VERSION "HNNBNNNYNNNNNNNNNNNNNNNNNNNNNNNNNNNNNNNNNN/4/%%%/4/'%**4NNN///"

NS_ :

BS_:

BU_: Airbag_MQB BAP_Tester_MQB BMS_MQB Datenlogger_MQB Gateway_MQB Getriebe_DQ_Hybrid_MQB Getriebe_DQ_MQB LEH_MQB Motor_Diesel_MQB Motor_Hybrid_MQB Motor_Otto_MQB SAK_MQB Waehlhebel_MQB

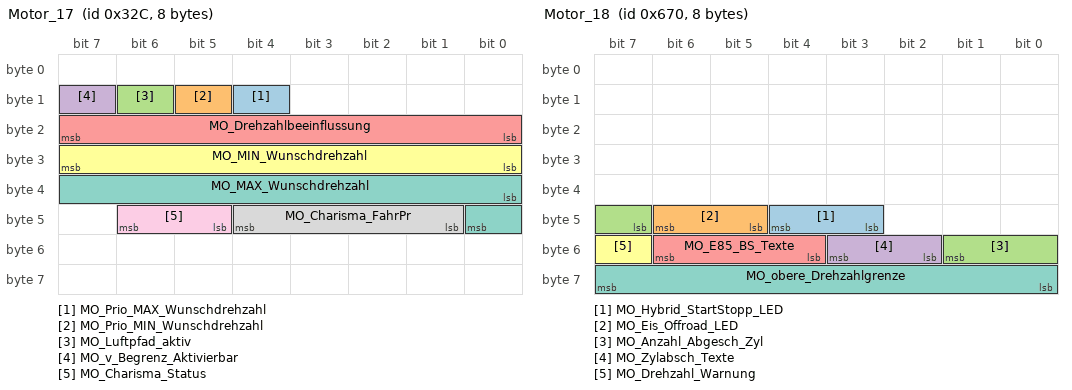
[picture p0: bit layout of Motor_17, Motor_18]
BO_ 812 Motor_17: 8 Motor_Diesel_MQB
 SG_ MO_Prio_MAX_Wunschdrehzahl : 12|1@1+ (1,0) [0|1] ""  Getriebe_DQ_Hybrid_MQB,Getriebe_DQ_MQB
 SG_ MO_Prio_MIN_Wunschdrehzahl : 13|1@1+ (1,0) [0|1] ""  Getriebe_DQ_Hybrid_MQB,Getriebe_DQ_MQB
 SG_ MO_Luftpfad_aktiv : 14|1@1+ (1,0) [0|1] "" Vector__XXX
 SG_ MO_v_Begrenz_Aktivierbar : 15|1@1+ (1,0) [0|1] "" Vector__XXX
 SG_ MO_Drehzahlbeeinflussung : 16|8@1+ (0.39,0) [0|99.45] "Unit_PerCent"  Getriebe_DQ_Hybrid_MQB,Getriebe_DQ_MQB
 SG_ MO_MIN_Wunschdrehzahl : 24|8@1+ (25,0) [0|6350] "Unit_MinutInver"  Getriebe_DQ_Hybrid_MQB,Getriebe_DQ_MQB
 SG_ MO_MAX_Wunschdrehzahl : 32|9@1+ (25,0) [0|12750] "Unit_MinutInver"  Getriebe_DQ_Hybrid_MQB,Getriebe_DQ_MQB
 SG_ MO_Charisma_FahrPr : 41|4@1+ (1,0) [0|15] ""  Gateway_MQB
 SG_ MO_Charisma_Status : 45|2@1+ (1,0) [0|3] ""  Gateway_MQB

BO_ 1648 Motor_18: 8 Motor_Diesel_MQB
 SG_ MO_Hybrid_StartStopp_LED : 43|2@1+ (1,0) [0|3] ""  Gateway_MQB
 SG_ MO_Eis_Offroad_LED : 45|2@1+ (1,0) [0|3] ""  Gateway_MQB
 SG_ MO_Anzahl_Abgesch_Zyl : 47|3@1+ (1,0) [0|7] ""  Gateway_MQB
 SG_ MO_Zylabsch_Texte : 50|2@1+ (1,0) [0|3] ""  Gateway_MQB
 SG_ MO_E85_BS_Texte : 52|3@1+ (1,0) [0|7] ""  Gateway_MQB
 SG_ MO_Drehzahl_Warnung : 55|1@1+ (1,0) [0|1] ""  Gateway_MQB
 SG_ MO_obere_Drehzahlgrenze : 56|8@1+ (50,0) [50|12750] "Unit_MinutInver"  Gateway_MQB,Getriebe_DQ_Hybrid_MQB,Getriebe_DQ_MQB

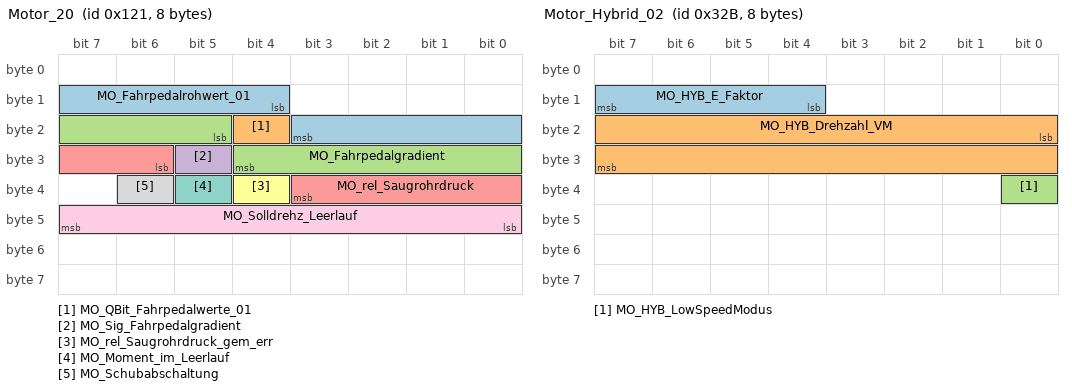
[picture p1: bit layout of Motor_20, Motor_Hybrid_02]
BO_ 289 Motor_20: 8 Motor_Diesel_MQB
 SG_ MO_Fahrpedalrohwert_01 : 12|8@1+ (0.4,0) [0|101.6] "Unit_PerCent"  Airbag_MQB,Gateway_MQB,Getriebe_DQ_Hybrid_MQB,Getriebe_DQ_MQB
 SG_ MO_QBit_Fahrpedalwerte_01 : 20|1@1+ (1,0) [0|1] ""  Airbag_MQB,Gateway_MQB,Getriebe_DQ_Hybrid_MQB,Getriebe_DQ_MQB
 SG_ MO_Fahrpedalgradient : 21|8@1+ (25,0) [0|6350] "Unit_PerCentPerSecon"  Airbag_MQB,Gateway_MQB,Getriebe_DQ_Hybrid_MQB,Getriebe_DQ_MQB
 SG_ MO_Sig_Fahrpedalgradient : 29|1@1+ (1,0) [0|1] ""  Airbag_MQB,Gateway_MQB,Getriebe_DQ_Hybrid_MQB,Getriebe_DQ_MQB
 SG_ MO_rel_Saugrohrdruck : 30|6@1+ (18,0) [0|1116] "Unit_MilliBar"  Gateway_MQB
 SG_ MO_rel_Saugrohrdruck_gem_err : 36|1@1+ (1,0) [0|1] ""  Gateway_MQB
 SG_ MO_Moment_im_Leerlauf : 37|1@1+ (1,0) [0|1] ""  Gateway_MQB,Getriebe_DQ_Hybrid_MQB,Getriebe_DQ_MQB
 SG_ MO_Schubabschaltung : 38|1@1+ (1,0) [0|1] ""  Gateway_MQB
 SG_ MO_Solldrehz_Leerlauf : 40|8@1+ (10,0) [0|2540] "Unit_MinutInver"  Gateway_MQB,Getriebe_DQ_Hybrid_MQB,Getriebe_DQ_MQB

BO_ 967 Motor_26: 8 Motor_Diesel_MQB
 SG_ MO_Kuehlerluefter_MUX M : 0|1@1+ (1,0) [0|1] ""  Gateway_MQB,Getriebe_DQ_Hybrid_MQB,Getriebe_DQ_MQB
 SG_ MO_Kuehlerluefter_1 m0 : 1|7@1+ (1,0) [0|100] "Unit_PerCent"  Gateway_MQB,Getriebe_DQ_Hybrid_MQB,Getriebe_DQ_MQB
 SG_ MO_Kuehlerluefter_2 m1 : 1|7@1+ (1,0) [0|100] "Unit_PerCent"  Gateway_MQB,Getriebe_DQ_Hybrid_MQB,Getriebe_DQ_MQB
 SG_ MO_HYB_Status_HV_Ladung : 8|3@1+ (1,0) [0|7] ""  Gateway_MQB
 SG_ WIV_Anzeige_aktiv : 12|1@1+ (1,0) [0|1] ""  Gateway_MQB
 SG_ WIV_Oelmin_Warn : 13|1@1+ (1,0) [0|1] ""  Gateway_MQB
 SG_ WIV_Sensorfehler : 14|1@1+ (1,0) [0|1] ""  Gateway_MQB
 SG_ WIV_Schieflage : 15|1@1+ (1,0) [0|1] ""  Gateway_MQB
 SG_ WIV_Oelstand : 16|4@1+ (12.5,0) [0|100] "Unit_PerCent"  Gateway_MQB
 SG_ MO_Zustand_HWP : 20|2@1+ (1,0) [0|3] ""  Gateway_MQB
 SG_ WIV_Oelsystem_aktiv : 24|1@1+ (1,0) [0|1] ""  Gateway_MQB
 SG_ WIV_nicht_betriebswarm : 25|1@1+ (1,0) [0|1] ""  Gateway_MQB
 SG_ WIV_Ueberfuell_Warn : 26|1@1+ (1,0) [0|1] ""  Gateway_MQB
 SG_ WIV_laufender_Motor : 27|1@1+ (1,0) [0|1] ""  Gateway_MQB
 SG_ MO_HYB_Text_1 : 28|1@1+ (1,0) [0|1] ""  Gateway_MQB
 SG_ MO_HYB_Text_2 : 29|1@1+ (1,0) [0|1] ""  Gateway_MQB
 SG_ MO_HYB_Text_3 : 30|1@1+ (1,0) [0|1] ""  Gateway_MQB
 SG_ MO_HYB_Text_4 : 31|1@1+ (1,0) [0|1] ""  Gateway_MQB
 SG_ MO_Text_Motorstart : 32|4@1+ (1,0) [0|15] ""  Gateway_MQB
 SG_ MO_HYB_Text_5 : 36|1@1+ (1,0) [0|1] ""  Gateway_MQB
 SG_ MO_HYB_Text_6 : 37|1@1+ (1,0) [0|1] ""  Gateway_MQB
 SG_ MO_HYB_Text_7 : 38|1@1+ (1,0) [0|1] ""  Gateway_MQB
 SG_ MO_Text_Partikelfil_Reg : 41|1@1+ (1,0) [0|1] ""  Gateway_MQB
 SG_ WIV_Oelmenge : 43|5@1+ (125,0) [0|3875] "Unit_MilliLiter"  Gateway_MQB
 SG_ MO_Systemlampe : 48|1@1+ (1,0) [0|1] ""  Gateway_MQB
 SG_ MO_OBD2_Lampe : 49|1@1+ (1,0) [0|1] ""  Gateway_MQB
 SG_ MO_Heissleuchte : 50|1@1+ (1,0) [0|1] ""  Gateway_MQB
 SG_ MO_Partikel_Lampe : 51|1@1+ (1,0) [0|1] ""  Gateway_MQB
 SG_ MO_Winterfahrprog : 52|1@1+ (1,0) [0|1] ""  Gateway_MQB,Getriebe_DQ_Hybrid_MQB,Getriebe_DQ_MQB
 SG_ WIV_Oelstand_nicht_vorhanden : 53|1@1+ (1,0) [0|1] ""  Gateway_MQB
 SG_ WIV_nachfuellanzeige_ein : 54|1@1+ (1,0) [0|1] ""  Gateway_MQB
 SG_ WIV_Ueberfuell_deaktiv : 55|1@1+ (1,0) [0|1] ""  Gateway_MQB
 SG_ WIV_Unterfuell_Warn : 56|1@1+ (1,0) [0|1] ""  Gateway_MQB
 SG_ MO_Tankdeckel_Lampe : 57|1@1+ (1,0) [0|1] ""  Gateway_MQB
 SG_ MO_Text_Tankdeckelwarn : 58|1@1+ (1,0) [0|1] ""  Gateway_MQB
 SG_ WIV_Oeldr_Warn_Motor : 60|1@1+ (1,0) [0|1] ""  Gateway_MQB

BO_ 1601 Motor_Code_01: 8 Motor_Diesel_MQB
 SG_ Motor_Code_01_CRC : 0|8@1+ (1,0) [0|255] ""  Gateway_MQB
 SG_ Motor_Code_01_BZ : 8|4@1+ (1,0) [0|15] ""  Gateway_MQB
 SG_ MO_Faktor_Momente_02 : 12|2@1+ (1,0) [0|3] ""  Gateway_MQB,Getriebe_DQ_Hybrid_MQB,Getriebe_DQ_MQB
 SG_ MO_Hybridfahrzeug : 14|2@1+ (1,0) [0|3] ""  Gateway_MQB
 SG_ MO_Code : 16|8@1+ (1,0) [0|255] ""  Gateway_MQB,SAK_MQB
 SG_ MO_Getriebe_Code : 24|6@1+ (1,0) [0|63] ""  Gateway_MQB
 SG_ MO_StartStopp_Codiert : 30|1@1+ (1,0) [0|1] ""  Gateway_MQB
 SG_ MO_Anzahl_Zyl : 32|4@1+ (1,0) [0|15] ""  Gateway_MQB
 SG_ MO_Kraftstoffart : 36|4@1+ (1,0) [0|15] ""  Gateway_MQB,Getriebe_DQ_Hybrid_MQB,Getriebe_DQ_MQB
 SG_ MO_Hubraum : 40|7@1+ (0.1,0) [0|12.7] "Unit_Liter"  Gateway_MQB
 SG_ MO_Ansaugsystem : 47|1@1+ (1,0) [0|1] ""  Gateway_MQB
 SG_ MO_Leistung : 48|9@1+ (1,0) [0|511] "Unit_KiloWatt"  Gateway_MQB
 SG_ MO_Abgastyp_EOBD : 57|1@1+ (1,0) [0|1] ""  BMS_MQB,Gateway_MQB,LEH_MQB
 SG_ MO_Abgastyp_OBD : 58|1@1+ (1,0) [0|1] ""  BMS_MQB,Gateway_MQB,LEH_MQB
 SG_ MO_DPF_verbaut : 59|1@1+ (1,0) [0|1] ""  Gateway_MQB
 SG_ TSK_Codierung : 60|3@1+ (1,0) [0|7] ""  Gateway_MQB,Getriebe_DQ_Hybrid_MQB,Getriebe_DQ_MQB
 SG_ MO_Einspritzart : 63|1@1+ (1,0) [0|1] ""  Gateway_MQB

BO_ 157 Motor_Hybrid_01: 8 Motor_Hybrid_MQB
 SG_ Motor_Hybrid_01_CRC : 0|8@1+ (1,0) [0|255] ""  Getriebe_DQ_Hybrid_MQB
 SG_ Motor_Hybrid_01_BZ : 8|4@1+ (1,0) [0|15] ""  BMS_MQB,Getriebe_DQ_Hybrid_MQB
 SG_ MO_HYB_IstStatusK0 : 12|2@1+ (1,0) [0|3] ""  Getriebe_DQ_Hybrid_MQB
 SG_ MO_HYB_max_ind_VM_Mom : 16|10@1+ (1,0) [0|1021] "Unit_NewtoMeter"  Getriebe_DQ_Hybrid_MQB
 SG_ MO_HYB_Zielzustand : 26|3@1+ (1,0) [0|7] ""  BMS_MQB,Getriebe_DQ_Hybrid_MQB
 SG_ MO_HYB_Startmodus : 29|3@1+ (1,0) [0|7] "" Vector__XXX
 SG_ MO_HYB_Startmodus_PQ3x : 32|1@1+ (1,0) [0|1] ""  Getriebe_DQ_Hybrid_MQB
 SG_ MO_HYB_Stoppmodus : 33|1@1+ (1,0) [0|1] ""  Getriebe_DQ_Hybrid_MQB
 SG_ MO_HYB_VM_Mom_oE : 40|10@1+ (1,-100) [-100|922] "Unit_NewtoMeter"  Getriebe_DQ_Hybrid_MQB
 SG_ MO_HYB_VM_aktiv : 50|1@1+ (1,0) [0|1] ""  Getriebe_DQ_Hybrid_MQB
 SG_ MO_HYB_Schaltverhinderung : 51|1@1+ (1,0) [0|1] ""  Getriebe_DQ_Hybrid_MQB
 SG_ MO_HYB_Selektor_Momverlauf_EM M : 53|3@1+ (1,0) [0|7] ""  Getriebe_DQ_Hybrid_MQB
 SG_ MO_HYB_Momverlauf_Rek m1 : 56|8@1+ (2,0) [0|510] "Unit_NewtoMeter"  Getriebe_DQ_Hybrid_MQB
 SG_ MO_HYB_KnickDZ_Rek m2 : 56|8@1+ (12.5,0) [0|3150] "Unit_MinutInver"  Getriebe_DQ_Hybrid_MQB
 SG_ MO_HYB_Momverlauf_EM m3 : 56|8@1+ (2,0) [0|510] "Unit_NewtoMeter"  Getriebe_DQ_Hybrid_MQB
 SG_ MO_HYB_KnickDZ_EM m4 : 56|8@1+ (12.5,0) [0|3150] "Unit_MinutInver"  Getriebe_DQ_Hybrid_MQB

BO_ 811 Motor_Hybrid_02: 8 Motor_Hybrid_MQB
 SG_ MO_HYB_E_Faktor : 12|4@1+ (1,0) [0|15] ""  Getriebe_DQ_Hybrid_MQB
 SG_ MO_HYB_Drehzahl_VM : 16|16@1+ (0.25,0) [0|16256] "Unit_MinutInver"  Getriebe_DQ_Hybrid_MQB
 SG_ MO_HYB_LowSpeedModus : 32|1@1+ (1,0) [0|1] ""  Getriebe_DQ_Hybrid_MQB

BO_ 16 MSG1_WFS_Anfrage: 8 Motor_Diesel_MQB
 SG_ WFS_MSG1_RND : 0|32@1+ (1,0) [0|4294967295] ""  Gateway_MQB
 SG_ WFS_MSG1_CRC : 32|32@1+ (1,0) [0|4294967295] ""  Gateway_MQB

BO_ 20 MSG2_WFS_Anfrage: 8 Vector__XXX
 SG_ WFS_MSG2_RND : 0|32@1+ (1,0) [0|4294967295] ""  Gateway_MQB
 SG_ WFS_MSG2_CRC : 32|32@1+ (1,0) [0|4294967295] ""  Gateway_MQB

BO_ 22 MSG3_WFS_Anfrage: 8 Vector__XXX
 SG_ WFS_MSG3_RND : 0|32@1+ (1,0) [0|4294967295] ""  Gateway_MQB
 SG_ WFS_MSG3_CRC : 32|32@1+ (1,0) [0|4294967295] ""  Gateway_MQB

BO_ 24 MSG4_WFS_Anfrage: 8 LEH_MQB
 SG_ WFS_MSG4_RND : 0|32@1+ (1,0) [0|4294967295] ""  Gateway_MQB
 SG_ WFS_MSG4_CRC : 32|32@1+ (1,0) [0|4294967295] ""  Gateway_MQB

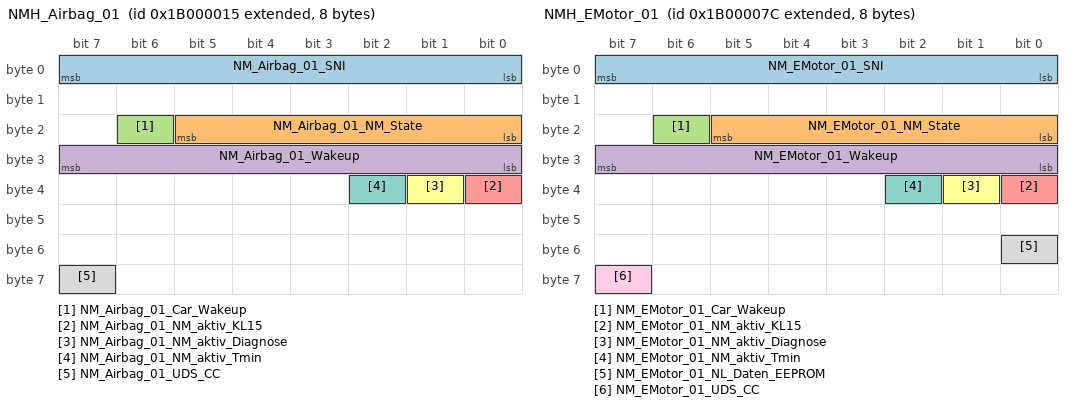
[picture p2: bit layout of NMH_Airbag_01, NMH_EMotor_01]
BO_ 2600468501 NMH_Airbag_01: 8 Airbag_MQB
 SG_ NM_Airbag_01_SNI : 0|8@1+ (1,0) [0|255] "" Vector__XXX
 SG_ NM_Airbag_01_NM_State : 16|6@1+ (1,0) [0|63] ""  BMS_MQB,Getriebe_DQ_Hybrid_MQB,Getriebe_DQ_MQB,LEH_MQB,Motor_Diesel_MQB,Motor_Hybrid_MQB,Motor_Otto_MQB
 SG_ NM_Airbag_01_Car_Wakeup : 22|1@1+ (1,0) [0|1] ""  Gateway_MQB
 SG_ NM_Airbag_01_Wakeup : 24|8@1+ (1,0) [0|255] "" Vector__XXX
 SG_ NM_Airbag_01_NM_aktiv_KL15 : 32|1@1+ (1,0) [0|1] "" Vector__XXX
 SG_ NM_Airbag_01_NM_aktiv_Diagnose : 33|1@1+ (1,0) [0|1] "" Vector__XXX
 SG_ NM_Airbag_01_NM_aktiv_Tmin : 34|1@1+ (1,0) [0|1] "" Vector__XXX
 SG_ NM_Airbag_01_UDS_CC : 63|1@1+ (1,0) [0|1] "" Vector__XXX

BO_ 2600468604 NMH_EMotor_01: 8 LEH_MQB
 SG_ NM_EMotor_01_SNI : 0|8@1+ (1,0) [0|255] "" Vector__XXX
 SG_ NM_EMotor_01_NM_State : 16|6@1+ (1,0) [0|63] ""  BMS_MQB,Getriebe_DQ_Hybrid_MQB,Getriebe_DQ_MQB,LEH_MQB,Motor_Diesel_MQB,Motor_Hybrid_MQB,Motor_Otto_MQB
 SG_ NM_EMotor_01_Car_Wakeup : 22|1@1+ (1,0) [0|1] ""  Gateway_MQB
 SG_ NM_EMotor_01_Wakeup : 24|8@1+ (1,0) [0|255] "" Vector__XXX
 SG_ NM_EMotor_01_NM_aktiv_KL15 : 32|1@1+ (1,0) [0|1] "" Vector__XXX
 SG_ NM_EMotor_01_NM_aktiv_Diagnose : 33|1@1+ (1,0) [0|1] "" Vector__XXX
 SG_ NM_EMotor_01_NM_aktiv_Tmin : 34|1@1+ (1,0) [0|1] "" Vector__XXX
 SG_ NM_EMotor_01_NL_Daten_EEPROM : 48|1@1+ (1,0) [0|1] "" Vector__XXX
 SG_ NM_EMotor_01_UDS_CC : 63|1@1+ (1,0) [0|1] "" Vector__XXX

BO_ 2600468496 NMH_Gateway: 8 Gateway_MQB
 SG_ NM_Gateway_SNI : 0|8@1+ (1,0) [0|255] "" Vector__XXX
 SG_ NM_Gateway_NM_State : 16|6@1+ (1,0) [0|63] ""  BMS_MQB,Getriebe_DQ_Hybrid_MQB,Getriebe_DQ_MQB,LEH_MQB,Motor_Diesel_MQB,Motor_Hybrid_MQB,Motor_Otto_MQB
 SG_ NM_Gateway_Car_Wakeup : 22|1@1+ (1,0) [0|1] "" Vector__XXX
 SG_ NM_Gateway_Wakeup : 24|8@1+ (1,0) [0|255] "" Vector__XXX
 SG_ NM_Gateway_NM_aktiv_KL15 : 32|1@1+ (1,0) [0|1] "" Vector__XXX
 SG_ NM_Gateway_NM_aktiv_Diagnose : 33|1@1+ (1,0) [0|1] "" Vector__XXX
 SG_ NM_Gateway_NM_aktiv_Tmin : 34|1@1+ (1,0) [0|1] "" Vector__XXX
 SG_ NM_Gateway_ACAN_Aktivitaet : 35|1@1+ (1,0) [0|1] "" Vector__XXX
 SG_ NM_Gateway_FCAN_Aktivitaet : 36|1@1+ (1,0) [0|1] "" Vector__XXX
 SG_ NM_Gateway_KCAN_Aktivitaet : 37|1@1+ (1,0) [0|1] "" Vector__XXX
 SG_ NM_Gateway_ICAN_Aktivitaet : 38|1@1+ (1,0) [0|1] "" Vector__XXX
 SG_ NM_Gateway_DiagCAN_Aktivitaet : 39|1@1+ (1,0) [0|1] "" Vector__XXX
 SG_ NM_Gateway_ECAN_Aktivitaet : 40|1@1+ (1,0) [0|1] "" Vector__XXX
 SG_ NM_Gateway_Energie_LIN_Aktivi000 : 41|1@1+ (1,0) [0|1] "" Vector__XXX
 SG_ NM_Gateway_Bedien_LIN_Aktivitaet : 42|1@1+ (1,0) [0|1] "" Vector__XXX
 SG_ NM_Gateway_EM_Aktivitaet : 43|1@1+ (1,0) [0|1] "" Vector__XXX
 SG_ NM_Gateway_NL_EM : 48|1@1+ (1,0) [0|1] "" Vector__XXX
 SG_ NM_Gateway_NL_Shutdown : 49|1@1+ (1,0) [0|1] "" Vector__XXX
 SG_ NM_Gateway_NL_Spg_Messung : 50|1@1+ (1,0) [0|1] "" Vector__XXX
 SG_ NM_Gateway_NL_Wakeup_Monitor : 51|1@1+ (1,0) [0|1] "" Vector__XXX
 SG_ NM_Gateway_UDS_CC : 63|1@1+ (1,0) [0|1] "" Vector__XXX

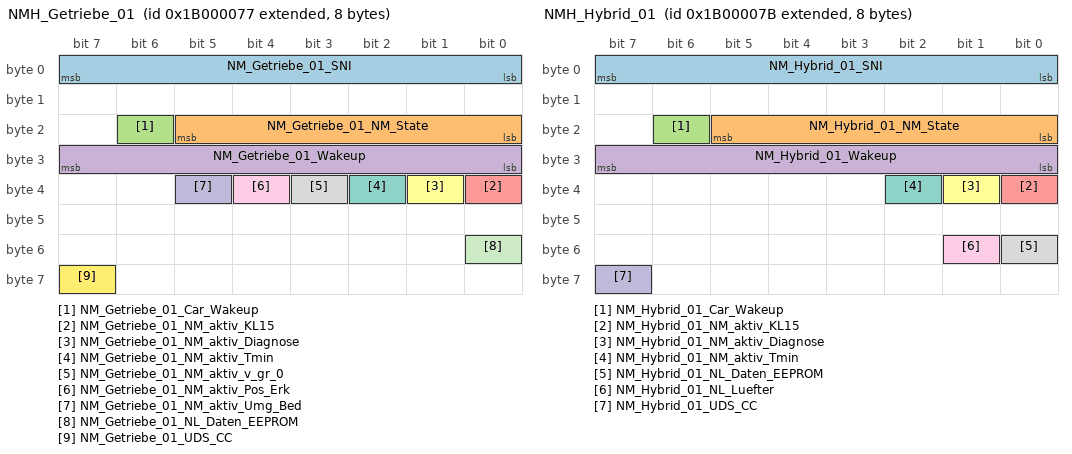
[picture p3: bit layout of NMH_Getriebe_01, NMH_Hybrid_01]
BO_ 2600468599 NMH_Getriebe_01: 8 Getriebe_DQ_Hybrid_MQB
 SG_ NM_Getriebe_01_SNI : 0|8@1+ (1,0) [0|255] "" Vector__XXX
 SG_ NM_Getriebe_01_NM_State : 16|6@1+ (1,0) [0|63] ""  BMS_MQB,Getriebe_DQ_Hybrid_MQB,Getriebe_DQ_MQB,LEH_MQB,Motor_Diesel_MQB,Motor_Hybrid_MQB,Motor_Otto_MQB
 SG_ NM_Getriebe_01_Car_Wakeup : 22|1@1+ (1,0) [0|1] ""  Gateway_MQB
 SG_ NM_Getriebe_01_Wakeup : 24|8@1+ (1,0) [0|255] "" Vector__XXX
 SG_ NM_Getriebe_01_NM_aktiv_KL15 : 32|1@1+ (1,0) [0|1] "" Vector__XXX
 SG_ NM_Getriebe_01_NM_aktiv_Diagnose : 33|1@1+ (1,0) [0|1] "" Vector__XXX
 SG_ NM_Getriebe_01_NM_aktiv_Tmin : 34|1@1+ (1,0) [0|1] "" Vector__XXX
 SG_ NM_Getriebe_01_NM_aktiv_v_gr_0 : 35|1@1+ (1,0) [0|1] "" Vector__XXX
 SG_ NM_Getriebe_01_NM_aktiv_Pos_Erk : 36|1@1+ (1,0) [0|1] "" Vector__XXX
 SG_ NM_Getriebe_01_NM_aktiv_Umg_Bed : 37|1@1+ (1,0) [0|1] "" Vector__XXX
 SG_ NM_Getriebe_01_NL_Daten_EEPROM : 48|1@1+ (1,0) [0|1] "" Vector__XXX
 SG_ NM_Getriebe_01_UDS_CC : 63|1@1+ (1,0) [0|1] "" Vector__XXX

BO_ 2600468603 NMH_Hybrid_01: 8 BMS_MQB
 SG_ NM_Hybrid_01_SNI : 0|8@1+ (1,0) [0|255] "" Vector__XXX
 SG_ NM_Hybrid_01_NM_State : 16|6@1+ (1,0) [0|63] ""  BMS_MQB,Getriebe_DQ_Hybrid_MQB,Getriebe_DQ_MQB,LEH_MQB,Motor_Diesel_MQB,Motor_Hybrid_MQB,Motor_Otto_MQB
 SG_ NM_Hybrid_01_Car_Wakeup : 22|1@1+ (1,0) [0|1] ""  Gateway_MQB
 SG_ NM_Hybrid_01_Wakeup : 24|8@1+ (1,0) [0|255] "" Vector__XXX
 SG_ NM_Hybrid_01_NM_aktiv_KL15 : 32|1@1+ (1,0) [0|1] "" Vector__XXX
 SG_ NM_Hybrid_01_NM_aktiv_Diagnose : 33|1@1+ (1,0) [0|1] "" Vector__XXX
 SG_ NM_Hybrid_01_NM_aktiv_Tmin : 34|1@1+ (1,0) [0|1] "" Vector__XXX
 SG_ NM_Hybrid_01_NL_Daten_EEPROM : 48|1@1+ (1,0) [0|1] "" Vector__XXX
 SG_ NM_Hybrid_01_NL_Luefter : 49|1@1+ (1,0) [0|1] "" Vector__XXX
 SG_ NM_Hybrid_01_UDS_CC : 63|1@1+ (1,0) [0|1] "" Vector__XXX

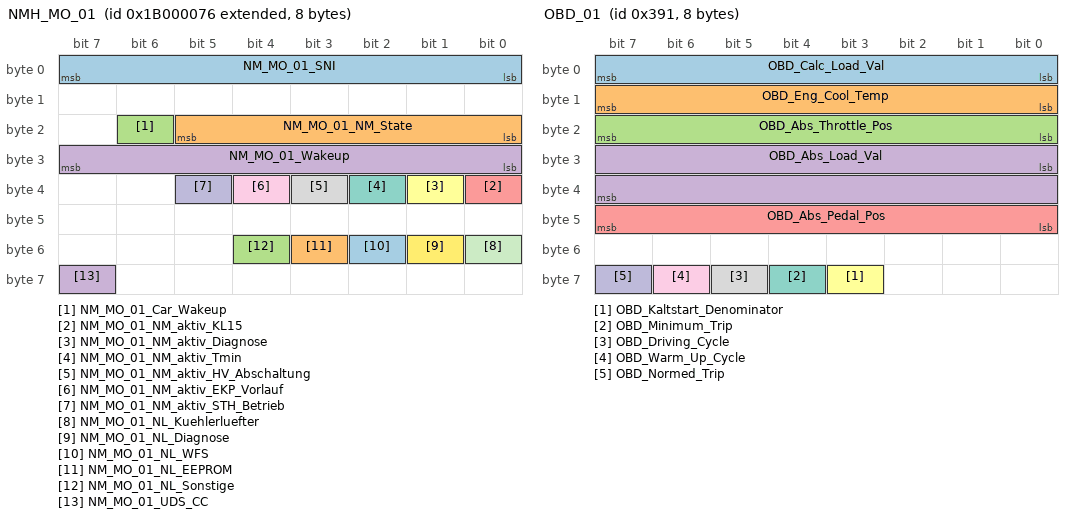
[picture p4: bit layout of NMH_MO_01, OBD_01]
BO_ 2600468598 NMH_MO_01: 8 Motor_Diesel_MQB
 SG_ NM_MO_01_SNI : 0|8@1+ (1,0) [0|255] "" Vector__XXX
 SG_ NM_MO_01_NM_State : 16|6@1+ (1,0) [0|63] ""  BMS_MQB,Getriebe_DQ_Hybrid_MQB,Getriebe_DQ_MQB,LEH_MQB,Motor_Diesel_MQB,Motor_Hybrid_MQB,Motor_Otto_MQB
 SG_ NM_MO_01_Car_Wakeup : 22|1@1+ (1,0) [0|1] ""  Gateway_MQB
 SG_ NM_MO_01_Wakeup : 24|8@1+ (1,0) [0|255] "" Vector__XXX
 SG_ NM_MO_01_NM_aktiv_KL15 : 32|1@1+ (1,0) [0|1] "" Vector__XXX
 SG_ NM_MO_01_NM_aktiv_Diagnose : 33|1@1+ (1,0) [0|1] "" Vector__XXX
 SG_ NM_MO_01_NM_aktiv_Tmin : 34|1@1+ (1,0) [0|1] "" Vector__XXX
 SG_ NM_MO_01_NM_aktiv_HV_Abschaltung : 35|1@1+ (1,0) [0|1] "" Vector__XXX
 SG_ NM_MO_01_NM_aktiv_EKP_Vorlauf : 36|1@1+ (1,0) [0|1] "" Vector__XXX
 SG_ NM_MO_01_NM_aktiv_STH_Betrieb : 37|1@1+ (1,0) [0|1] "" Vector__XXX
 SG_ NM_MO_01_NL_Kuehlerluefter : 48|1@1+ (1,0) [0|1] "" Vector__XXX
 SG_ NM_MO_01_NL_Diagnose : 49|1@1+ (1,0) [0|1] "" Vector__XXX
 SG_ NM_MO_01_NL_WFS : 50|1@1+ (1,0) [0|1] "" Vector__XXX
 SG_ NM_MO_01_NL_EEPROM : 51|1@1+ (1,0) [0|1] "" Vector__XXX
 SG_ NM_MO_01_NL_Sonstige : 52|1@1+ (1,0) [0|1] "" Vector__XXX
 SG_ NM_MO_01_UDS_CC : 63|1@1+ (1,0) [0|1] "" Vector__XXX

BO_ 913 OBD_01: 8 Motor_Diesel_MQB
 SG_ OBD_Calc_Load_Val : 0|8@1+ (0.39215686275,0) [0|100] "Unit_PerCent"  BMS_MQB,Getriebe_DQ_Hybrid_MQB,Getriebe_DQ_MQB,LEH_MQB
 SG_ OBD_Eng_Cool_Temp : 8|8@1+ (1,-40) [-40|215] "Unit_DegreCelsi"  BMS_MQB,Getriebe_DQ_Hybrid_MQB,Getriebe_DQ_MQB,LEH_MQB
 SG_ OBD_Abs_Throttle_Pos : 16|8@1+ (0.39215686275,0) [0|100] "Unit_PerCent"  BMS_MQB,Getriebe_DQ_Hybrid_MQB,Getriebe_DQ_MQB,LEH_MQB
 SG_ OBD_Abs_Load_Val : 24|16@1+ (0.39215686275,0) [0|25700] "Unit_PerCent"  BMS_MQB,Getriebe_DQ_Hybrid_MQB,Getriebe_DQ_MQB,LEH_MQB
 SG_ OBD_Abs_Pedal_Pos : 40|8@1+ (0.39215686275,0) [0|100] "Unit_PerCent"  BMS_MQB,Getriebe_DQ_Hybrid_MQB,Getriebe_DQ_MQB,LEH_MQB
 SG_ OBD_Kaltstart_Denominator : 59|1@1+ (1,0) [0|1] ""  BMS_MQB,LEH_MQB
 SG_ OBD_Minimum_Trip : 60|1@1+ (1,0) [0|1] ""  BMS_MQB,Getriebe_DQ_Hybrid_MQB,Getriebe_DQ_MQB,LEH_MQB
 SG_ OBD_Driving_Cycle : 61|1@1+ (1,0) [0|1] ""  BMS_MQB,Getriebe_DQ_Hybrid_MQB,Getriebe_DQ_MQB,LEH_MQB
 SG_ OBD_Warm_Up_Cycle : 62|1@1+ (1,0) [0|1] ""  BMS_MQB,Gateway_MQB,Getriebe_DQ_Hybrid_MQB,Getriebe_DQ_MQB,LEH_MQB
 SG_ OBD_Normed_Trip : 63|1@1+ (1,0) [0|1] ""  BMS_MQB,Getriebe_DQ_Hybrid_MQB,Getriebe_DQ_MQB,LEH_MQB

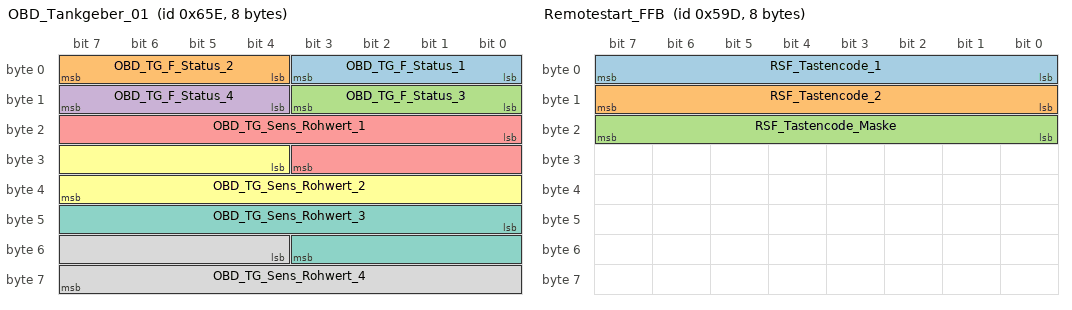
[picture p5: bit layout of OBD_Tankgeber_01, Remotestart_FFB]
BO_ 1630 OBD_Tankgeber_01: 8 Gateway_MQB
 SG_ OBD_TG_F_Status_1 : 0|4@1+ (1,0) [0|15] ""  Motor_Hybrid_MQB,Motor_Otto_MQB
 SG_ OBD_TG_F_Status_2 : 4|4@1+ (1,0) [0|15] ""  Motor_Hybrid_MQB,Motor_Otto_MQB
 SG_ OBD_TG_F_Status_3 : 8|4@1+ (1,0) [0|15] ""  Motor_Hybrid_MQB,Motor_Otto_MQB
 SG_ OBD_TG_F_Status_4 : 12|4@1+ (1,0) [0|15] ""  Motor_Hybrid_MQB,Motor_Otto_MQB
 SG_ OBD_TG_Sens_Rohwert_1 : 16|12@1+ (0.5,0) [0|2047.5] "Unit_Ohm"  Motor_Hybrid_MQB,Motor_Otto_MQB
 SG_ OBD_TG_Sens_Rohwert_2 : 28|12@1+ (0.5,0) [0|2047.5] "Unit_Ohm"  Motor_Hybrid_MQB,Motor_Otto_MQB
 SG_ OBD_TG_Sens_Rohwert_3 : 40|12@1+ (0.5,0) [0|2047.5] "Unit_Ohm"  Motor_Hybrid_MQB,Motor_Otto_MQB
 SG_ OBD_TG_Sens_Rohwert_4 : 52|12@1+ (0.5,0) [0|2047.5] "Unit_Ohm"  Motor_Hybrid_MQB,Motor_Otto_MQB

BO_ 1437 Remotestart_FFB: 8 Gateway_MQB
 SG_ RSF_Tastencode_1 : 0|8@1+ (1,0) [0|255] ""  Motor_Diesel_MQB,Motor_Otto_MQB
 SG_ RSF_Tastencode_2 : 8|8@1+ (1,0) [0|255] ""  Motor_Diesel_MQB,Motor_Otto_MQB
 SG_ RSF_Tastencode_Maske : 16|8@1+ (1,0) [0|255] ""  Motor_Diesel_MQB,Motor_Otto_MQB

BO_ 2033 Request_Airbag_Deployment: 8 Gateway_MQB
 SG_ Request_Airbag_Deployment : 0|64@1+ (1,0) [0|4294967295] ""  Airbag_MQB

BO_ 2041 Response_Airbag_Deployment: 8 Airbag_MQB
 SG_ Response_Airbag_Deployment : 0|64@1+ (1,0) [0|4294967295] ""  Gateway_MQB

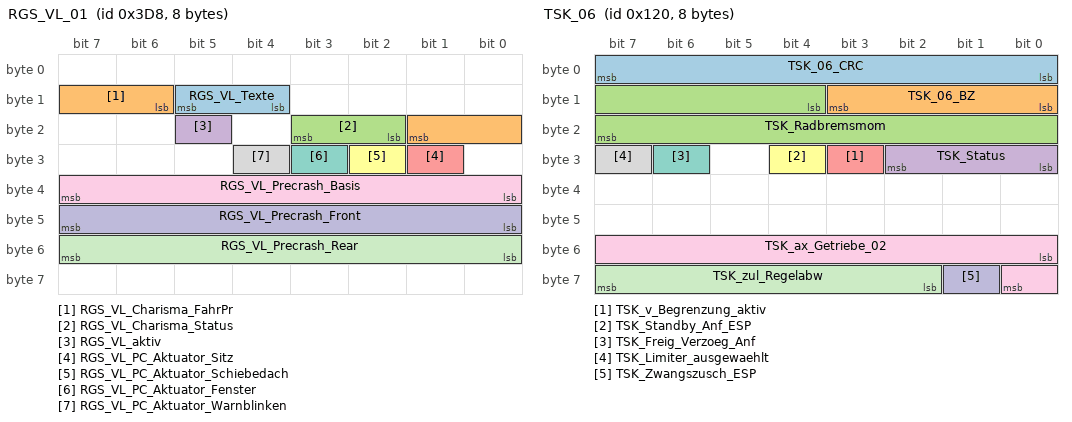
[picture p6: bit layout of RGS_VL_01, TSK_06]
BO_ 984 RGS_VL_01: 8 Airbag_MQB
 SG_ RGS_VL_Texte : 12|2@1+ (1,0) [0|3] ""  Gateway_MQB
 SG_ RGS_VL_Charisma_FahrPr : 14|4@1+ (1,0) [0|15] ""  Gateway_MQB
 SG_ RGS_VL_Charisma_Status : 18|2@1+ (1,0) [0|3] ""  Gateway_MQB
 SG_ RGS_VL_aktiv : 21|1@1+ (1,0) [0|1] ""  Gateway_MQB
 SG_ RGS_VL_PC_Aktuator_Sitz : 25|1@1+ (1,0) [0|1] ""  Gateway_MQB
 SG_ RGS_VL_PC_Aktuator_Schiebedach : 26|1@1+ (1,0) [0|1] ""  Gateway_MQB
 SG_ RGS_VL_PC_Aktuator_Fenster : 27|1@1+ (1,0) [0|1] ""  Gateway_MQB
 SG_ RGS_VL_PC_Aktuator_Warnblinken : 28|1@1+ (1,0) [0|1] ""  Gateway_MQB
 SG_ RGS_VL_Precrash_Basis : 32|8@1+ (1,0) [0|255] ""  Gateway_MQB
 SG_ RGS_VL_Precrash_Front : 40|8@1+ (1,0) [0|255] ""  Gateway_MQB
 SG_ RGS_VL_Precrash_Rear : 48|8@1+ (1,0) [0|255] ""  Gateway_MQB

BO_ 1528 SAK_01: 8 SAK_MQB
 SG_ SAK_Charisma_FahrPr : 16|4@1+ (1,0) [0|15] ""  Gateway_MQB
 SG_ SAK_Charisma_Status : 20|2@1+ (1,0) [0|3] ""  Gateway_MQB

BO_ 1313 STH_01: 8 Gateway_MQB
 SG_ STH_Funk_ein : 0|1@1+ (1,0) [0|1] "" Vector__XXX
 SG_ STH_Funk_aus : 1|1@1+ (1,0) [0|1] "" Vector__XXX
 SG_ STH_Zusatzheizung : 2|1@1+ (1,0) [0|1] "" Vector__XXX
 SG_ STH_LED : 3|1@1+ (1,0) [0|1] ""  Motor_Diesel_MQB,Motor_Hybrid_MQB,Motor_Otto_MQB
 SG_ STH_Pumpe_ein : 4|1@1+ (1,0) [0|1] "" Vector__XXX
 SG_ STH_Geblaese : 5|1@1+ (1,0) [0|1] "" Vector__XXX
 SG_ STH_EKP_Anst : 6|1@1+ (1,0) [0|1] ""  Motor_Diesel_MQB,Motor_Hybrid_MQB,Motor_Otto_MQB
 SG_ STH_Start_folgt : 7|1@1+ (1,0) [0|1] "" Vector__XXX
 SG_ STH_Ventiloeffnungszeit : 8|6@1+ (1,0) [0|63] "Unit_Minut" Vector__XXX
 SG_ STH_Ventil_Status : 14|1@1+ (1,0) [0|1] "" Vector__XXX
 SG_ STH_Waermeeintrag : 16|6@1+ (1,0) [0|63] "" Vector__XXX
 SG_ STH_KVS : 24|13@1+ (1,0) [0|8191] "Unit_MilliLiter" Vector__XXX
 SG_ STH_Fehlerstatus : 37|3@1+ (1,0) [0|7] "" Vector__XXX
 SG_ STH_Heizleistung : 40|8@1+ (1,0) [0|255] "" Vector__XXX
 SG_ STH_Wassertemp : 48|8@1+ (0.75,-40) [-40|142.25] "Unit_DegreCelsi" Vector__XXX
 SG_ STH_Motorvorwaermung : 59|1@1+ (1,0) [0|1] ""  Motor_Diesel_MQB,Motor_Hybrid_MQB,Motor_Otto_MQB
 SG_ STH_Servicemode : 60|1@1+ (1,0) [0|1] "" Vector__XXX
 SG_ STH_war_aktiv : 61|1@1+ (1,0) [0|1] ""  Motor_Diesel_MQB,Motor_Hybrid_MQB,Motor_Otto_MQB
 SG_ STH_KVS_Ueberlauf : 62|1@1+ (1,0) [0|1] "" Vector__XXX
 SG_ STH_KD_Fehler : 63|1@1+ (1,0) [0|1] "" Vector__XXX

BO_ 1172 STS_01: 8 Gateway_MQB
 SG_ STS_01_CRC : 0|8@1+ (1,0) [0|255] ""  Motor_Diesel_MQB,Motor_Hybrid_MQB,Motor_Otto_MQB
 SG_ STS_01_BZ : 8|4@1+ (1,0) [0|15] ""  Motor_Diesel_MQB,Motor_Hybrid_MQB,Motor_Otto_MQB
 SG_ STS_Car_not_under_theft : 12|1@1+ (1,0) [0|1] "" Vector__XXX
 SG_ STS_Car_under_theft : 13|1@1+ (1,0) [0|1] "" Vector__XXX
 SG_ STS_Anlassersperre : 15|1@1+ (1,0) [0|1] "" Vector__XXX
 SG_ STS_Typencodierung : 16|5@1+ (1,0) [0|31] "" Vector__XXX
 SG_ STS_LIN_aktiv : 23|1@1+ (1,0) [0|1] "" Vector__XXX
 SG_ STS_Standlicht : 24|1@1+ (1,0) [0|1] "" Vector__XXX
 SG_ STS_Fahrlicht : 25|1@1+ (1,0) [0|1] "" Vector__XXX
 SG_ STS_Alarm_still : 26|1@1+ (1,0) [0|1] "" Vector__XXX
 SG_ STS_Texte : 27|4@1+ (1,0) [0|15] "" Vector__XXX
 SG_ STS_Laderelais : 38|1@1+ (1,0) [0|1] "" Vector__XXX
 SG_ STS_Summer : 48|1@1+ (1,0) [0|1] "" Vector__XXX
 SG_ STS_Alarm_Blinker : 50|1@1+ (1,0) [0|1] "" Vector__XXX
 SG_ STS_Notstart : 51|1@1+ (1,0) [0|1] "" Vector__XXX
 SG_ STS_Signalhorn : 55|1@1+ (1,0) [0|1] "" Vector__XXX
 SG_ STS_Leerlaufschaltung : 56|1@1+ (1,0) [0|1] ""  Motor_Diesel_MQB,Motor_Hybrid_MQB,Motor_Otto_MQB

BO_ 1413 Systeminfo_01: 8 Gateway_MQB
 SG_ SI_Sammel_SG_Fehler : 0|6@1+ (1,0) [0|60] "" Vector__XXX
 SG_ SI_Rollenmode : 6|2@1+ (1,0) [0|3] "" Vector__XXX
 SG_ SI_QRS_Mode : 8|1@1+ (1,0) [0|1] ""  Motor_Diesel_MQB,Motor_Hybrid_MQB,Motor_Otto_MQB
 SG_ SI_T_Mode : 9|1@1+ (1,0) [0|1] "" Vector__XXX
 SG_ SI_NWDF : 10|1@1+ (1,0) [0|1] ""  SAK_MQB
 SG_ SI_NWDF_gueltig : 11|1@1+ (1,0) [0|1] ""  SAK_MQB
 SG_ SI_Sammelfehler : 12|1@1+ (1,0) [0|1] "" Vector__XXX
 SG_ GW_KD_Fehler : 13|1@1+ (1,0) [0|1] "" Vector__XXX
 SG_ SI_BUS_01 : 16|1@1+ (1,0) [0|1] "" Vector__XXX
 SG_ SI_BUS_02 : 17|1@1+ (1,0) [0|1] "" Vector__XXX
 SG_ SI_BUS_03 : 18|1@1+ (1,0) [0|1] "" Vector__XXX
 SG_ SI_BUS_04 : 19|1@1+ (1,0) [0|1] "" Vector__XXX
 SG_ SI_BUS_05 : 20|1@1+ (1,0) [0|1] "" Vector__XXX
 SG_ SI_BUS_06 : 21|1@1+ (1,0) [0|1] "" Vector__XXX
 SG_ SI_BUS_07 : 22|1@1+ (1,0) [0|1] "" Vector__XXX
 SG_ SI_BUS_08 : 23|1@1+ (1,0) [0|1] "" Vector__XXX
 SG_ SI_BUS_09 : 24|1@1+ (1,0) [0|1] "" Vector__XXX
 SG_ SI_BUS_10 : 25|1@1+ (1,0) [0|1] "" Vector__XXX
 SG_ SI_BUS_11 : 26|1@1+ (1,0) [0|1] "" Vector__XXX
 SG_ SI_BUS_12 : 27|1@1+ (1,0) [0|1] "" Vector__XXX
 SG_ SI_BUS_13 : 28|1@1+ (1,0) [0|1] "" Vector__XXX
 SG_ SI_BUS_14 : 29|1@1+ (1,0) [0|1] "" Vector__XXX
 SG_ SI_BUS_15 : 30|1@1+ (1,0) [0|1] "" Vector__XXX

BO_ 288 TSK_06: 8 Motor_Diesel_MQB
 SG_ TSK_06_CRC : 0|8@1+ (1,0) [0|255] ""  Gateway_MQB,Getriebe_DQ_Hybrid_MQB,Getriebe_DQ_MQB
 SG_ TSK_06_BZ : 8|4@1+ (1,0) [0|15] ""  Gateway_MQB,Getriebe_DQ_Hybrid_MQB,Getriebe_DQ_MQB
 SG_ TSK_Radbremsmom : 12|12@1+ (8,0) [0|32760] "Unit_NewtoMeter"  Gateway_MQB,Getriebe_DQ_Hybrid_MQB,Getriebe_DQ_MQB
 SG_ TSK_Status : 24|3@1+ (1,0) [0|7] ""  Gateway_MQB,Getriebe_DQ_Hybrid_MQB,Getriebe_DQ_MQB
 SG_ TSK_v_Begrenzung_aktiv : 27|1@1+ (1,0) [0|1] ""  Gateway_MQB,Getriebe_DQ_Hybrid_MQB,Getriebe_DQ_MQB
 SG_ TSK_Standby_Anf_ESP : 28|1@1+ (1,0) [0|1] ""  Gateway_MQB
 SG_ TSK_Freig_Verzoeg_Anf : 30|1@1+ (1,0) [0|1] ""  Gateway_MQB,Getriebe_DQ_Hybrid_MQB,Getriebe_DQ_MQB
 SG_ TSK_Limiter_ausgewaehlt : 31|1@1+ (1,0) [0|1] ""  Gateway_MQB,Getriebe_DQ_Hybrid_MQB,Getriebe_DQ_MQB
 SG_ TSK_ax_Getriebe_02 : 48|9@1+ (0.024,-2.016) [-2.016|10.224] "Unit_MeterPerSeconSquar"  Gateway_MQB,Getriebe_DQ_Hybrid_MQB,Getriebe_DQ_MQB
 SG_ TSK_Zwangszusch_ESP : 57|1@1+ (1,0) [0|1] ""  Gateway_MQB
 SG_ TSK_zul_Regelabw : 58|6@1+ (0.024,0) [0|1.512] "Unit_MeterPerSeconSquar"  Gateway_MQB,Getriebe_DQ_Hybrid_MQB,Getriebe_DQ_MQB

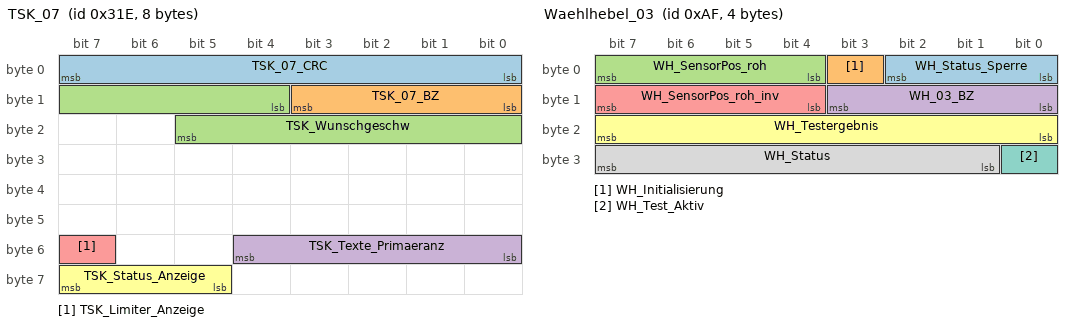
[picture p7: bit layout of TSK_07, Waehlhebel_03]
BO_ 798 TSK_07: 8 Motor_Diesel_MQB
 SG_ TSK_07_CRC : 0|8@1+ (1,0) [0|255] ""  Gateway_MQB
 SG_ TSK_07_BZ : 8|4@1+ (1,0) [0|15] ""  Gateway_MQB
 SG_ TSK_Wunschgeschw : 12|10@1+ (0.32,0) [0|326.72] "Unit_KiloMeterPerHour"  Gateway_MQB
 SG_ TSK_Texte_Primaeranz : 48|5@1+ (1,0) [0|31] ""  Gateway_MQB
 SG_ TSK_Limiter_Anzeige : 55|1@1+ (1,0) [0|1] ""  Gateway_MQB
 SG_ TSK_Status_Anzeige : 61|3@1+ (1,0) [0|7] ""  Gateway_MQB

BO_ 1716 VIN_01: 8 Gateway_MQB
 SG_ VIN_01_MUX M : 0|2@1+ (1,0) [0|3] ""  Airbag_MQB
 SG_ KS_Geheimnis_1 m0 : 8|8@1+ (1,0) [0|255] "" Vector__XXX
 SG_ VIN_4 m1 : 8|8@1+ (1,0) [0|255] ""  Airbag_MQB
 SG_ VIN_11 m2 : 8|8@1+ (1,0) [0|255] ""  Airbag_MQB
 SG_ KS_Geheimnis_2 m0 : 16|8@1+ (1,0) [0|255] "" Vector__XXX
 SG_ VIN_5 m1 : 16|8@1+ (1,0) [0|255] ""  Airbag_MQB
 SG_ VIN_12 m2 : 16|8@1+ (1,0) [0|255] ""  Airbag_MQB
 SG_ KS_Geheimnis_3 m0 : 24|8@1+ (1,0) [0|255] "" Vector__XXX
 SG_ VIN_6 m1 : 24|8@1+ (1,0) [0|255] ""  Airbag_MQB
 SG_ VIN_13 m2 : 24|8@1+ (1,0) [0|255] ""  Airbag_MQB
 SG_ KS_Geheimnis_4 m0 : 32|8@1+ (1,0) [0|255] "" Vector__XXX
 SG_ VIN_7 m1 : 32|8@1+ (1,0) [0|255] ""  Airbag_MQB
 SG_ VIN_14 m2 : 32|8@1+ (1,0) [0|255] ""  Airbag_MQB
 SG_ VIN_1 m0 : 40|8@1+ (1,0) [0|255] ""  Airbag_MQB
 SG_ VIN_8 m1 : 40|8@1+ (1,0) [0|255] ""  Airbag_MQB
 SG_ VIN_15 m2 : 40|8@1+ (1,0) [0|255] ""  Airbag_MQB
 SG_ VIN_2 m0 : 48|8@1+ (1,0) [0|255] ""  Airbag_MQB
 SG_ VIN_9 m1 : 48|8@1+ (1,0) [0|255] ""  Airbag_MQB
 SG_ VIN_16 m2 : 48|8@1+ (1,0) [0|255] ""  Airbag_MQB
 SG_ VIN_3 m0 : 56|8@1+ (1,0) [0|255] ""  Airbag_MQB
 SG_ VIN_10 m1 : 56|8@1+ (1,0) [0|255] ""  Airbag_MQB
 SG_ VIN_17 m2 : 56|8@1+ (1,0) [0|255] ""  Airbag_MQB

BO_ 175 Waehlhebel_03: 4 Waehlhebel_MQB
 SG_ WH_Status_Sperre : 0|3@1+ (1,0) [0|7] ""  Getriebe_DQ_Hybrid_MQB,Getriebe_DQ_MQB
 SG_ WH_Initialisierung : 3|1@1+ (1,0) [0|1] ""  Getriebe_DQ_Hybrid_MQB,Getriebe_DQ_MQB
 SG_ WH_SensorPos_roh : 4|4@1+ (1,0) [0|15] ""  Getriebe_DQ_Hybrid_MQB,Getriebe_DQ_MQB
 SG_ WH_03_BZ : 8|4@1+ (1,0) [0|15] ""  Getriebe_DQ_Hybrid_MQB,Getriebe_DQ_MQB
 SG_ WH_SensorPos_roh_inv : 12|4@1+ (1,0) [0|15] ""  Getriebe_DQ_Hybrid_MQB,Getriebe_DQ_MQB
 SG_ WH_Testergebnis : 16|8@1+ (1,0) [0|255] ""  Getriebe_DQ_Hybrid_MQB,Getriebe_DQ_MQB
 SG_ WH_Test_Aktiv : 24|1@1+ (1,0) [0|1] ""  Getriebe_DQ_Hybrid_MQB,Getriebe_DQ_MQB
 SG_ WH_Status : 25|7@1+ (1,0) [0|127] ""  Getriebe_DQ_Hybrid_MQB,Getriebe_DQ_MQB

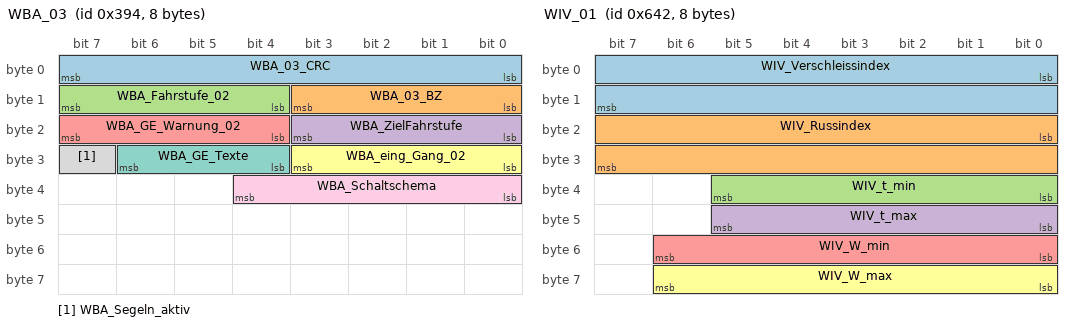
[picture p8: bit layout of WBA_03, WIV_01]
BO_ 916 WBA_03: 8 Getriebe_DQ_Hybrid_MQB
 SG_ WBA_03_CRC : 0|8@1+ (1,0) [0|255] ""  Gateway_MQB
 SG_ WBA_03_BZ : 8|4@1+ (1,0) [0|15] ""  Gateway_MQB
 SG_ WBA_Fahrstufe_02 : 12|4@1+ (1,0) [0|15] ""  Gateway_MQB
 SG_ WBA_ZielFahrstufe : 16|4@1+ (1,0) [0|15] ""  Gateway_MQB
 SG_ WBA_GE_Warnung_02 : 20|4@1+ (1,0) [0|15] ""  Gateway_MQB
 SG_ WBA_eing_Gang_02 : 24|4@1+ (1,0) [0|15] ""  Gateway_MQB,Motor_Diesel_MQB,Motor_Otto_MQB
 SG_ WBA_GE_Texte : 28|3@1+ (1,0) [0|7] ""  Gateway_MQB
 SG_ WBA_Segeln_aktiv : 31|1@1+ (1,0) [0|1] ""  Gateway_MQB
 SG_ WBA_Schaltschema : 32|5@1+ (1,0) [0|31] ""  Gateway_MQB

BO_ 1602 WIV_01: 8 Motor_Diesel_MQB
 SG_ WIV_Verschleissindex : 0|16@1+ (2E-008,0) [0|0.00131068] ""  Gateway_MQB
 SG_ WIV_Russindex : 16|16@1+ (2E-008,0) [0|0.00131068] ""  Gateway_MQB
 SG_ WIV_t_min : 32|6@1+ (1,0) [0|63] "Unit_Month"  Gateway_MQB
 SG_ WIV_t_max : 40|6@1+ (1,0) [0|63] "Unit_Month"  Gateway_MQB
 SG_ WIV_W_min : 48|7@1+ (1000,0) [0|127000] "Unit_KiloMeter"  Gateway_MQB
 SG_ WIV_W_max : 56|7@1+ (1000,0) [0|127000] "Unit_KiloMeter"  Gateway_MQB

BO_TX_BU_ 812 : Motor_Diesel_MQB,Motor_Hybrid_MQB,Motor_Otto_MQB;
BO_TX_BU_ 1648 : Motor_Diesel_MQB,Motor_Hybrid_MQB,Motor_Otto_MQB;
BO_TX_BU_ 289 : Motor_Diesel_MQB,Motor_Hybrid_MQB,Motor_Otto_MQB;
BO_TX_BU_ 967 : Motor_Diesel_MQB,Motor_Hybrid_MQB,Motor_Otto_MQB;
BO_TX_BU_ 1601 : Motor_Diesel_MQB,Motor_Hybrid_MQB,Motor_Otto_MQB;
BO_TX_BU_ 16 : Motor_Diesel_MQB,Motor_Hybrid_MQB,Motor_Otto_MQB;
BO_TX_BU_ 2600468599 : Getriebe_DQ_Hybrid_MQB,Getriebe_DQ_MQB;
BO_TX_BU_ 2600468598 : Motor_Diesel_MQB,Motor_Hybrid_MQB,Motor_Otto_MQB;
BO_TX_BU_ 913 : Motor_Diesel_MQB,Motor_Hybrid_MQB,Motor_Otto_MQB;
BO_TX_BU_ 288 : Motor_Diesel_MQB,Motor_Hybrid_MQB,Motor_Otto_MQB;
BO_TX_BU_ 798 : Motor_Diesel_MQB,Motor_Hybrid_MQB,Motor_Otto_MQB;
BO_TX_BU_ 916 : Getriebe_DQ_Hybrid_MQB,Getriebe_DQ_MQB;
BO_TX_BU_ 1602 : Motor_Diesel_MQB,Motor_Hybrid_MQB,Motor_Otto_MQB;
CM_ SG_ 812 MO_Prio_MAX_Wunschdrehzahl "Prioritätsbit der Motorwunschdrehzahl  als MAX";
CM_ SG_ 812 MO_Prio_MIN_Wunschdrehzahl "Prioritätsbit der Motorwunschdrehzahl als MIN";
CM_ SG_ 812 MO_Luftpfad_aktiv "Getriebeeingriff wird zusätzlich zum Zündungspfad auch über den Luftpfad umgesetzt, kommt zu B8 neu in die PL48-Getriebe";
CM_ SG_ 812 MO_v_Begrenz_Aktivierbar "Fehlerbit wird vom Motor-SG gesetzt, wenn dieses nicht in dieGeschwindigkeits-begrenzung gehen kann, ein Fehler während der v-Begrenzung auftritt oder v > v_Begrenzung - v_Delta";
CM_ SG_ 812 MO_Drehzahlbeeinflussung "Mit diesem Faktor kann das Motorsteuergerät die vom CVT-Getriebe einzustellende Sollmotodrehzahl beeinflussen. Im CVT-Steuergerät ist ein verbrauchsoptimales Kennfeld und ein abgasoptimiertes Kennfeld abgelegt. Mit dem Wert von 0-100% wird zwischen diesen";
CM_ SG_ 812 MO_MIN_Wunschdrehzahl "minimale Motorwunschdrehzahl aufgrund Regeneration, die vom Getriebe nicht unterschritten werden darf";
CM_ SG_ 812 MO_MAX_Wunschdrehzahl "maximale Motorwunschdrehzahl aufgrund Systemfehlern, Temperatur oder Verbrauchs/ Abgas Optimum, die vom Getriebe nicht überschritten werden darf";
CM_ SG_ 812 MO_Charisma_FahrPr "MLBevo: Aktuelles Fahrprogramm des Charisma-Teilnehmers (siehe Systemlastenheft Drive Select)
MQB: Istwert der Kennlinie (siehe Systemlastenheft MQB FPA)";
CM_ SG_ 812 MO_Charisma_Status "Charisma Systemstatus des Charisma-Teilnehmers

Wert 0x3 ist nur für Fahrzeuge ab MQB relevant";
CM_ BO_ 1648 "Kombischnittstelle";
CM_ SG_ 1648 MO_Hybrid_StartStopp_LED "Ansteuerung der Funktions-LED der Hybrid Taste bzw. Start/Stop Deaktivierungstaste.
Der Start/Stopp-Master (derzeit im MSG) (oder ein künftiger Hybrid-Master) soll die Ansteuerung senden.";
CM_ SG_ 1648 MO_Eis_Offroad_LED "Ansteuerung der Funktions-LED der Eis- bzw. Offroad Taste.";
CM_ SG_ 1648 MO_Anzahl_Abgesch_Zyl "Gibt die Anzahl der abgeschalteten Zylinder bei  MO_Zylinderabschaltung Werte 0 und 3 an.
In Überganszuständen, MO_Zylinderabschaltung Werte 1 und 2, wird der Zielbetriebszustand angezeigt. ";
CM_ SG_ 1648 MO_Zylabsch_Texte "Zylinderabschaltung mode in Kombi, fuer Zylinderabschaltung";
CM_ SG_ 1648 MO_E85_BS_Texte "E85 Brennstoff-Texte im Kombi, fuer Flexfuel

0 = kein Text
1 = FlexFuel Warm_Up_ Lampe (WU_Lampe)
2 = FlexFuel Warnung 3.Stufe (Too cold for ethanol)
3 = FlexFuel Warnung 1.Stufe (Refuel with gasoline)
4 = FlexFuel Warnung 2. Stufe (Refuel with gas";
CM_ SG_ 1648 MO_Drehzahl_Warnung "Warnhinweis zum Kombi im Fall einer fehlerbehafteten Drehzahlbegrenzung";
CM_ SG_ 1648 MO_obere_Drehzahlgrenze "obere Drehzahlgrenze des Motors";
CM_ SG_ 289 MO_Fahrpedalrohwert_01 "AUDI D4: Zykluszeit: 10ms (siehe Zykluszeit schnell/Cycletime Fast)

Stellung des Fahrpedales (Rohwert, ohne Überlagerung durch GRA-Eingriffe etc.)

Die Funktionen zur Berechung des Fahrpedalrohwerts laufen im 10ms Raster. Der Fahrpedalwert berechnet ";
CM_ SG_ 289 MO_QBit_Fahrpedalwerte_01 "AUDI D4: Zykluszeit: 10ms (siehe Zykluszeit schnell/Cycletime Fast)

QBit für beide Fahrpedalwerte des Motors (Fahrpedalrohsignal für ESP, EPB, ACC; Fahrpedalwert für Getriebe)

Achtung:
Reduktion der Zykluszeit Motor_03 auf 10ms geplant.
Projektabh";
CM_ SG_ 289 MO_Fahrpedalgradient "Das Motorsteuergerät besitzt 2 analoge Fahrpedalsignale. Das Signal des ersten Kanals wird alle 4ms abgetastet. Um Bitschwankungen des A/D-Wandler herauszufiltern wird das Signal entjittert. Anschließend wird der Gradient berechnet. Entsprechend der Zyklu";
CM_ SG_ 289 MO_Sig_Fahrpedalgradient "Kennzeichnet das Vorzeichen des Signal 'Fahrpedalgradient'. Die Ausgabe erfolgt nur parallel statisch mit gesendetem Signal: 'Steuerungsbit Fahrpedalgradient' ";
CM_ SG_ 289 MO_rel_Saugrohrdruck "Der Wert gibt an, um wieviel mbar der Saugrohrdruck unterhalb des Umgebungsdrucks liegt. Überdruck im Saugrohr wird nicht ausgegeben.
0: Saugrohrdruck=Umgebungsdruck";
CM_ SG_ 289 MO_rel_Saugrohrdruck_gem_err "0: mind. eine Modellrechnung wird zur Berechnung des relativen Saugdrucks herangezogen
1: Relativer Saugrohrdruck wird ausschließlich über Messgrößen bestimmt";
CM_ SG_ 289 MO_Moment_im_Leerlauf "Motorbetriebszustand ist Leerlauf, keine Momentenerhöhung durch Fahrpedal, ACC, GRA+

AUDI D4: Zykluszeit: 10ms (siehe Zykluszeit schnell/Cycletime Fast)

Achtung:
Reduktion der Zykluszeit Motor_03 auf 10ms geplant.
Projektabhängig soll künftig mit ";
CM_ SG_ 289 MO_Schubabschaltung "ESP plausibilisiert Unterdrucksensor nur bei aktiver Schubabschaltung";
CM_ SG_ 289 MO_Solldrehz_Leerlauf "Leerlaufsolldrehzahl, die im Motor eingestellt ist (Bei Parallelhybrid im E-Fahr-Betrieb Leerlaufsolldrehzahl der E-Maschine). Der Motor paßt aufgrund der Anforderung von anderen Steuergeräten seine Leerlaufsolldrehzahl an, bspw. Kat-Heizen, Anforderung v";
CM_ BO_ 967 "MQB - vorher Motor_06 / Umbenennung wg. ID-Wechsel";
CM_ SG_ 967 MO_Kuehlerluefter_MUX "Multiplexer für das Signal 'MO_Kuehlerlüfter'";
CM_ SG_ 967 MO_Kuehlerluefter_1 "Ansteuertastverhaeltnis (PWM) der Kuehlerluefterendstufe 1";
CM_ SG_ 967 MO_Kuehlerluefter_2 "Ansteuertastverhaeltnis (PWM) der Kuehlerluefterendstufe 2";
CM_ SG_ 967 MO_HYB_Status_HV_Ladung "Statusanzeige für Funktion HV-Ladung über 12V-Seite";
CM_ SG_ 967 WIV_Anzeige_aktiv "Peilstabsanzeigefunktion aktiv";
CM_ SG_ 967 WIV_Oelmin_Warn "Signal gibt an wenn der Ölstand die Min-Schwelle unterschritten hat";
CM_ SG_ 967 WIV_Sensorfehler "Ölstand/Öltemperatursensor (TOG) defekt";
CM_ SG_ 967 WIV_Schieflage "Fahrzeug steht nicht waagerecht, Messung ungenau";
CM_ SG_ 967 WIV_Oelstand "8 Segmente zur Balkenanzeige des Ölstands";
CM_ SG_ 967 MO_Zustand_HWP "Rückmeldung des  Ansteuerzustand der Hauptwasserpumpe an das Klima-SG .
Der Zustand 'HWP fördert' wird übermittelt, wenn die Schaufeln der Hauptwasserpumpe frei drehen können und die Motordrehzahl und damit die Wasserpumpendrehzahl größer als Null ist. B";
CM_ SG_ 967 WIV_Oelsystem_aktiv "Gesamtölsystem aktiv (entspricht Ölsensor verbaut) und das Ölstand-Untermenu im MMI aktiv";
CM_ SG_ 967 WIV_nicht_betriebswarm "Motor nicht betriebswarm, Messung ungenau";
CM_ SG_ 967 WIV_Ueberfuell_Warn "Ölstand hat die Überfüllschwelle überschritten";
CM_ SG_ 967 WIV_laufender_Motor "Messung bei laufendem Motor nicht möglich";
CM_ SG_ 967 MO_HYB_Text_1 "Textanzeige: Fehler Hybridsystem
bitte Fahrzeug an sicherem Ort anhalten";
CM_ SG_ 967 MO_HYB_Text_2 "Textanzeige: Fehler Hybridystem
bitte Werkstatt aufsuchen";
CM_ SG_ 967 MO_HYB_Text_3 "Textanzeige: Bitte Motor erneut starten";
CM_ SG_ 967 MO_HYB_Text_4 "Textanzeige: E-Mode unterbrochen (passiv)";
CM_ SG_ 967 MO_Text_Motorstart "Anzeigetexte für Start/Stopp und Motor-Start";
CM_ SG_ 967 MO_HYB_Text_5 "Textanzeige: Hybrid-Funktionen nicht verfügbar";
CM_ SG_ 967 MO_HYB_Text_6 "Textanzeige: Elektrisches Fahren zur Zeit nicht möglich";
CM_ SG_ 967 MO_HYB_Text_7 "Textanzeige: Traktionsbatterie wird geladen bitte Motor nicht abstellen";
CM_ SG_ 967 MO_Text_Partikelfil_Reg "Über dieses Bit im Kombi wird ein Klartextanzeige erzeugt werden: 'Partikelfilter benötigt Regeneration'.
";
CM_ SG_ 967 WIV_Oelmenge "Ölmenge zwischen Min und Max";
CM_ SG_ 967 MO_Systemlampe "EGas Systemlampe (EPC) oder Vorglühlampe im Kombi, Kombi steuert immer gleiche
LED an, nur über Ziffernblatt wird die EPC von der Vorglühlampe differenziert";
CM_ SG_ 967 MO_OBD2_Lampe "OBD bzw. MIL-Lampe wird vom Motorsteuergerät angesteuert, die Information im Signal GE_OBD_Status wird vom Motorsteuergerät an das Kombi weitergereicht";
CM_ SG_ 967 MO_Heissleuchte "Ansteuerung der Kühlwassertemperatur-Heißleuchte (Sensor nur noch am Motorsteuergerät): Temperaturschaltschwellen mit Hysterese (bei VW D1/Colorado Kombi derzeit noch nicht genutzt).";
CM_ SG_ 967 MO_Partikel_Lampe "Partikelfilter-Lampe wird eingeschaltet";
CM_ SG_ 967 WIV_Oelstand_nicht_vorhanden "Kein aktueller Ölstand vorhanden";
CM_ SG_ 967 WIV_nachfuellanzeige_ein "Steuert das Aufblenden der Nachfüllanzeige im Kombi, nach Klemme 15 ein und geöffneter Motorhaube";
CM_ SG_ 967 WIV_Ueberfuell_deaktiv "Unterdrückung der Warnung im Kombi die durch Signal WIV_Ueberfuel_Warn ausgelöst wird";
CM_ SG_ 967 WIV_Unterfuell_Warn "Ölstand hat die Unterfüllschwelle unterschritten";
CM_ SG_ 967 MO_Tankdeckel_Lampe "Ansteuerung Tankdeckel-Warnlampe Kombiinstrument (nur Ottomotoren) z.Zt. Vorhalt VW";
CM_ SG_ 967 MO_Text_Tankdeckelwarn "Textbit der Tankdeckelwarnung, z.Zt. Vorhalt VW";
CM_ SG_ 967 WIV_Oeldr_Warn_Motor "Löst im Kombiinstrument die rote Prio1-Öldruckwarnung (inkl. 3xBeep) aus; die Warnauslösung erfolgt nur bei gleichzeitig gesetztem 'WIV_Enable_Oeldr_Motor'";
CM_ BO_ 1601 "ab MQB mit CRC-8";
CM_ SG_ 1601 Motor_Code_01_CRC "Für MLB:
Berechnung siehe Lastenheft 'Kommunikationsabsicherung für FlexRay und CAN''

Ab MQB und MLBevo:
Berechnung siehe Lastenheft 'End-to-End Kommunikationsabsicherung''

Endwerte siehe Begleitdokument 'S-PDU Kennungsfolgen'";
CM_ SG_ 1601 MO_Faktor_Momente_02 "Dieses Bit schaltet den Wertebereich aller Momente vom Motor, Getriebe, TSK, Bremse ... um! Die Momente besitzen somit einen variablen Wertebereich, weil sich durch den Faktor die Momente sowohl in Auflösung als auch Maximalwerten ändert.
0x0: nicht bele";
CM_ SG_ 1601 MO_Hybridfahrzeug "Anhand dieses Signals plausibilisiert die Lenkhilfe das Bit Fahrbereitschaft";
CM_ SG_ 1601 MO_Code "Motorcodierinformation für Getriebe. Überwachung auf Falschverbau.






";
CM_ SG_ 1601 MO_Getriebe_Code "Getriebecodierung des Motors 
";
CM_ SG_ 1601 MO_StartStopp_Codiert "Funktion StartStopp im aktuellen Klemmenzyklus verbaut";
CM_ SG_ 1601 MO_Kraftstoffart "0x5 - 0xF = tbd. ";
CM_ SG_ 1601 MO_Abgastyp_EOBD "Abgastyp EOBD
";
CM_ SG_ 1601 MO_Abgastyp_OBD "Abgastyp OBD (US-Norm)
";
CM_ SG_ 1601 MO_DPF_verbaut "Verbauinformation Diesel-Partikel-Filter
";
CM_ SG_ 1601 TSK_Codierung "Information über den plausibilisierten Codierungszustand des Triebstrangskoordinators auf ACC oder GRA.";
CM_ BO_ 157 "Motor - Getriebe - Schnittstelle auf CAN-Antrieb (Hybrid)
ab MQB mit CRC-8";
CM_ SG_ 157 Motor_Hybrid_01_CRC "Für MLB:
Berechnung siehe Lastenheft 'Kommunikationsabsicherung für FlexRay und CAN''

Ab MQB und MLBevo:
Berechnung siehe Lastenheft 'End-to-End Kommunikationsabsicherung''

Endwerte siehe Begleitdokument 'S-PDU Kennungsfolgen'";
CM_ SG_ 157 Motor_Hybrid_01_BZ "überlaufender 4bit Botschaftszaehler; wird in jeder Sendebotschaft inkrementiert";
CM_ SG_ 157 MO_HYB_IstStatusK0 "Status 'offen' muss eine voll geöffnete Kupplung sicherstellen.";
CM_ SG_ 157 MO_HYB_max_ind_VM_Mom "inneres maximal mögliches VM-Moment bei einer Drehzahl (z.B. Rauchbegrenzung oder Fehlerfall).";
CM_ SG_ 157 MO_HYB_Startmodus "Hybridsteuerung zeigt an, auf welche Weise gestartet werden soll.";
CM_ SG_ 157 MO_HYB_Startmodus_PQ3x "Hybridsteuerung (MSG) zeigt an, auf welche Weise gestartet werden soll. (Nur PQ3x Hybrid)";
CM_ SG_ 157 MO_HYB_Stoppmodus "Hybridsteuerung zeigt an, auf welche Weise gestoppt werden soll.";
CM_ SG_ 157 MO_HYB_VM_Mom_oE "Verbrenner-Fahrmoment abzüglich Verbrenner-Verlustmoment. Vorzeichenbehaftet. Für Benutzung in Getriebe-Schaltstrategie";
CM_ SG_ 157 MO_HYB_VM_aktiv "0 = VMotor wird nicht aktiv gehalten (nVM < n_min und keine LL-Regelung aktiv)
1 = VMotor aktiv (ab der ersten Einspritzung; gilt auch für Schubbetrieb, wenn VMotor spätestens durch LLRegelung befeuert würde)
Verwendet zur Bestimmung des Ist-Zustandes";
CM_ SG_ 157 MO_HYB_Schaltverhinderung "Schaltungen werden an den DZ-Grenzen (Nullgas-Schaltdrehzahl und Kickdown-Schaltdrehzahl) ausgeführt.";
CM_ SG_ 157 MO_HYB_Selektor_Momverlauf_EM "Selektor welche Größe des Momentenverlauf aktuell übertragen wird
000b = 0 :  keine Werte (GRA/ACC nicht aktiv)
001b = 1 : max. umsetzbares langfristiges Rekup.-Moment
010b = 2 : Knickdrehzahl d. langfr. Rekup-Kurve
011b = 3 : max. verfügbares langfr.";
CM_ SG_ 157 MO_HYB_Momverlauf_Rek "Momentenverlaufs-information bei aktiver GRA/ACC
max. umsetzbares langfristiges Rekup.-Moment";
CM_ SG_ 157 MO_HYB_KnickDZ_Rek "Momentenverlaufs-information bei aktiver GRA/ACC
Knickdrehzahl d. langfr. Rekup-Kurve";
CM_ SG_ 157 MO_HYB_Momverlauf_EM "Momentenverlaufs-information bei aktiver GRA/ACC
max. umsetzbares langfristiges Rekup.-Moment";
CM_ SG_ 157 MO_HYB_KnickDZ_EM "Momentenverlaufs-information bei aktiver GRA/ACC
Knickdrehzahl d. langfr. pos. EM-Kurve";
CM_ BO_ 811 "Motor - Getriebe - Schnittstelle auf CAN-Antrieb (Hybrid)";
CM_ SG_ 811 MO_HYB_E_Faktor "Signed Nibble, verwendet vom GSG zur Interpolation zwischen VMKennfeld und dem Rekuperations-Grenzkennfeld (negative Werte des E-Faktors) bzw. dem Boost-Grenzkennfeld (positive Werte des E-Faktors).
0000 = VM-Kennfeld (keine Interpolation)
0001..0111 = ";
CM_ SG_ 811 MO_HYB_Drehzahl_VM "für OBD freeze frame";
CM_ SG_ 811 MO_HYB_LowSpeedModus "MSG legt fest:
0 = klassisches Ausrollen/Anfahren mit N_mot >= N_Leerlauf_VM
1 = elektr. Ausrollen/Anfahren mit geschl. Triebstrang mit N_mot < N_Leerlauf_VM";
CM_ SG_ 2600468501 NM_Airbag_01_SNI "Source Node-Identifier (SNI) identifiziert den Sender der NM-Botschaft (Knotenadresse) eindeutig im Fahrzeug";
CM_ SG_ 2600468501 NM_Airbag_01_NM_State "1 = Zustand Repeat Message (<-- Bus-Sleep Mode)
2 = Zustand Repeat Message (<-- Prepare Bus-Sleep Mode)
4 = Zustand Normal Operation (<-- Repeat Message)
8 = Zustand Normal Operation (<-- Ready Sleep)";
CM_ SG_ 2600468501 NM_Airbag_01_Car_Wakeup "Car Wakeup (Gateway wertet aus)
MQB: Klemme 15 ist unplausibel (Kl.-15 HW ist ein, Kl.-15 SW aus) und muss dem Fahrer angezeigt werden (dauerhaft)";
CM_ SG_ 2600468501 NM_Airbag_01_Wakeup "enthält die Weckursache; stehen mehrere Weckursachen parallel an, dann muss der kleinste Wert übertragen werden";
CM_ SG_ 2600468501 NM_Airbag_01_NM_aktiv_KL15 "Steuergerät hat KL15-EIN erkannt";
CM_ SG_ 2600468501 NM_Airbag_01_NM_aktiv_Diagnose "Diagnose befindet sich nach VW80124 in einer NonDefaultDiagnostic-Session, z.B. ExtendedDiagnostic-Session";
CM_ SG_ 2600468501 NM_Airbag_01_NM_aktiv_Tmin "Mindestaktivzeit ist noch nicht abgelaufen (bei jedem Weckereignis wird die Mindestaktivzeit neu gestartet)";
CM_ SG_ 2600468501 NM_Airbag_01_UDS_CC "Funktionseinschränkung aufgrund aktivem UDS-Communication Control; siehe VW80124";
CM_ SG_ 2600468604 NM_EMotor_01_SNI "Source Node-Identifier (SNI) identifiziert den Sender der NM-Botschaft (Knotenadresse) eindeutig im Fahrzeug";
CM_ SG_ 2600468604 NM_EMotor_01_NM_State "1 = Zustand Repeat Message (<-- Bus-Sleep Mode)
2 = Zustand Repeat Message (<-- Prepare Bus-Sleep Mode)
4 = Zustand Normal Operation (<-- Repeat Message)
8 = Zustand Normal Operation (<-- Ready Sleep)";
CM_ SG_ 2600468604 NM_EMotor_01_Car_Wakeup "Car Wakeup (Gateway wertet aus)
";
CM_ SG_ 2600468604 NM_EMotor_01_Wakeup "enthält die Weckursache; stehen mehrere Weckursachen parallel an, dann muss der kleinste Wert übertragen werden";
CM_ SG_ 2600468604 NM_EMotor_01_NM_aktiv_KL15 "Steuergerät hat KL15-EIN erkannt";
CM_ SG_ 2600468604 NM_EMotor_01_NM_aktiv_Diagnose "Diagnose befindet sich nach VW80124 in einer NonDefaultDiagnostic-Session, z.B. ExtendedDiagnostic-Session";
CM_ SG_ 2600468604 NM_EMotor_01_NM_aktiv_Tmin "Mindestaktivzeit ist noch nicht abgelaufen (bei jedem Weckereignis wird die Mindestaktivzeit neu gestartet)";
CM_ SG_ 2600468604 NM_EMotor_01_NL_Daten_EEPROM "EEPROM Datenspeicherung (lokaler / SG interner Nachlauf vor Wakeup)";
CM_ SG_ 2600468604 NM_EMotor_01_UDS_CC "Funktionseinschränkung aufgrund aktivem UDS-Communication Control; siehe VW80124";
CM_ SG_ 2600468496 NM_Gateway_SNI "Source Node-Identifier (SNI) identifiziert den Sender der NM-Botschaft (Knotenadresse) eindeutig im Fahrzeug";
CM_ SG_ 2600468496 NM_Gateway_NM_State "1 = Zustand Repeat Message (<-- Bus-Sleep Mode)
2 = Zustand Repeat Message (<-- Prepare Bus-Sleep Mode)
4 = Zustand Normal Operation (<-- Repeat Message)
8 = Zustand Normal Operation (<-- Ready Sleep)";
CM_ SG_ 2600468496 NM_Gateway_Car_Wakeup "Car Wakeup (Gateway wertet aus)
";
CM_ SG_ 2600468496 NM_Gateway_Wakeup "enthält die Weckursache; stehen mehrere Weckursachen parallel an, dann muss der kleinste Wert übertragen werden";
CM_ SG_ 2600468496 NM_Gateway_NM_aktiv_KL15 "Steuergerät hat KL15-EIN erkannt";
CM_ SG_ 2600468496 NM_Gateway_NM_aktiv_Diagnose "Diagnose befindet sich nach VW80124 in einer NonDefaultDiagnostic-Session, z.B. ExtendedDiagnostic-Session";
CM_ SG_ 2600468496 NM_Gateway_NM_aktiv_Tmin "Mindestaktivzeit ist noch nicht abgelaufen (bei jedem Weckereignis wird die Mindestaktivzeit neu gestartet)";
CM_ SG_ 2600468496 NM_Gateway_ACAN_Aktivitaet "Dieser Bus wird auf Grund einer Aktivität auf dem Antriebs-CAN wachgehalten (Buskopplung, CAR-Wakeup)";
CM_ SG_ 2600468496 NM_Gateway_FCAN_Aktivitaet "Dieser Bus wird auf Grund einer Aktivität auf dem Fahrwerks-CAN wachgehalten (Buskopplung, CAR-Wakeup)";
CM_ SG_ 2600468496 NM_Gateway_KCAN_Aktivitaet "Dieser Bus wird auf Grund einer Aktivität auf dem Komfort-CAN wachgehalten (Buskopplung, CAR-Wakeup)";
CM_ SG_ 2600468496 NM_Gateway_ICAN_Aktivitaet "Dieser Bus wird auf Grund einer Aktivität auf dem Infotainment-CAN wachgehalten (Buskopplung, CAR-Wakeup)";
CM_ SG_ 2600468496 NM_Gateway_DiagCAN_Aktivitaet "Dieser Bus wird auf Grund einer Aktivität auf dem Diagnose-CAN wachgehalten (Buskopplung, CAR-Wakeup)";
CM_ SG_ 2600468496 NM_Gateway_ECAN_Aktivitaet "Dieser Bus wird auf Grund einer Aktivität auf dem Extended-CAN wachgehalten (Buskopplung, CAR-Wakeup)";
CM_ SG_ 2600468496 NM_Gateway_Energie_LIN_Aktivi000 "Dieser Bus wird auf Grund einer Aktivität auf dem Energie-LIN wachgehalten (Buskopplung, CAR-Wakeup)";
CM_ SG_ 2600468496 NM_Gateway_Bedien_LIN_Aktivitaet "Dieser Bus wird auf Grund einer Aktivität auf dem Bedien-LIN wachgehalten (Buskopplung, CAR-Wakeup)";
CM_ SG_ 2600468496 NM_Gateway_EM_Aktivitaet "Dieser Bus wird auf Grund einer Aktivität des Energiemanagements wachgehalten";
CM_ SG_ 2600468496 NM_Gateway_NL_EM "lokale / interne Aktivität vor WakeUp: Energiemanagement";
CM_ SG_ 2600468496 NM_Gateway_NL_Shutdown "lokale / interne Aktivität vor WakeUp: Shutdown";
CM_ SG_ 2600468496 NM_Gateway_NL_Spg_Messung "lokale / interne Aktivität vor WakeUp: Spannungsmessung";
CM_ SG_ 2600468496 NM_Gateway_NL_Wakeup_Monitor "lokale / interne Aktivität vor WakeUp: Wakeup Monitor";
CM_ SG_ 2600468496 NM_Gateway_UDS_CC "Funktionseinschränkung aufgrund aktivem UDS-Communication Control; siehe VW80124";
CM_ SG_ 2600468599 NM_Getriebe_01_SNI "Source Node-Identifier (SNI) identifiziert den Sender der NM-Botschaft (Knotenadresse) eindeutig im Fahrzeug";
CM_ SG_ 2600468599 NM_Getriebe_01_NM_State "1 = Zustand Repeat Message (<-- Bus-Sleep Mode)
2 = Zustand Repeat Message (<-- Prepare Bus-Sleep Mode)
4 = Zustand Normal Operation (<-- Repeat Message)
8 = Zustand Normal Operation (<-- Ready Sleep)";
CM_ SG_ 2600468599 NM_Getriebe_01_Car_Wakeup "Car Wakeup (Gateway wertet aus)
";
CM_ SG_ 2600468599 NM_Getriebe_01_Wakeup "enthält die Weckursache; stehen mehrere Weckursachen parallel an, dann muss der kleinste Wert übertragen werden";
CM_ SG_ 2600468599 NM_Getriebe_01_NM_aktiv_KL15 "Steuergerät hat KL15-EIN erkannt";
CM_ SG_ 2600468599 NM_Getriebe_01_NM_aktiv_Diagnose "Diagnose befindet sich nach VW80124 in einer NonDefaultDiagnostic-Session, z.B. ExtendedDiagnostic-Session";
CM_ SG_ 2600468599 NM_Getriebe_01_NM_aktiv_Tmin "Mindestaktivzeit ist noch nicht abgelaufen (bei jedem Weckereignis wird die Mindestaktivzeit neu gestartet)";
CM_ SG_ 2600468599 NM_Getriebe_01_NM_aktiv_v_gr_0 "Bus gefordert bei Geschwindigkeit > 0";
CM_ SG_ 2600468599 NM_Getriebe_01_NM_aktiv_Pos_Erk "Bus gefordert zur Positionserkennung des Wählhebels";
CM_ SG_ 2600468599 NM_Getriebe_01_NM_aktiv_Umg_Bed "Bus gefordert zum Lesen der Umgebungsbedingungen bei Fehlereintrag";
CM_ SG_ 2600468599 NM_Getriebe_01_NL_Daten_EEPROM "EEPROM Datenspeicherung (lokaler / SG interner Nachlauf vor Wakeup)";
CM_ SG_ 2600468599 NM_Getriebe_01_UDS_CC "Funktionseinschränkung aufgrund aktivem UDS-Communication Control; siehe VW80124";
CM_ SG_ 2600468603 NM_Hybrid_01_SNI "Source Node-Identifier (SNI) identifiziert den Sender der NM-Botschaft (Knotenadresse) eindeutig im Fahrzeug";
CM_ SG_ 2600468603 NM_Hybrid_01_NM_State "1 = Zustand Repeat Message (<-- Bus-Sleep Mode)
2 = Zustand Repeat Message (<-- Prepare Bus-Sleep Mode)
4 = Zustand Normal Operation (<-- Repeat Message)
8 = Zustand Normal Operation (<-- Ready Sleep)";
CM_ SG_ 2600468603 NM_Hybrid_01_Car_Wakeup "Car Wakeup (Gateway wertet aus)
";
CM_ SG_ 2600468603 NM_Hybrid_01_Wakeup "enthält die Weckursache; stehen mehrere Weckursachen parallel an, dann muss der kleinste Wert übertragen werden";
CM_ SG_ 2600468603 NM_Hybrid_01_NM_aktiv_KL15 "Steuergerät hat KL15-EIN erkannt";
CM_ SG_ 2600468603 NM_Hybrid_01_NM_aktiv_Diagnose "Diagnose befindet sich nach VW80124 in einer NonDefaultDiagnostic-Session, z.B. ExtendedDiagnostic-Session";
CM_ SG_ 2600468603 NM_Hybrid_01_NM_aktiv_Tmin "Mindestaktivzeit ist noch nicht abgelaufen (bei jedem Weckereignis wird die Mindestaktivzeit neu gestartet)";
CM_ SG_ 2600468603 NM_Hybrid_01_NL_Daten_EEPROM "EEPROM Datenspeicherung (lokaler / SG interner Nachlauf vor Wakeup)";
CM_ SG_ 2600468603 NM_Hybrid_01_NL_Luefter "Lüfter aktiv (lokaler / SG interner Nachlauf vor Wakeup)";
CM_ SG_ 2600468603 NM_Hybrid_01_UDS_CC "Funktionseinschränkung aufgrund aktivem UDS-Communication Control; siehe VW80124";
CM_ SG_ 2600468598 NM_MO_01_SNI "Source Node-Identifier (SNI) identifiziert den Sender der NM-Botschaft (Knotenadresse) eindeutig im Fahrzeug";
CM_ SG_ 2600468598 NM_MO_01_NM_State "1 = Zustand Repeat Message (<-- Bus-Sleep Mode)
2 = Zustand Repeat Message (<-- Prepare Bus-Sleep Mode)
4 = Zustand Normal Operation (<-- Repeat Message)
8 = Zustand Normal Operation (<-- Ready Sleep)";
CM_ SG_ 2600468598 NM_MO_01_Car_Wakeup "Car Wakeup (Gateway wertet aus)
";
CM_ SG_ 2600468598 NM_MO_01_Wakeup "enthält die Weckursache; stehen mehrere Weckursachen parallel an, dann muss der kleinste Wert übertragen werden";
CM_ SG_ 2600468598 NM_MO_01_NM_aktiv_KL15 "Steuergerät hat KL15-EIN erkannt";
CM_ SG_ 2600468598 NM_MO_01_NM_aktiv_Diagnose "Diagnose befindet sich nach VW80124 in einer NonDefaultDiagnostic-Session, z.B. ExtendedDiagnostic-Session";
CM_ SG_ 2600468598 NM_MO_01_NM_aktiv_Tmin "Mindestaktivzeit ist noch nicht abgelaufen (bei jedem Weckereignis wird die Mindestaktivzeit neu gestartet)";
CM_ SG_ 2600468598 NM_MO_01_NM_aktiv_HV_Abschaltung "Hybrid-Manager deaktiviert alle Hochvolt-Verbraucher für stromloses Öffnen der Batterieschütze (lokaler / SG interner Nachlauf vor Wakeup)";
CM_ SG_ 2600468598 NM_MO_01_NM_aktiv_EKP_Vorlauf "EKP Vorlauf (lokaler / SG interner Nachlauf vor Wakeup)";
CM_ SG_ 2600468598 NM_MO_01_NM_aktiv_STH_Betrieb "Standheizungsbetrieb (lokaler / SG interner Nachlauf vor Wakeup)";
CM_ SG_ 2600468598 NM_MO_01_NL_Kuehlerluefter "Kühlerlüfter Steuerung / Zusatzwasserpumpe (lokaler / SG interner Nachlauf vor Wakeup)";
CM_ SG_ 2600468598 NM_MO_01_NL_Diagnose "Diagnosefunktionen aktiv (lokaler / SG interner Nachlauf vor Wakeup)";
CM_ SG_ 2600468598 NM_MO_01_NL_WFS "Wegfahrsperre aktiv (lokaler / SG interner Nachlauf vor Wakeup)";
CM_ SG_ 2600468598 NM_MO_01_NL_EEPROM "EEPROM Zugriffe RAM/ROM Tests (lokaler / SG interner Nachlauf vor Wakeup)";
CM_ SG_ 2600468598 NM_MO_01_NL_Sonstige "Sonstige Nachläufe aktiv (lokaler / SG interner Nachlauf vor Wakeup)";
CM_ SG_ 2600468598 NM_MO_01_UDS_CC "Funktionseinschränkung aufgrund aktivem UDS-Communication Control; siehe VW80124";
CM_ SG_ 913 OBD_Calc_Load_Val "Calculated Load Value

Übertragung von Meßgrößen an das Getriebesteuergerät für Freeze Frame Abspeicherung bei Getriebefehlern

PID $04 Calculated Load Value; 0 .. 100% mit 100/255 % per bit
";
CM_ SG_ 913 OBD_Eng_Cool_Temp "Engine Coolant Temperature

Übertragung von Meßgrößen an das Getriebesteuergerät für Freeze Frame Abspeicherung bei Getriebefehlern

PID $05 Engine Coolant Temperature; -40 .. +215°C mit 1°C/bit und 40°C Offset";
CM_ SG_ 913 OBD_Abs_Throttle_Pos "Absolute Throttle Position

Übertragung von Meßgrößen an das Getriebesteuergerät für Freeze Frame Abspeicherung bei Getriebefehlern

PID $11 Absolute Throttle Position; 0 .. 100% mit 100/255 %/bit";
CM_ SG_ 913 OBD_Abs_Load_Val "Absolute Load Value

Übertragung von Meßgrößen an das Getriebesteuergerät für Freeze Frame Abspeicherung bei Getriebefehlern

PID $43 Absolute Load Value; 0 .. 25700%  mit 100/255 %/bit";
CM_ SG_ 913 OBD_Abs_Pedal_Pos "Absolute Pedal Position

Übertragung von Meßgrößen an das Getriebesteuergerät für Freeze Frame Abspeicherung bei Getriebefehlern

PID $49 Accelerator Pedal Position D; 0 .. 100% mit 100/255 %/bit";
CM_ SG_ 913 OBD_Kaltstart_Denominator "Bestimmte Diagnosen werden nur unter Kaltstartbedingungen durchgeführt, der entsprechende Denominator bei IUMPR-pflichtigen Systemen wird anhand dieses vom MSG gebildeten Signals inkrementiert. (Entspricht EVAP-Denominator)";
CM_ SG_ 913 OBD_Minimum_Trip "Grundlage OBD-Gesetz CCR 1968.2 (d)(4.3) Denominator Specifications
Bildung des General Denominator 'Normed Trip':
¿ 600 sec. (kumulativ) Zeit nach Motorstart
¿ 300 sec. (kumulativ) mit Fahrzeuggeschwindigkeit > 25 mph (40 km/h)
¿ 30 sec. (kontinuierl";
CM_ SG_ 913 OBD_Warm_Up_Cycle "Mit dem Warm-Up-Cycle wird der zentrale Verlernzähler vom Gateway inkrementiert";
CM_ SG_ 913 OBD_Normed_Trip "Gesetzlich definierte 'Normed Condition' erfüllt, 'General Denominator' darf erhöht werden";
CM_ SG_ 1630 OBD_TG_F_Status_1 "Fehlerstatus Tankfüllstandsgeber (OBD relevanter Sensor für Tankleckdiagnose)";
CM_ SG_ 1630 OBD_TG_F_Status_2 "Fehlerstatus Tankfüllstandsgeber (OBD relevanter Sensor für Tankleckdiagnose)

0x00 = kein Fehler / Init / nicht verbaut
0x01 = KS-
0x02 = KS+ (B8: nicht bedient)
0x03 = OC (Leitungsunterbrechung) (B8: nicht bedient)
0x04 = OOR+ (out of range high) ";
CM_ SG_ 1630 OBD_TG_F_Status_3 "Fehlerstatus Tankfüllstandsgeber (OBD relevanter Sensor für Tankleckdiagnose)

0x00 = kein Fehler / Init / nicht verbaut
0x01 = KS-
0x02 = KS+ (B8: nicht bedient)
0x03 = OC (Leitungsunterbrechung) (B8: nicht bedient)
0x04 = OOR+ (out of range high) ";
CM_ SG_ 1630 OBD_TG_F_Status_4 "Fehlerstatus Tankfüllstandsgeber (OBD relevanter Sensor für Tankleckdiagnose)

0x00 = kein Fehler / Init / nicht verbaut
0x01 = KS-
0x02 = KS+ (B8: nicht bedient)
0x03 = OC (Leitungsunterbrechung) (B8: nicht bedient)
0x04 = OOR+ (out of range high) ";
CM_ SG_ 1630 OBD_TG_Sens_Rohwert_1 "Rohwert des Tankgebers, nur gefiltert (gleitender Mittelwert), Ausgabe im 500ms-Raster";
CM_ SG_ 1630 OBD_TG_Sens_Rohwert_2 "Rohwert des Tankgebers, nur gefiltert (gleitender Mittelwert), Ausgabe im 500ms-Raster";
CM_ SG_ 1630 OBD_TG_Sens_Rohwert_3 "Rohwert des Tankgebers, nur gefiltert (gleitender Mittelwert), Ausgabe im 500ms-Raster";
CM_ SG_ 1630 OBD_TG_Sens_Rohwert_4 "Rohwert des Tankgebers, nur gefiltert (gleitender Mittelwert), Ausgabe im 500ms-Raster";
CM_ SG_ 1437 RSF_Tastencode_1 "Übertragung des FFB-Tastencode Remotestart zum MSG, damit MSG unabhängig vom BCM den Remotestart-Befehl auswerten kann.";
CM_ SG_ 1437 RSF_Tastencode_2 "Übertragung des FFB-Tastencode Remotestart zum MSG, damit MSG unabhängig vom BCM den Remotestart-Befehl auswerten kann.";
CM_ SG_ 1437 RSF_Tastencode_Maske "Übertragung des FFB-Tastencode Remotestart zum MSG, damit MSG unabhängig vom BCM den Remotestart-Befehl auswerten kann.";
CM_ BO_ 984 "ab MQB Reversibler Gurtstraffer im Airbag mit geändertem Charisma, rein zyklisch, Entfall KD-Fehler";
CM_ SG_ 984 RGS_VL_Texte "Zustand des Precrash-Systems";
CM_ SG_ 984 RGS_VL_Charisma_FahrPr "MLBevo: Aktuelles Fahrprogramm des Charisma-Teilnehmers (siehe Systemlastenheft Drive Select)
MQB: Istwert der Kennlinie (siehe Systemlastenheft MQB FPA)";
CM_ SG_ 984 RGS_VL_Charisma_Status "Charisma Systemstatus des Charisma-Teilnehmers

Wert 0x3 ist nur für Fahrzeuge ab MQB relevant";
CM_ SG_ 984 RGS_VL_aktiv "Aktivität des Straffermotors";
CM_ SG_ 984 RGS_VL_PC_Aktuator_Sitz "PreCrash-Aktuator Ansteuerung der Sitzfunktionen";
CM_ SG_ 984 RGS_VL_PC_Aktuator_Schiebedach "PreCrash-Aktuator Ansteuerung der Schiebedachfunktion";
CM_ SG_ 984 RGS_VL_PC_Aktuator_Fenster "PreCrash-Aktuator Ansteuerung der Fensterfunktion";
CM_ SG_ 984 RGS_VL_PC_Aktuator_Warnblinken "Warnblinken für Warnung des rückwärtigen Verkehrs bei drohender Heckkollision";
CM_ SG_ 984 RGS_VL_Precrash_Basis "Schwellenabhängige Aktuatoransteuerung für Precrash-Basis Applikation";
CM_ SG_ 984 RGS_VL_Precrash_Front "Precrash-Front Schwelle";
CM_ SG_ 984 RGS_VL_Precrash_Rear "Precrash-Rear Schwelle";
CM_ BO_ 1528 "ab MQB mit geändertem Charisma, ohne KD-Fehler";
CM_ SG_ 1528 SAK_Charisma_FahrPr "MLBevo: Aktuelles Fahrprogramm des Charisma-Teilnehmers (siehe Systemlastenheft Drive Select)
MQB: Istwert der Kennlinie (siehe Systemlastenheft MQB FPA)";
CM_ SG_ 1528 SAK_Charisma_Status "Rückmeldung an den Charisma-Master

Wert 0x3 ist nur für Fahrzeuge ab MQB relevant";
CM_ SG_ 1313 STH_LED "Funktionslampe";
CM_ SG_ 1313 STH_EKP_Anst "STH sendet die Anforderung zur Ansteuerung der EKP an den Motor, um Kraftstoffbehälter der STH zu befüllen.";
CM_ SG_ 1313 STH_Start_folgt "Thema Start/Stop: Im Stop-Modus muß das KBT einen Wiederstart anfordern, da ein STH-Start notwendig ist.";
CM_ SG_ 1313 STH_Ventiloeffnungszeit "Die Standheizung sendet an den Motor die Information darüber wie lange das Magnetventil die Wasserkreisläufe von 'klein' aus 'gross' geschaltet hat. ";
CM_ SG_ 1313 STH_Ventil_Status "Statusrückmeldung Ansteuerung 3/2 Wege-Ventil";
CM_ SG_ 1313 STH_Waermeeintrag "Signal enthält die Brenndauer in 1min-Schritten, über welche die Standheizung gelaufen ist";
CM_ SG_ 1313 STH_KVS "Kraftstoffverbrauch";
CM_ SG_ 1313 STH_Fehlerstatus "0x5 - 0x7 = nicht definiert";
CM_ SG_ 1313 STH_Heizleistung "Heizleistung in %";
CM_ SG_ 1313 STH_Motorvorwaermung "Info an der Motor, dass der Aufheizvorgang mit Motorvorwärmung erfolgt ist";
CM_ SG_ 1313 STH_war_aktiv "Bit beeinhaltet die Info, dass die Standheizung während der letzten halbe Stunde aktiv war.";
CM_ BO_ 1172 "ab MQB 7.2";
CM_ SG_ 1172 STS_01_CRC "Für MLB:
Berechnung siehe Lastenheft 'Kommunikationsabsicherung für FlexRay und CAN''

Ab MQB und MLBevo:
Berechnung siehe Lastenheft 'End-to-End Kommunikationsabsicherung''

Endwerte siehe Begleitdokument 'S-PDU Kennungsfolgen'";
CM_ SG_ 1172 STS_01_BZ "4bit Botschaftszähler, wird in jeder Sendebotschaft inkrementiert
";
CM_ SG_ 1172 STS_Anlassersperre "Wiederstartverhinderung (Anlassersperre)";
CM_ SG_ 1172 STS_Typencodierung "Typcodierung Schnittstelle für Tracking Systeme
";
CM_ SG_ 1172 STS_LIN_aktiv "Tracking System über LIN";
CM_ SG_ 1172 STS_Standlicht "statisch oder auch mit Blink_modi für Taxialarm";
CM_ SG_ 1172 STS_Fahrlicht "statisch oder auch mit Blink_modi für interm. Fahrlicht";
CM_ SG_ 1172 STS_Alarm_still "VTS hat einen Alarm erkannt. Alarm ist aber noch nicht bestätigt.";
CM_ SG_ 1172 STS_Texte "Nummer des Textes die im Kombi angezeigt werden soll";
CM_ SG_ 1172 STS_Laderelais "Signal für die Auswertung zur Anzeige der Batterie-Schwach-Anzeige im Kombi ";
CM_ SG_ 1172 STS_Summer "Warnsummer für Funkhauptschalter und Fahrschulpedal";
CM_ SG_ 1172 STS_Alarm_Blinker "Taxialarmblinken, wie DWA ohne Fanfare";
CM_ SG_ 1172 STS_Notstart "Signal zeigt an, dass ein Notstart erfolgte.";
CM_ SG_ 1172 STS_Signalhorn "Versehrte, Fahrschule oder Taxi (bei Alarm)";
CM_ SG_ 1172 STS_Leerlaufschaltung "Versetzt das Fahrzeug in einen Zustand in dem es nicht mehr auf EGas-Anforderungen reagiert";
CM_ SG_ 1413 SI_Sammel_SG_Fehler "Anzahl der gesetzten KD-Fehler direkt angeschlossener Steuergeräte der DK3 und DK4 gemäß 80127.
Hinweis: Ein Subbusmaster stellt nur die gesammelte Information der an ihn angeschlossenen Steuergeräte der DK3 und DK4 zur Verfügung.

Für ServiceKey Auswe";
CM_ SG_ 1413 SI_Rollenmode "Signal zeigt an, ob das Fahrzeug / die Empfänger in den Rollenprüfstandsmodus wechseln sollen (Rollenmode aus oder gestartet) bzw. gibt den Status des Rollenmode-Masters wieder (Rollenmode aktiv oder Fehler).";
CM_ SG_ 1413 SI_T_Mode "0x0: Transportmodus nicht aktiv
0x1: Transportmodus aktiv";
CM_ SG_ 1413 SI_NWDF "Netzwerk-Diagnose Freigebe zur zentralen Aktivierung der Netzwerkdiagnose";
CM_ SG_ 1413 SI_NWDF_gueltig "Gültigkeitsbit zu SI_NWDF gemäß Lastenheft: Zentrale Aktivierung Netzwerkdiagnose";
CM_ SG_ 1413 SI_Sammelfehler "Sammelfehlermeldung zur Anzeige im Kombi - siehe Spez. Sammelfehlermeldung
Hinweis: Einzelne Steuergeräte können zur Anpassung an den Produktionsprozess im Gateway auskodiert werden!";
CM_ SG_ 1413 GW_KD_Fehler "Kundendienstfehlerbit Gateway zur Anzeige eines im Gateway abgelegten Fehlerspeichereintrages.";
CM_ SG_ 1413 SI_BUS_01 "MQB: ACAN";
CM_ SG_ 1413 SI_BUS_02 "MQB: FCAN";
CM_ SG_ 1413 SI_BUS_03 "MQB: KCAN";
CM_ SG_ 1413 SI_BUS_04 "MQB: ICAN";
CM_ SG_ 1413 SI_BUS_05 "MQB: DiagCAN";
CM_ SG_ 1413 SI_BUS_06 "MQB: ECAN";
CM_ SG_ 1413 SI_BUS_07 "MQB: LIN1 (Energie)";
CM_ SG_ 1413 SI_BUS_08 "MQB: LIN2 (MFL)";
CM_ SG_ 1413 SI_BUS_09 "MQB: LIN3 (unbelegt)";
CM_ BO_ 288 "Vorschlag TSK-Schnittstelle MQB";
CM_ SG_ 288 TSK_06_CRC "Für MLB:
Berechnung siehe Lastenheft 'Kommunikationsabsicherung für FlexRay und CAN''

Ab MQB und MLBevo:
Berechnung siehe Lastenheft 'End-to-End Kommunikationsabsicherung''

Endwerte siehe Begleitdokument 'S-PDU Kennungsfolgen'";
CM_ SG_ 288 TSK_Radbremsmom "Bei der Schnittstelle vom TSK zum ESP soll in Folgeprojekten des B8 und insbesondere bei VW-Projekten die Ansteuerung der Bremse nicht über Sollbeschleunigung sondern Bremsmoment erfolgen.  Es handelt sich genauer um das Summenradbremsmoment, welches die ";
CM_ SG_ 288 TSK_Status "Betriebszustand des TSK-Reglers";
CM_ SG_ 288 TSK_v_Begrenzung_aktiv "Limiter oder HGB begrenzen die Beschleunigung/das Moment";
CM_ SG_ 288 TSK_Standby_Anf_ESP "Mit diesem Bit wird das aktive Bremssystem auf eine anstehende TSK-Verzögerungsanforderung vorbereitet (Überfahren Leerweg, Anlegen Bremsbeläge)";
CM_ SG_ 288 TSK_Freig_Verzoeg_Anf "Freigabe der Verzögerungsanforderung der ACC oder ggf. GRA+ Funktion für ECD Regelung im ESP";
CM_ SG_ 288 TSK_Limiter_ausgewaehlt "ACC/GRA-Betrieb nur bei nicht ausgewähltem Limiter möglich";
CM_ SG_ 288 TSK_ax_Getriebe_02 "Beschleunigungsanforderung des Beschleunigungsreglers (u. a. für ACC, GRA, Speed Limiter). Das Signal wird vom Getriebe benutzt, um die von GRA/ACC geforderte Sollbeschleunigung in dem verbrauchsgünstigsten Gang einzustellen.";
CM_ SG_ 288 TSK_Zwangszusch_ESP "Mit diesem Bit wird das ESP/ASR zwangsweise aktiviert. Bei gesetztem Bit ist ein ausgetastetes ESP (oder ASR) wieder aktiviert bzw. wird die Austastung verhindert.";
CM_ SG_ 288 TSK_zul_Regelabw "Anforderung der zulässigen Regelabweichung vom Triebstrangkoordinator. Zulässiger Betrag der Abweichung zwischen angeforderter 'TSK_Sollbeschleunigung_Getriebe' und umzusetzender Sollbeschleunigung  im Getriebe. Im TSK wird, abhängig vom Arbeitspunkt die ";
CM_ BO_ 798 "ab MQB";
CM_ SG_ 798 TSK_07_CRC "Für MLB:
Berechnung siehe Lastenheft 'Kommunikationsabsicherung für FlexRay und CAN''

Ab MQB und MLBevo:
Berechnung siehe Lastenheft 'End-to-End Kommunikationsabsicherung''

Endwerte siehe Begleitdokument 'S-PDU Kennungsfolgen'";
CM_ SG_ 798 TSK_Wunschgeschw "Zur Anzeige der Wunschgeschwindigkeit von GRA/Speedlimiter im Kombiinstrument";
CM_ SG_ 798 TSK_Texte_Primaeranz "Trigger für Anzeigetexte von GRA und Limiter, GRA Temporäranzeige (Audi) und Limiter Warnungen";
CM_ SG_ 798 TSK_Limiter_Anzeige "Signalisiert den Wunsch des MSG an das Kombiinstrument, seine Anzeige auf Limiter umzuschalten";
CM_ SG_ 798 TSK_Status_Anzeige "Signalisiert den Status von GRA oder Limiter zur Anzeige im Kombiinstrument";
CM_ BO_ 1716 "200ms bei D4 und folgende";
CM_ SG_ 1716 VIN_01_MUX "Achtung:
Die Botschaft ist nicht linear gemultiplext!!!
Sondern 0,1,0,2,0, usw.";
CM_ BO_ 175 "MQB mit Wählhebel am A-CAN";
CM_ SG_ 175 WH_Status_Sperre "Der Wählhebel kann in Getriebeposition P oder N gesperrt werden. Status der Wählhebelsperre";
CM_ SG_ 175 WH_Initialisierung "Das Bit zeigt dem Empfänger an, dass der Wählhebel in der Initialisierung ist (z.B. Reset). Das Signal steht für maximal 500ms ab Sendebeginn auf 1, danach dauerhaft auf 0.";
CM_ SG_ 175 WH_SensorPos_roh "Zustand Wählhebelposition";
CM_ SG_ 175 WH_03_BZ "4bit Botschaftszähler, wird in jeder Sendebotschaft inkrementiert
";
CM_ SG_ 175 WH_SensorPos_roh_inv "Inverser Zustand Wählhebelposition";
CM_ SG_ 175 WH_Testergebnis "Ergebnis (Antwort) des Controllertests initiert durch Test Freigabe Flag
und Testparameter 1 + 2 aus Getriebe_05";
CM_ SG_ 175 WH_Test_Aktiv "Das Bit wird auf 1 gesetzt, wenn ein gültiges Testergebnis (Antwort) gesendet wird.";
CM_ SG_ 175 WH_Status "Das Wählhebelmodul liefert aktuelle Fehlerzustände. Die Fehlereinträge werden im Getriebe-SG abgelegt.";
CM_ BO_ 916 "ersetzt WBA_02";
CM_ SG_ 916 WBA_03_CRC "Für MLB:
Berechnung siehe Lastenheft 'Kommunikationsabsicherung für FlexRay und CAN''

Ab MQB und MLBevo:
Berechnung siehe Lastenheft 'End-to-End Kommunikationsabsicherung''

Endwerte siehe Begleitdokument 'S-PDU Kennungsfolgen'";
CM_ SG_ 916 WBA_Fahrstufe_02 "Bei Automatgetrieben wird in diesem Signal die aktuelle anzuzeigende Fahrstufe ausgegeben.";
CM_ SG_ 916 WBA_ZielFahrstufe "Zielfahrprogramm (Darstellung), für getipptes S/E/M mit neuem Wählhebel im MQB";
CM_ SG_ 916 WBA_GE_Warnung_02 "Prioritätswarnungen Getriebe";
CM_ SG_ 916 WBA_eing_Gang_02 "Das Automatikgetriebe gibt den aktuell eingelegten Gang aus.
Besonderheiten:
0x0 = marktabhängig wird auf Ganganzeige zur Fahrstufe komplett verzichtet
0xA = kurzzeitige Unterdrückung der Ganganzeige (z. B. Segeln, Zwischenstellung, etc.)";
CM_ SG_ 916 WBA_GE_Texte "Fahrerhinweise für das Kombi";
CM_ SG_ 916 WBA_Segeln_aktiv "Getriebe geht in den Segelbetrieb";
CM_ SG_ 916 WBA_Schaltschema "Bei Automatikgetrieben wird in diesem Signal die aktuelle, eingelegte Fahrstufe (=Wählhebelposition) ausgegeben.";
CM_ SG_ 1602 WIV_Verschleissindex "Bei Otto Verbrauch, bei Diesel Verschleiss";
CM_ SG_ 1602 WIV_Russindex "Nur für Diesel, Rußwert, bei Otto Wert = 0";
CM_ SG_ 1602 WIV_t_min "Minimales Wartungsintervall für WIV in Monaten";
CM_ SG_ 1602 WIV_t_max "Maximales Wartungsintervall für WIV in Monaten";
CM_ SG_ 1602 WIV_W_min "Minimales Wartungsintervall für WIV in km";
CM_ SG_ 1602 WIV_W_max "Maximales Wartungsintervall für WIV in km";
BA_DEF_ BO_  "GenMsgPDUConstants" STRING ;
BA_DEF_ BO_  "GenMsgAutoGenDsp" ENUM  "No","Yes";
BA_DEF_ BO_  "GenMsgAutoGenSnd" ENUM  "No","Yes";
BA_DEF_ BO_  "GenMsgCycleTime" INT 0 65535;
BA_DEF_ BO_  "GenMsgCycleTimeFast" INT 0 65535;
BA_DEF_ BO_  "GenMsgDelayTime" INT 0 100000;
BA_DEF_ BO_  "GenMsgILSupport" ENUM  "No","Yes";
BA_DEF_ BO_  "GenMsgNrOfRepetition" INT 0 100;
BA_DEF_ BO_  "GenMsgSendType" ENUM  "Cyclic","not_used","not_used","not_used","not_used","not_used","not_used","IfActive","NoMsgSendType";
BA_DEF_ BO_  "GenMsgStartDelayTime" INT 0 100000;
BA_DEF_ BO_  "NmMessage" ENUM  "No","Yes";
BA_DEF_ BO_  "NmhMessage" ENUM  "No","Yes";
BA_DEF_ BO_  "VAGTP20_API" HEX 0 255;
BA_DEF_ BO_  "VAGTP20_DynConnection" ENUM  "No","Yes";
BA_DEF_ BO_  "VAGTP20_DynSetup" ENUM  "No","Yes";
BA_DEF_ BO_  "VAGTP20_StatConnection" ENUM  "No","Yes";
BA_DEF_ BO_  "Timeoutzeit" INT 0 1000000;
BA_DEF_ BO_  "DiagRequest" ENUM  "No","Yes";
BA_DEF_ BO_  "DiagResponse" ENUM  "No","Yes";
BA_DEF_ BO_  "DiagState" ENUM  "No","Yes";
BA_DEF_ BO_  "GenMsgChkConstant" HEX 0 4095;
BA_DEF_ SG_  "GenSigAutoGenDsp" ENUM  "No","Yes";
BA_DEF_ SG_  "GenSigAutoGenSnd" ENUM  "No","Yes";
BA_DEF_ SG_  "GenSigEnvVarType" ENUM  "int","float","undef";
BA_DEF_ SG_  "GenSigInactiveValue" INT -2147483648 2147483647;
BA_DEF_ SG_  "GenSigSendType" ENUM  "Cyclic","OnWrite","OnWriteWithRepetition","OnChange","OnChangeWithRepetition","IfActive","IfActiveWithRepetition","NoSigSendType","OnChangeAndIfActive","OnChangeAndIfActiveWithRepetition";
BA_DEF_ SG_  "GenSigStartValue" INT -2147483648 2147483647;
BA_DEF_ SG_  "NWM-WakeupAllowed" ENUM  "No","Yes";
BA_DEF_ SG_  "GenSigFuncType" ENUM  "NoFunction","MsgCounter","CRC-8","XOR","XOR-2","DatedBit","SW-Kl15","CHK","Constant","Protocol";
BA_DEF_ SG_  "GenSigSwitchedByIgnition" ENUM  "No","Yes";
BA_DEF_ SG_  "Fehlerwert" HEX 0 2147483647;
BA_DEF_ SG_  "GenSigMissingSourceValue" HEX 0 2147483647;
BA_DEF_REL_ BU_SG_REL_  "GenSigTimeoutTime" INT 0 65535;
BA_DEF_DEF_  "GenMsgPDUConstants" "";
BA_DEF_DEF_  "GenMsgAutoGenDsp" "Yes";
BA_DEF_DEF_  "GenMsgAutoGenSnd" "Yes";
BA_DEF_DEF_  "GenMsgCycleTime" 0;
BA_DEF_DEF_  "GenMsgCycleTimeFast" 0;
BA_DEF_DEF_  "GenMsgDelayTime" 0;
BA_DEF_DEF_  "GenMsgILSupport" "No";
BA_DEF_DEF_  "GenMsgNrOfRepetition" 0;
BA_DEF_DEF_  "GenMsgSendType" "NoMsgSendType";
BA_DEF_DEF_  "GenMsgStartDelayTime" 0;
BA_DEF_DEF_  "NmMessage" "No";
BA_DEF_DEF_  "NmhMessage" "No";
BA_DEF_DEF_  "VAGTP20_API" 0;
BA_DEF_DEF_  "VAGTP20_DynConnection" "No";
BA_DEF_DEF_  "VAGTP20_DynSetup" "No";
BA_DEF_DEF_  "VAGTP20_StatConnection" "No";
BA_DEF_DEF_  "Timeoutzeit" 0;
BA_DEF_DEF_  "DiagRequest" "No";
BA_DEF_DEF_  "DiagResponse" "No";
BA_DEF_DEF_  "DiagState" "No";
BA_DEF_DEF_  "GenMsgChkConstant" 0;
BA_DEF_DEF_  "GenSigAutoGenDsp" "No";
BA_DEF_DEF_  "GenSigAutoGenSnd" "No";
BA_DEF_DEF_  "GenSigEnvVarType" "undef";
BA_DEF_DEF_  "GenSigInactiveValue" 0;
BA_DEF_DEF_  "GenSigSendType" "NoSigSendType";
BA_DEF_DEF_  "GenSigStartValue" 0;
BA_DEF_DEF_  "NWM-WakeupAllowed" "No";
BA_DEF_DEF_  "GenSigFuncType" "NoFunction";
BA_DEF_DEF_  "GenSigSwitchedByIgnition" "Yes";
BA_DEF_DEF_  "Fehlerwert" 0;
BA_DEF_DEF_  "GenSigMissingSourceValue" 0;
BA_DEF_DEF_REL_ "GenSigTimeoutTime" 0;
BA_ "GenMsgSendType" BO_ 812 0;
BA_ "GenMsgILSupport" BO_ 812 1;
BA_ "GenMsgCycleTime" BO_ 812 50;
BA_ "GenMsgSendType" BO_ 1648 0;
BA_ "GenMsgILSupport" BO_ 1648 1;
BA_ "GenMsgDelayTime" BO_ 1648 20;
BA_ "GenMsgCycleTime" BO_ 1648 500;
BA_ "GenMsgSendType" BO_ 289 0;
BA_ "GenMsgILSupport" BO_ 289 1;
BA_ "GenMsgCycleTime" BO_ 289 20;
BA_ "GenMsgSendType" BO_ 967 0;
BA_ "GenMsgILSupport" BO_ 967 1;
BA_ "GenMsgCycleTime" BO_ 967 100;
BA_ "GenMsgPDUConstants" BO_ 1601 "0x47,0x47,0x47,0x47,0x47,0x47,0x47,0x47,0x47,0x47,0x47,0x47,0x47,0x47,0x47,0x47";
BA_ "GenMsgChkConstant" BO_ 1601 71;
BA_ "GenMsgSendType" BO_ 1601 0;
BA_ "GenMsgILSupport" BO_ 1601 1;
BA_ "GenMsgCycleTime" BO_ 1601 1000;
BA_ "GenMsgPDUConstants" BO_ 157 "0x9d,0x9d,0x9d,0x9d,0x9d,0x9d,0x9d,0x9d,0x9d,0x9d,0x9d,0x9d,0x9d,0x9d,0x9d,0x9d";
BA_ "GenMsgChkConstant" BO_ 157 157;
BA_ "GenMsgSendType" BO_ 157 0;
BA_ "GenMsgILSupport" BO_ 157 1;
BA_ "GenMsgCycleTime" BO_ 157 20;
BA_ "GenMsgSendType" BO_ 811 0;
BA_ "GenMsgILSupport" BO_ 811 1;
BA_ "GenMsgCycleTime" BO_ 811 50;
BA_ "GenMsgILSupport" BO_ 16 1;
BA_ "GenMsgILSupport" BO_ 20 1;
BA_ "GenMsgILSupport" BO_ 22 1;
BA_ "GenMsgILSupport" BO_ 24 1;
BA_ "NmhMessage" BO_ 2600468501 1;
BA_ "GenMsgCycleTime" BO_ 2600468501 200;
BA_ "NmhMessage" BO_ 2600468604 1;
BA_ "GenMsgCycleTime" BO_ 2600468604 200;
BA_ "NmhMessage" BO_ 2600468496 1;
BA_ "GenMsgCycleTime" BO_ 2600468496 200;
BA_ "NmhMessage" BO_ 2600468599 1;
BA_ "GenMsgCycleTime" BO_ 2600468599 200;
BA_ "NmhMessage" BO_ 2600468603 1;
BA_ "GenMsgCycleTime" BO_ 2600468603 200;
BA_ "NmhMessage" BO_ 2600468598 1;
BA_ "GenMsgCycleTime" BO_ 2600468598 200;
BA_ "GenMsgSendType" BO_ 913 0;
BA_ "GenMsgILSupport" BO_ 913 1;
BA_ "GenMsgCycleTime" BO_ 913 100;
BA_ "GenMsgSendType" BO_ 1630 0;
BA_ "GenMsgILSupport" BO_ 1630 1;
BA_ "GenMsgCycleTime" BO_ 1630 500;
BA_ "GenMsgSendType" BO_ 1437 7;
BA_ "GenMsgILSupport" BO_ 1437 1;
BA_ "GenMsgCycleTimeFast" BO_ 1437 500;
BA_ "GenMsgNrOfRepetition" BO_ 1437 5;
BA_ "GenMsgAutoGenSnd" BO_ 2033 0;
BA_ "GenMsgAutoGenDsp" BO_ 2033 0;
BA_ "GenMsgAutoGenSnd" BO_ 2041 0;
BA_ "GenMsgAutoGenDsp" BO_ 2041 0;
BA_ "GenMsgSendType" BO_ 984 0;
BA_ "GenMsgILSupport" BO_ 984 1;
BA_ "GenMsgCycleTime" BO_ 984 100;
BA_ "GenMsgSendType" BO_ 1528 0;
BA_ "GenMsgCycleTime" BO_ 1528 1000;
BA_ "GenMsgSendType" BO_ 1313 0;
BA_ "GenMsgILSupport" BO_ 1313 1;
BA_ "GenMsgCycleTime" BO_ 1313 200;
BA_ "GenMsgPDUConstants" BO_ 1172 "0x90,0x90,0x90,0x90,0x90,0x90,0x90,0x90,0x90,0x90,0x90,0x90,0x90,0x90,0x90,0x90";
BA_ "GenMsgChkConstant" BO_ 1172 144;
BA_ "GenMsgSendType" BO_ 1172 0;
BA_ "GenMsgILSupport" BO_ 1172 1;
BA_ "GenMsgDelayTime" BO_ 1172 20;
BA_ "GenMsgCycleTime" BO_ 1172 200;
BA_ "GenMsgSendType" BO_ 1413 0;
BA_ "GenMsgILSupport" BO_ 1413 1;
BA_ "GenMsgDelayTime" BO_ 1413 10;
BA_ "GenMsgCycleTime" BO_ 1413 1000;
BA_ "GenMsgPDUConstants" BO_ 288 "0xc4,0xe2,0x4f,0xe4,0xf8,0x2f,0x56,0x81,0x9f,0xe5,0x83,0x44,0x05,0x3f,0x97,0xdf";
BA_ "GenMsgSendType" BO_ 288 0;
BA_ "GenMsgCycleTime" BO_ 288 20;
BA_ "GenMsgPDUConstants" BO_ 798 "0x78,0x68,0x3a,0x31,0x16,0x08,0x4f,0xde,0xf7,0x35,0x19,0xe6,0x28,0x2f,0x59,0x82";
BA_ "GenMsgChkConstant" BO_ 798 17;
BA_ "GenMsgSendType" BO_ 798 0;
BA_ "GenMsgILSupport" BO_ 798 1;
BA_ "GenMsgCycleTime" BO_ 798 50;
BA_ "GenMsgSendType" BO_ 1716 0;
BA_ "GenMsgILSupport" BO_ 1716 1;
BA_ "GenMsgCycleTime" BO_ 1716 200;
BA_ "GenMsgSendType" BO_ 175 0;
BA_ "GenMsgCycleTime" BO_ 175 10;
BA_ "GenMsgPDUConstants" BO_ 916 "0x47,0x94,0x92,0x6a,0x67,0xb5,0x0d,0x38,0xe3,0x8a,0x5d,0xb4,0x54,0xab,0xae,0x27";
BA_ "GenMsgSendType" BO_ 916 0;
BA_ "GenMsgILSupport" BO_ 916 1;
BA_ "GenMsgDelayTime" BO_ 916 10;
BA_ "GenMsgCycleTime" BO_ 916 160;
BA_ "GenMsgSendType" BO_ 1602 0;
BA_ "GenMsgILSupport" BO_ 1602 1;
BA_ "GenMsgDelayTime" BO_ 1602 200;
BA_ "GenMsgCycleTime" BO_ 1602 2000;
BA_ "GenSigSwitchedByIgnition" SG_ 812 MO_Prio_MAX_Wunschdrehzahl 0;
BA_ "GenSigSendType" SG_ 812 MO_Prio_MAX_Wunschdrehzahl 0;
BA_ "GenSigEnvVarType" SG_ 812 MO_Prio_MAX_Wunschdrehzahl 0;
BA_ "GenSigAutoGenSnd" SG_ 812 MO_Prio_MAX_Wunschdrehzahl 1;
BA_ "GenSigAutoGenDsp" SG_ 812 MO_Prio_MAX_Wunschdrehzahl 1;
BA_ "GenSigSwitchedByIgnition" SG_ 812 MO_Prio_MIN_Wunschdrehzahl 0;
BA_ "GenSigSendType" SG_ 812 MO_Prio_MIN_Wunschdrehzahl 0;
BA_ "GenSigEnvVarType" SG_ 812 MO_Prio_MIN_Wunschdrehzahl 0;
BA_ "GenSigAutoGenSnd" SG_ 812 MO_Prio_MIN_Wunschdrehzahl 1;
BA_ "GenSigAutoGenDsp" SG_ 812 MO_Prio_MIN_Wunschdrehzahl 1;
BA_ "GenSigSwitchedByIgnition" SG_ 812 MO_Luftpfad_aktiv 0;
BA_ "GenSigSendType" SG_ 812 MO_Luftpfad_aktiv 0;
BA_ "GenSigEnvVarType" SG_ 812 MO_Luftpfad_aktiv 0;
BA_ "GenSigAutoGenSnd" SG_ 812 MO_Luftpfad_aktiv 1;
BA_ "GenSigAutoGenDsp" SG_ 812 MO_Luftpfad_aktiv 1;
BA_ "GenSigSwitchedByIgnition" SG_ 812 MO_v_Begrenz_Aktivierbar 0;
BA_ "GenSigSendType" SG_ 812 MO_v_Begrenz_Aktivierbar 0;
BA_ "GenSigEnvVarType" SG_ 812 MO_v_Begrenz_Aktivierbar 0;
BA_ "GenSigAutoGenSnd" SG_ 812 MO_v_Begrenz_Aktivierbar 1;
BA_ "GenSigAutoGenDsp" SG_ 812 MO_v_Begrenz_Aktivierbar 1;
BA_ "GenSigSwitchedByIgnition" SG_ 812 MO_Drehzahlbeeinflussung 0;
BA_ "GenSigSendType" SG_ 812 MO_Drehzahlbeeinflussung 0;
BA_ "GenSigEnvVarType" SG_ 812 MO_Drehzahlbeeinflussung 1;
BA_ "GenSigAutoGenSnd" SG_ 812 MO_Drehzahlbeeinflussung 1;
BA_ "GenSigAutoGenDsp" SG_ 812 MO_Drehzahlbeeinflussung 1;
BA_ "Fehlerwert" SG_ 812 MO_MIN_Wunschdrehzahl 255;
BA_ "GenSigSwitchedByIgnition" SG_ 812 MO_MIN_Wunschdrehzahl 0;
BA_ "GenSigSendType" SG_ 812 MO_MIN_Wunschdrehzahl 0;
BA_ "GenSigEnvVarType" SG_ 812 MO_MIN_Wunschdrehzahl 0;
BA_ "GenSigAutoGenSnd" SG_ 812 MO_MIN_Wunschdrehzahl 1;
BA_ "GenSigAutoGenDsp" SG_ 812 MO_MIN_Wunschdrehzahl 1;
BA_ "Fehlerwert" SG_ 812 MO_MAX_Wunschdrehzahl 511;
BA_ "GenSigSwitchedByIgnition" SG_ 812 MO_MAX_Wunschdrehzahl 0;
BA_ "GenSigSendType" SG_ 812 MO_MAX_Wunschdrehzahl 0;
BA_ "GenSigEnvVarType" SG_ 812 MO_MAX_Wunschdrehzahl 0;
BA_ "GenSigAutoGenSnd" SG_ 812 MO_MAX_Wunschdrehzahl 1;
BA_ "GenSigAutoGenDsp" SG_ 812 MO_MAX_Wunschdrehzahl 1;
BA_ "GenSigSwitchedByIgnition" SG_ 812 MO_Charisma_FahrPr 0;
BA_ "GenSigSendType" SG_ 812 MO_Charisma_FahrPr 0;
BA_ "GenSigEnvVarType" SG_ 812 MO_Charisma_FahrPr 0;
BA_ "GenSigAutoGenSnd" SG_ 812 MO_Charisma_FahrPr 1;
BA_ "GenSigAutoGenDsp" SG_ 812 MO_Charisma_FahrPr 1;
BA_ "GenSigSwitchedByIgnition" SG_ 812 MO_Charisma_Status 0;
BA_ "GenSigSendType" SG_ 812 MO_Charisma_Status 0;
BA_ "GenSigEnvVarType" SG_ 812 MO_Charisma_Status 0;
BA_ "GenSigAutoGenSnd" SG_ 812 MO_Charisma_Status 1;
BA_ "GenSigAutoGenDsp" SG_ 812 MO_Charisma_Status 1;
BA_ "GenSigSwitchedByIgnition" SG_ 1648 MO_Hybrid_StartStopp_LED 0;
BA_ "GenSigSendType" SG_ 1648 MO_Hybrid_StartStopp_LED 3;
BA_ "GenSigAutoGenSnd" SG_ 1648 MO_Hybrid_StartStopp_LED 1;
BA_ "GenSigAutoGenDsp" SG_ 1648 MO_Hybrid_StartStopp_LED 1;
BA_ "GenSigSwitchedByIgnition" SG_ 1648 MO_Eis_Offroad_LED 0;
BA_ "GenSigSendType" SG_ 1648 MO_Eis_Offroad_LED 3;
BA_ "GenSigAutoGenSnd" SG_ 1648 MO_Eis_Offroad_LED 1;
BA_ "GenSigAutoGenDsp" SG_ 1648 MO_Eis_Offroad_LED 1;
BA_ "GenSigSwitchedByIgnition" SG_ 1648 MO_Anzahl_Abgesch_Zyl 0;
BA_ "GenSigSendType" SG_ 1648 MO_Anzahl_Abgesch_Zyl 3;
BA_ "GenSigEnvVarType" SG_ 1648 MO_Anzahl_Abgesch_Zyl 0;
BA_ "GenSigAutoGenSnd" SG_ 1648 MO_Anzahl_Abgesch_Zyl 1;
BA_ "GenSigAutoGenDsp" SG_ 1648 MO_Anzahl_Abgesch_Zyl 1;
BA_ "GenSigSwitchedByIgnition" SG_ 1648 MO_Zylabsch_Texte 0;
BA_ "GenSigSendType" SG_ 1648 MO_Zylabsch_Texte 0;
BA_ "GenSigEnvVarType" SG_ 1648 MO_Zylabsch_Texte 0;
BA_ "GenSigAutoGenSnd" SG_ 1648 MO_Zylabsch_Texte 1;
BA_ "GenSigAutoGenDsp" SG_ 1648 MO_Zylabsch_Texte 1;
BA_ "GenSigSwitchedByIgnition" SG_ 1648 MO_E85_BS_Texte 0;
BA_ "GenSigSendType" SG_ 1648 MO_E85_BS_Texte 0;
BA_ "GenSigEnvVarType" SG_ 1648 MO_E85_BS_Texte 0;
BA_ "GenSigAutoGenSnd" SG_ 1648 MO_E85_BS_Texte 1;
BA_ "GenSigAutoGenDsp" SG_ 1648 MO_E85_BS_Texte 1;
BA_ "GenSigSwitchedByIgnition" SG_ 1648 MO_Drehzahl_Warnung 0;
BA_ "GenSigSendType" SG_ 1648 MO_Drehzahl_Warnung 0;
BA_ "GenSigEnvVarType" SG_ 1648 MO_Drehzahl_Warnung 0;
BA_ "GenSigAutoGenSnd" SG_ 1648 MO_Drehzahl_Warnung 1;
BA_ "GenSigAutoGenDsp" SG_ 1648 MO_Drehzahl_Warnung 1;
BA_ "GenSigSwitchedByIgnition" SG_ 1648 MO_obere_Drehzahlgrenze 0;
BA_ "GenSigSendType" SG_ 1648 MO_obere_Drehzahlgrenze 0;
BA_ "GenSigEnvVarType" SG_ 1648 MO_obere_Drehzahlgrenze 0;
BA_ "GenSigAutoGenSnd" SG_ 1648 MO_obere_Drehzahlgrenze 1;
BA_ "GenSigAutoGenDsp" SG_ 1648 MO_obere_Drehzahlgrenze 1;
BA_ "Fehlerwert" SG_ 289 MO_Fahrpedalrohwert_01 255;
BA_ "GenSigSwitchedByIgnition" SG_ 289 MO_Fahrpedalrohwert_01 0;
BA_ "GenSigSendType" SG_ 289 MO_Fahrpedalrohwert_01 0;
BA_ "GenSigEnvVarType" SG_ 289 MO_Fahrpedalrohwert_01 1;
BA_ "GenSigAutoGenSnd" SG_ 289 MO_Fahrpedalrohwert_01 1;
BA_ "GenSigAutoGenDsp" SG_ 289 MO_Fahrpedalrohwert_01 1;
BA_ "GenSigSwitchedByIgnition" SG_ 289 MO_QBit_Fahrpedalwerte_01 0;
BA_ "GenSigStartValue" SG_ 289 MO_QBit_Fahrpedalwerte_01 1;
BA_ "GenSigSendType" SG_ 289 MO_QBit_Fahrpedalwerte_01 0;
BA_ "GenSigEnvVarType" SG_ 289 MO_QBit_Fahrpedalwerte_01 0;
BA_ "GenSigAutoGenSnd" SG_ 289 MO_QBit_Fahrpedalwerte_01 1;
BA_ "GenSigAutoGenDsp" SG_ 289 MO_QBit_Fahrpedalwerte_01 1;
BA_ "Fehlerwert" SG_ 289 MO_Fahrpedalgradient 255;
BA_ "GenSigSwitchedByIgnition" SG_ 289 MO_Fahrpedalgradient 0;
BA_ "GenSigSendType" SG_ 289 MO_Fahrpedalgradient 0;
BA_ "GenSigEnvVarType" SG_ 289 MO_Fahrpedalgradient 1;
BA_ "GenSigAutoGenSnd" SG_ 289 MO_Fahrpedalgradient 1;
BA_ "GenSigAutoGenDsp" SG_ 289 MO_Fahrpedalgradient 1;
BA_ "GenSigSwitchedByIgnition" SG_ 289 MO_Sig_Fahrpedalgradient 0;
BA_ "GenSigSendType" SG_ 289 MO_Sig_Fahrpedalgradient 0;
BA_ "GenSigAutoGenSnd" SG_ 289 MO_Sig_Fahrpedalgradient 1;
BA_ "GenSigAutoGenDsp" SG_ 289 MO_Sig_Fahrpedalgradient 1;
BA_ "Fehlerwert" SG_ 289 MO_rel_Saugrohrdruck 63;
BA_ "GenSigSwitchedByIgnition" SG_ 289 MO_rel_Saugrohrdruck 0;
BA_ "GenSigSendType" SG_ 289 MO_rel_Saugrohrdruck 0;
BA_ "GenSigAutoGenSnd" SG_ 289 MO_rel_Saugrohrdruck 1;
BA_ "GenSigAutoGenDsp" SG_ 289 MO_rel_Saugrohrdruck 1;
BA_ "GenSigSwitchedByIgnition" SG_ 289 MO_rel_Saugrohrdruck_gem_err 0;
BA_ "GenSigSendType" SG_ 289 MO_rel_Saugrohrdruck_gem_err 0;
BA_ "GenSigAutoGenSnd" SG_ 289 MO_rel_Saugrohrdruck_gem_err 1;
BA_ "GenSigAutoGenDsp" SG_ 289 MO_rel_Saugrohrdruck_gem_err 1;
BA_ "GenSigSwitchedByIgnition" SG_ 289 MO_Moment_im_Leerlauf 0;
BA_ "GenSigSendType" SG_ 289 MO_Moment_im_Leerlauf 0;
BA_ "GenSigEnvVarType" SG_ 289 MO_Moment_im_Leerlauf 0;
BA_ "GenSigAutoGenSnd" SG_ 289 MO_Moment_im_Leerlauf 1;
BA_ "GenSigAutoGenDsp" SG_ 289 MO_Moment_im_Leerlauf 1;
BA_ "GenSigSwitchedByIgnition" SG_ 289 MO_Schubabschaltung 0;
BA_ "GenSigSendType" SG_ 289 MO_Schubabschaltung 0;
BA_ "GenSigAutoGenSnd" SG_ 289 MO_Schubabschaltung 1;
BA_ "GenSigAutoGenDsp" SG_ 289 MO_Schubabschaltung 1;
BA_ "Fehlerwert" SG_ 289 MO_Solldrehz_Leerlauf 255;
BA_ "GenSigSwitchedByIgnition" SG_ 289 MO_Solldrehz_Leerlauf 0;
BA_ "GenSigSendType" SG_ 289 MO_Solldrehz_Leerlauf 0;
BA_ "GenSigEnvVarType" SG_ 289 MO_Solldrehz_Leerlauf 0;
BA_ "GenSigAutoGenSnd" SG_ 289 MO_Solldrehz_Leerlauf 1;
BA_ "GenSigAutoGenDsp" SG_ 289 MO_Solldrehz_Leerlauf 1;
BA_ "GenSigSwitchedByIgnition" SG_ 967 MO_Kuehlerluefter_MUX 0;
BA_ "GenSigSendType" SG_ 967 MO_Kuehlerluefter_MUX 0;
BA_ "GenSigAutoGenSnd" SG_ 967 MO_Kuehlerluefter_MUX 1;
BA_ "GenSigAutoGenDsp" SG_ 967 MO_Kuehlerluefter_MUX 1;
BA_ "Fehlerwert" SG_ 967 MO_Kuehlerluefter_1 127;
BA_ "GenSigSwitchedByIgnition" SG_ 967 MO_Kuehlerluefter_1 0;
BA_ "GenSigStartValue" SG_ 967 MO_Kuehlerluefter_1 126;
BA_ "GenSigAutoGenSnd" SG_ 967 MO_Kuehlerluefter_1 1;
BA_ "GenSigAutoGenDsp" SG_ 967 MO_Kuehlerluefter_1 1;
BA_ "Fehlerwert" SG_ 967 MO_Kuehlerluefter_2 127;
BA_ "GenSigSwitchedByIgnition" SG_ 967 MO_Kuehlerluefter_2 0;
BA_ "GenSigStartValue" SG_ 967 MO_Kuehlerluefter_2 126;
BA_ "GenSigAutoGenSnd" SG_ 967 MO_Kuehlerluefter_2 1;
BA_ "GenSigAutoGenDsp" SG_ 967 MO_Kuehlerluefter_2 1;
BA_ "GenSigSwitchedByIgnition" SG_ 967 MO_HYB_Status_HV_Ladung 0;
BA_ "GenSigSendType" SG_ 967 MO_HYB_Status_HV_Ladung 0;
BA_ "GenSigSwitchedByIgnition" SG_ 967 WIV_Anzeige_aktiv 0;
BA_ "GenSigSendType" SG_ 967 WIV_Anzeige_aktiv 0;
BA_ "GenSigEnvVarType" SG_ 967 WIV_Anzeige_aktiv 0;
BA_ "GenSigAutoGenSnd" SG_ 967 WIV_Anzeige_aktiv 1;
BA_ "GenSigAutoGenDsp" SG_ 967 WIV_Anzeige_aktiv 1;
BA_ "GenSigSwitchedByIgnition" SG_ 967 WIV_Oelmin_Warn 0;
BA_ "GenSigSendType" SG_ 967 WIV_Oelmin_Warn 0;
BA_ "GenSigEnvVarType" SG_ 967 WIV_Oelmin_Warn 0;
BA_ "GenSigAutoGenSnd" SG_ 967 WIV_Oelmin_Warn 1;
BA_ "GenSigAutoGenDsp" SG_ 967 WIV_Oelmin_Warn 1;
BA_ "GenSigSwitchedByIgnition" SG_ 967 WIV_Sensorfehler 0;
BA_ "GenSigSendType" SG_ 967 WIV_Sensorfehler 0;
BA_ "GenSigEnvVarType" SG_ 967 WIV_Sensorfehler 0;
BA_ "GenSigAutoGenSnd" SG_ 967 WIV_Sensorfehler 1;
BA_ "GenSigAutoGenDsp" SG_ 967 WIV_Sensorfehler 1;
BA_ "GenSigSwitchedByIgnition" SG_ 967 WIV_Schieflage 0;
BA_ "GenSigSendType" SG_ 967 WIV_Schieflage 0;
BA_ "GenSigEnvVarType" SG_ 967 WIV_Schieflage 0;
BA_ "GenSigAutoGenSnd" SG_ 967 WIV_Schieflage 1;
BA_ "GenSigAutoGenDsp" SG_ 967 WIV_Schieflage 1;
BA_ "GenSigSwitchedByIgnition" SG_ 967 WIV_Oelstand 0;
BA_ "GenSigSendType" SG_ 967 WIV_Oelstand 0;
BA_ "GenSigEnvVarType" SG_ 967 WIV_Oelstand 1;
BA_ "GenSigAutoGenSnd" SG_ 967 WIV_Oelstand 1;
BA_ "GenSigAutoGenDsp" SG_ 967 WIV_Oelstand 1;
BA_ "GenSigSwitchedByIgnition" SG_ 967 MO_Zustand_HWP 0;
BA_ "GenSigStartValue" SG_ 967 MO_Zustand_HWP 1;
BA_ "GenSigSendType" SG_ 967 MO_Zustand_HWP 0;
BA_ "GenSigSwitchedByIgnition" SG_ 967 WIV_Oelsystem_aktiv 0;
BA_ "GenSigSendType" SG_ 967 WIV_Oelsystem_aktiv 0;
BA_ "GenSigEnvVarType" SG_ 967 WIV_Oelsystem_aktiv 0;
BA_ "GenSigAutoGenSnd" SG_ 967 WIV_Oelsystem_aktiv 1;
BA_ "GenSigAutoGenDsp" SG_ 967 WIV_Oelsystem_aktiv 1;
BA_ "GenSigSwitchedByIgnition" SG_ 967 WIV_nicht_betriebswarm 0;
BA_ "GenSigSendType" SG_ 967 WIV_nicht_betriebswarm 0;
BA_ "GenSigEnvVarType" SG_ 967 WIV_nicht_betriebswarm 0;
BA_ "GenSigAutoGenSnd" SG_ 967 WIV_nicht_betriebswarm 1;
BA_ "GenSigAutoGenDsp" SG_ 967 WIV_nicht_betriebswarm 1;
BA_ "GenSigSwitchedByIgnition" SG_ 967 WIV_Ueberfuell_Warn 0;
BA_ "GenSigSendType" SG_ 967 WIV_Ueberfuell_Warn 0;
BA_ "GenSigEnvVarType" SG_ 967 WIV_Ueberfuell_Warn 0;
BA_ "GenSigAutoGenSnd" SG_ 967 WIV_Ueberfuell_Warn 1;
BA_ "GenSigAutoGenDsp" SG_ 967 WIV_Ueberfuell_Warn 1;
BA_ "GenSigSwitchedByIgnition" SG_ 967 WIV_laufender_Motor 0;
BA_ "GenSigSendType" SG_ 967 WIV_laufender_Motor 0;
BA_ "GenSigEnvVarType" SG_ 967 WIV_laufender_Motor 0;
BA_ "GenSigAutoGenSnd" SG_ 967 WIV_laufender_Motor 1;
BA_ "GenSigAutoGenDsp" SG_ 967 WIV_laufender_Motor 1;
BA_ "GenSigSwitchedByIgnition" SG_ 967 MO_HYB_Text_1 0;
BA_ "GenSigSendType" SG_ 967 MO_HYB_Text_1 0;
BA_ "GenSigSwitchedByIgnition" SG_ 967 MO_HYB_Text_2 0;
BA_ "GenSigSendType" SG_ 967 MO_HYB_Text_2 0;
BA_ "GenSigSwitchedByIgnition" SG_ 967 MO_HYB_Text_3 0;
BA_ "GenSigSendType" SG_ 967 MO_HYB_Text_3 0;
BA_ "GenSigSwitchedByIgnition" SG_ 967 MO_HYB_Text_4 0;
BA_ "GenSigSendType" SG_ 967 MO_HYB_Text_4 0;
BA_ "GenSigSwitchedByIgnition" SG_ 967 MO_Text_Motorstart 0;
BA_ "GenSigSendType" SG_ 967 MO_Text_Motorstart 0;
BA_ "GenSigAutoGenSnd" SG_ 967 MO_Text_Motorstart 1;
BA_ "GenSigAutoGenDsp" SG_ 967 MO_Text_Motorstart 1;
BA_ "GenSigSwitchedByIgnition" SG_ 967 MO_HYB_Text_5 0;
BA_ "GenSigSendType" SG_ 967 MO_HYB_Text_5 0;
BA_ "GenSigSwitchedByIgnition" SG_ 967 MO_HYB_Text_6 0;
BA_ "GenSigSendType" SG_ 967 MO_HYB_Text_6 0;
BA_ "GenSigSwitchedByIgnition" SG_ 967 MO_HYB_Text_7 0;
BA_ "GenSigSendType" SG_ 967 MO_HYB_Text_7 0;
BA_ "GenSigSwitchedByIgnition" SG_ 967 MO_Text_Partikelfil_Reg 0;
BA_ "GenSigSendType" SG_ 967 MO_Text_Partikelfil_Reg 0;
BA_ "GenSigEnvVarType" SG_ 967 MO_Text_Partikelfil_Reg 0;
BA_ "GenSigAutoGenSnd" SG_ 967 MO_Text_Partikelfil_Reg 1;
BA_ "GenSigAutoGenDsp" SG_ 967 MO_Text_Partikelfil_Reg 1;
BA_ "GenSigSwitchedByIgnition" SG_ 967 WIV_Oelmenge 0;
BA_ "GenSigSendType" SG_ 967 WIV_Oelmenge 0;
BA_ "GenSigEnvVarType" SG_ 967 WIV_Oelmenge 0;
BA_ "GenSigAutoGenSnd" SG_ 967 WIV_Oelmenge 1;
BA_ "GenSigAutoGenDsp" SG_ 967 WIV_Oelmenge 1;
BA_ "GenSigSwitchedByIgnition" SG_ 967 MO_Systemlampe 0;
BA_ "GenSigSendType" SG_ 967 MO_Systemlampe 0;
BA_ "GenSigEnvVarType" SG_ 967 MO_Systemlampe 0;
BA_ "GenSigAutoGenSnd" SG_ 967 MO_Systemlampe 1;
BA_ "GenSigAutoGenDsp" SG_ 967 MO_Systemlampe 1;
BA_ "GenSigSwitchedByIgnition" SG_ 967 MO_OBD2_Lampe 0;
BA_ "GenSigSendType" SG_ 967 MO_OBD2_Lampe 0;
BA_ "GenSigEnvVarType" SG_ 967 MO_OBD2_Lampe 0;
BA_ "GenSigAutoGenSnd" SG_ 967 MO_OBD2_Lampe 1;
BA_ "GenSigAutoGenDsp" SG_ 967 MO_OBD2_Lampe 1;
BA_ "GenSigSwitchedByIgnition" SG_ 967 MO_Heissleuchte 0;
BA_ "GenSigSendType" SG_ 967 MO_Heissleuchte 0;
BA_ "GenSigEnvVarType" SG_ 967 MO_Heissleuchte 0;
BA_ "GenSigAutoGenSnd" SG_ 967 MO_Heissleuchte 1;
BA_ "GenSigAutoGenDsp" SG_ 967 MO_Heissleuchte 1;
BA_ "GenSigSwitchedByIgnition" SG_ 967 MO_Partikel_Lampe 0;
BA_ "GenSigSendType" SG_ 967 MO_Partikel_Lampe 0;
BA_ "GenSigEnvVarType" SG_ 967 MO_Partikel_Lampe 0;
BA_ "GenSigAutoGenSnd" SG_ 967 MO_Partikel_Lampe 1;
BA_ "GenSigAutoGenDsp" SG_ 967 MO_Partikel_Lampe 1;
BA_ "GenSigSwitchedByIgnition" SG_ 967 MO_Winterfahrprog 0;
BA_ "GenSigSendType" SG_ 967 MO_Winterfahrprog 0;
BA_ "GenSigEnvVarType" SG_ 967 MO_Winterfahrprog 0;
BA_ "GenSigAutoGenSnd" SG_ 967 MO_Winterfahrprog 1;
BA_ "GenSigAutoGenDsp" SG_ 967 MO_Winterfahrprog 1;
BA_ "GenSigSwitchedByIgnition" SG_ 967 WIV_Oelstand_nicht_vorhanden 0;
BA_ "GenSigSendType" SG_ 967 WIV_Oelstand_nicht_vorhanden 0;
BA_ "GenSigEnvVarType" SG_ 967 WIV_Oelstand_nicht_vorhanden 0;
BA_ "GenSigAutoGenSnd" SG_ 967 WIV_Oelstand_nicht_vorhanden 1;
BA_ "GenSigAutoGenDsp" SG_ 967 WIV_Oelstand_nicht_vorhanden 1;
BA_ "GenSigSwitchedByIgnition" SG_ 967 WIV_nachfuellanzeige_ein 0;
BA_ "GenSigSendType" SG_ 967 WIV_nachfuellanzeige_ein 0;
BA_ "GenSigEnvVarType" SG_ 967 WIV_nachfuellanzeige_ein 0;
BA_ "GenSigAutoGenSnd" SG_ 967 WIV_nachfuellanzeige_ein 1;
BA_ "GenSigAutoGenDsp" SG_ 967 WIV_nachfuellanzeige_ein 1;
BA_ "GenSigSwitchedByIgnition" SG_ 967 WIV_Ueberfuell_deaktiv 0;
BA_ "GenSigSendType" SG_ 967 WIV_Ueberfuell_deaktiv 0;
BA_ "GenSigEnvVarType" SG_ 967 WIV_Ueberfuell_deaktiv 0;
BA_ "GenSigAutoGenSnd" SG_ 967 WIV_Ueberfuell_deaktiv 1;
BA_ "GenSigAutoGenDsp" SG_ 967 WIV_Ueberfuell_deaktiv 1;
BA_ "GenSigSwitchedByIgnition" SG_ 967 WIV_Unterfuell_Warn 0;
BA_ "GenSigSendType" SG_ 967 WIV_Unterfuell_Warn 0;
BA_ "GenSigEnvVarType" SG_ 967 WIV_Unterfuell_Warn 0;
BA_ "GenSigAutoGenSnd" SG_ 967 WIV_Unterfuell_Warn 1;
BA_ "GenSigAutoGenDsp" SG_ 967 WIV_Unterfuell_Warn 1;
BA_ "GenSigSwitchedByIgnition" SG_ 967 MO_Tankdeckel_Lampe 0;
BA_ "GenSigSendType" SG_ 967 MO_Tankdeckel_Lampe 0;
BA_ "GenSigEnvVarType" SG_ 967 MO_Tankdeckel_Lampe 0;
BA_ "GenSigAutoGenSnd" SG_ 967 MO_Tankdeckel_Lampe 1;
BA_ "GenSigAutoGenDsp" SG_ 967 MO_Tankdeckel_Lampe 1;
BA_ "GenSigSwitchedByIgnition" SG_ 967 MO_Text_Tankdeckelwarn 0;
BA_ "GenSigSendType" SG_ 967 MO_Text_Tankdeckelwarn 0;
BA_ "GenSigEnvVarType" SG_ 967 MO_Text_Tankdeckelwarn 0;
BA_ "GenSigAutoGenSnd" SG_ 967 MO_Text_Tankdeckelwarn 1;
BA_ "GenSigAutoGenDsp" SG_ 967 MO_Text_Tankdeckelwarn 1;
BA_ "GenSigSwitchedByIgnition" SG_ 967 WIV_Oeldr_Warn_Motor 0;
BA_ "GenSigSendType" SG_ 967 WIV_Oeldr_Warn_Motor 0;
BA_ "GenSigEnvVarType" SG_ 967 WIV_Oeldr_Warn_Motor 0;
BA_ "GenSigAutoGenSnd" SG_ 967 WIV_Oeldr_Warn_Motor 1;
BA_ "GenSigAutoGenDsp" SG_ 967 WIV_Oeldr_Warn_Motor 1;
BA_ "GenSigSwitchedByIgnition" SG_ 1601 Motor_Code_01_CRC 0;
BA_ "GenSigFuncType" SG_ 1601 Motor_Code_01_CRC 2;
BA_ "GenSigSendType" SG_ 1601 Motor_Code_01_CRC 0;
BA_ "GenSigEnvVarType" SG_ 1601 Motor_Code_01_CRC 0;
BA_ "GenSigAutoGenSnd" SG_ 1601 Motor_Code_01_CRC 1;
BA_ "GenSigAutoGenDsp" SG_ 1601 Motor_Code_01_CRC 1;
BA_ "GenSigSwitchedByIgnition" SG_ 1601 Motor_Code_01_BZ 0;
BA_ "GenSigFuncType" SG_ 1601 Motor_Code_01_BZ 1;
BA_ "GenSigSendType" SG_ 1601 Motor_Code_01_BZ 0;
BA_ "GenSigEnvVarType" SG_ 1601 Motor_Code_01_BZ 0;
BA_ "GenSigAutoGenSnd" SG_ 1601 Motor_Code_01_BZ 1;
BA_ "GenSigAutoGenDsp" SG_ 1601 Motor_Code_01_BZ 1;
BA_ "GenSigSwitchedByIgnition" SG_ 1601 MO_Faktor_Momente_02 0;
BA_ "GenSigSendType" SG_ 1601 MO_Faktor_Momente_02 0;
BA_ "GenSigEnvVarType" SG_ 1601 MO_Faktor_Momente_02 0;
BA_ "GenSigAutoGenSnd" SG_ 1601 MO_Faktor_Momente_02 1;
BA_ "GenSigAutoGenDsp" SG_ 1601 MO_Faktor_Momente_02 1;
BA_ "GenSigSwitchedByIgnition" SG_ 1601 MO_Hybridfahrzeug 0;
BA_ "GenSigFuncType" SG_ 1601 MO_Hybridfahrzeug 8;
BA_ "GenSigSendType" SG_ 1601 MO_Hybridfahrzeug 0;
BA_ "GenSigAutoGenSnd" SG_ 1601 MO_Hybridfahrzeug 1;
BA_ "GenSigAutoGenDsp" SG_ 1601 MO_Hybridfahrzeug 1;
BA_ "GenSigSwitchedByIgnition" SG_ 1601 MO_Code 0;
BA_ "GenSigSendType" SG_ 1601 MO_Code 0;
BA_ "GenSigEnvVarType" SG_ 1601 MO_Code 0;
BA_ "GenSigAutoGenSnd" SG_ 1601 MO_Code 1;
BA_ "GenSigAutoGenDsp" SG_ 1601 MO_Code 1;
BA_ "GenSigSwitchedByIgnition" SG_ 1601 MO_Getriebe_Code 0;
BA_ "GenSigSendType" SG_ 1601 MO_Getriebe_Code 0;
BA_ "GenSigEnvVarType" SG_ 1601 MO_Getriebe_Code 0;
BA_ "GenSigAutoGenSnd" SG_ 1601 MO_Getriebe_Code 1;
BA_ "GenSigAutoGenDsp" SG_ 1601 MO_Getriebe_Code 1;
BA_ "GenSigSwitchedByIgnition" SG_ 1601 MO_StartStopp_Codiert 0;
BA_ "GenSigFuncType" SG_ 1601 MO_StartStopp_Codiert 8;
BA_ "GenSigSendType" SG_ 1601 MO_StartStopp_Codiert 0;
BA_ "GenSigAutoGenSnd" SG_ 1601 MO_StartStopp_Codiert 1;
BA_ "GenSigAutoGenDsp" SG_ 1601 MO_StartStopp_Codiert 1;
BA_ "GenSigSwitchedByIgnition" SG_ 1601 MO_Anzahl_Zyl 0;
BA_ "GenSigSendType" SG_ 1601 MO_Anzahl_Zyl 0;
BA_ "GenSigEnvVarType" SG_ 1601 MO_Anzahl_Zyl 0;
BA_ "GenSigAutoGenSnd" SG_ 1601 MO_Anzahl_Zyl 1;
BA_ "GenSigAutoGenDsp" SG_ 1601 MO_Anzahl_Zyl 1;
BA_ "GenSigSwitchedByIgnition" SG_ 1601 MO_Kraftstoffart 0;
BA_ "GenSigSendType" SG_ 1601 MO_Kraftstoffart 0;
BA_ "GenSigEnvVarType" SG_ 1601 MO_Kraftstoffart 0;
BA_ "GenSigAutoGenSnd" SG_ 1601 MO_Kraftstoffart 1;
BA_ "GenSigAutoGenDsp" SG_ 1601 MO_Kraftstoffart 1;
BA_ "GenSigSwitchedByIgnition" SG_ 1601 MO_Hubraum 0;
BA_ "GenSigSendType" SG_ 1601 MO_Hubraum 0;
BA_ "GenSigEnvVarType" SG_ 1601 MO_Hubraum 1;
BA_ "GenSigAutoGenSnd" SG_ 1601 MO_Hubraum 1;
BA_ "GenSigAutoGenDsp" SG_ 1601 MO_Hubraum 1;
BA_ "GenSigSwitchedByIgnition" SG_ 1601 MO_Ansaugsystem 0;
BA_ "GenSigSendType" SG_ 1601 MO_Ansaugsystem 0;
BA_ "GenSigEnvVarType" SG_ 1601 MO_Ansaugsystem 0;
BA_ "GenSigAutoGenSnd" SG_ 1601 MO_Ansaugsystem 1;
BA_ "GenSigAutoGenDsp" SG_ 1601 MO_Ansaugsystem 1;
BA_ "GenSigSwitchedByIgnition" SG_ 1601 MO_Leistung 0;
BA_ "GenSigSendType" SG_ 1601 MO_Leistung 0;
BA_ "GenSigEnvVarType" SG_ 1601 MO_Leistung 0;
BA_ "GenSigAutoGenSnd" SG_ 1601 MO_Leistung 1;
BA_ "GenSigAutoGenDsp" SG_ 1601 MO_Leistung 1;
BA_ "GenSigSwitchedByIgnition" SG_ 1601 MO_Abgastyp_EOBD 0;
BA_ "GenSigFuncType" SG_ 1601 MO_Abgastyp_EOBD 8;
BA_ "GenSigSendType" SG_ 1601 MO_Abgastyp_EOBD 0;
BA_ "GenSigEnvVarType" SG_ 1601 MO_Abgastyp_EOBD 0;
BA_ "GenSigAutoGenSnd" SG_ 1601 MO_Abgastyp_EOBD 1;
BA_ "GenSigAutoGenDsp" SG_ 1601 MO_Abgastyp_EOBD 1;
BA_ "GenSigSwitchedByIgnition" SG_ 1601 MO_Abgastyp_OBD 0;
BA_ "GenSigFuncType" SG_ 1601 MO_Abgastyp_OBD 8;
BA_ "GenSigSendType" SG_ 1601 MO_Abgastyp_OBD 0;
BA_ "GenSigEnvVarType" SG_ 1601 MO_Abgastyp_OBD 0;
BA_ "GenSigAutoGenSnd" SG_ 1601 MO_Abgastyp_OBD 1;
BA_ "GenSigAutoGenDsp" SG_ 1601 MO_Abgastyp_OBD 1;
BA_ "GenSigSwitchedByIgnition" SG_ 1601 MO_DPF_verbaut 0;
BA_ "GenSigFuncType" SG_ 1601 MO_DPF_verbaut 8;
BA_ "GenSigSendType" SG_ 1601 MO_DPF_verbaut 0;
BA_ "GenSigEnvVarType" SG_ 1601 MO_DPF_verbaut 0;
BA_ "GenSigAutoGenSnd" SG_ 1601 MO_DPF_verbaut 1;
BA_ "GenSigAutoGenDsp" SG_ 1601 MO_DPF_verbaut 1;
BA_ "GenSigSwitchedByIgnition" SG_ 1601 TSK_Codierung 0;
BA_ "GenSigStartValue" SG_ 1601 TSK_Codierung 7;
BA_ "GenSigSendType" SG_ 1601 TSK_Codierung 0;
BA_ "GenSigEnvVarType" SG_ 1601 TSK_Codierung 0;
BA_ "GenSigAutoGenSnd" SG_ 1601 TSK_Codierung 1;
BA_ "GenSigAutoGenDsp" SG_ 1601 TSK_Codierung 1;
BA_ "GenSigSwitchedByIgnition" SG_ 1601 MO_Einspritzart 0;
BA_ "GenSigSendType" SG_ 1601 MO_Einspritzart 0;
BA_ "GenSigEnvVarType" SG_ 1601 MO_Einspritzart 0;
BA_ "GenSigAutoGenSnd" SG_ 1601 MO_Einspritzart 1;
BA_ "GenSigAutoGenDsp" SG_ 1601 MO_Einspritzart 1;
BA_ "GenSigSwitchedByIgnition" SG_ 157 Motor_Hybrid_01_CRC 0;
BA_ "GenSigFuncType" SG_ 157 Motor_Hybrid_01_CRC 2;
BA_ "GenSigSendType" SG_ 157 Motor_Hybrid_01_CRC 0;
BA_ "GenSigEnvVarType" SG_ 157 Motor_Hybrid_01_CRC 0;
BA_ "GenSigAutoGenSnd" SG_ 157 Motor_Hybrid_01_CRC 1;
BA_ "GenSigAutoGenDsp" SG_ 157 Motor_Hybrid_01_CRC 1;
BA_ "GenSigSwitchedByIgnition" SG_ 157 Motor_Hybrid_01_BZ 0;
BA_ "GenSigFuncType" SG_ 157 Motor_Hybrid_01_BZ 1;
BA_ "GenSigSendType" SG_ 157 Motor_Hybrid_01_BZ 0;
BA_ "GenSigEnvVarType" SG_ 157 Motor_Hybrid_01_BZ 0;
BA_ "GenSigAutoGenSnd" SG_ 157 Motor_Hybrid_01_BZ 1;
BA_ "GenSigAutoGenDsp" SG_ 157 Motor_Hybrid_01_BZ 1;
BA_ "Fehlerwert" SG_ 157 MO_HYB_IstStatusK0 3;
BA_ "GenSigSendType" SG_ 157 MO_HYB_IstStatusK0 0;
BA_ "GenSigAutoGenSnd" SG_ 157 MO_HYB_IstStatusK0 1;
BA_ "GenSigAutoGenDsp" SG_ 157 MO_HYB_IstStatusK0 1;
BA_ "Fehlerwert" SG_ 157 MO_HYB_max_ind_VM_Mom 1023;
BA_ "GenSigStartValue" SG_ 157 MO_HYB_max_ind_VM_Mom 1022;
BA_ "GenSigSendType" SG_ 157 MO_HYB_max_ind_VM_Mom 0;
BA_ "GenSigAutoGenSnd" SG_ 157 MO_HYB_max_ind_VM_Mom 1;
BA_ "GenSigAutoGenDsp" SG_ 157 MO_HYB_max_ind_VM_Mom 1;
BA_ "Fehlerwert" SG_ 157 MO_HYB_Zielzustand 7;
BA_ "GenSigSendType" SG_ 157 MO_HYB_Zielzustand 0;
BA_ "GenSigAutoGenSnd" SG_ 157 MO_HYB_Zielzustand 1;
BA_ "GenSigAutoGenDsp" SG_ 157 MO_HYB_Zielzustand 1;
BA_ "GenSigSendType" SG_ 157 MO_HYB_Startmodus 0;
BA_ "GenSigAutoGenSnd" SG_ 157 MO_HYB_Startmodus 1;
BA_ "GenSigAutoGenDsp" SG_ 157 MO_HYB_Startmodus 1;
BA_ "GenSigSendType" SG_ 157 MO_HYB_Startmodus_PQ3x 0;
BA_ "GenSigAutoGenSnd" SG_ 157 MO_HYB_Startmodus_PQ3x 1;
BA_ "GenSigAutoGenDsp" SG_ 157 MO_HYB_Startmodus_PQ3x 1;
BA_ "GenSigSendType" SG_ 157 MO_HYB_Stoppmodus 0;
BA_ "GenSigAutoGenSnd" SG_ 157 MO_HYB_Stoppmodus 1;
BA_ "GenSigAutoGenDsp" SG_ 157 MO_HYB_Stoppmodus 1;
BA_ "Fehlerwert" SG_ 157 MO_HYB_VM_Mom_oE 1023;
BA_ "GenSigSwitchedByIgnition" SG_ 157 MO_HYB_VM_Mom_oE 0;
BA_ "GenSigStartValue" SG_ 157 MO_HYB_VM_Mom_oE 100;
BA_ "GenSigSendType" SG_ 157 MO_HYB_VM_Mom_oE 0;
BA_ "GenSigAutoGenSnd" SG_ 157 MO_HYB_VM_Mom_oE 1;
BA_ "GenSigAutoGenDsp" SG_ 157 MO_HYB_VM_Mom_oE 1;
BA_ "GenSigSendType" SG_ 157 MO_HYB_VM_aktiv 0;
BA_ "GenSigAutoGenSnd" SG_ 157 MO_HYB_VM_aktiv 1;
BA_ "GenSigAutoGenDsp" SG_ 157 MO_HYB_VM_aktiv 1;
BA_ "GenSigSendType" SG_ 157 MO_HYB_Schaltverhinderung 0;
BA_ "GenSigAutoGenSnd" SG_ 157 MO_HYB_Schaltverhinderung 1;
BA_ "GenSigAutoGenDsp" SG_ 157 MO_HYB_Schaltverhinderung 1;
BA_ "GenSigSendType" SG_ 157 MO_HYB_Selektor_Momverlauf_EM 0;
BA_ "GenSigAutoGenSnd" SG_ 157 MO_HYB_Selektor_Momverlauf_EM 1;
BA_ "GenSigAutoGenDsp" SG_ 157 MO_HYB_Selektor_Momverlauf_EM 1;
BA_ "GenSigAutoGenSnd" SG_ 157 MO_HYB_Momverlauf_Rek 1;
BA_ "GenSigAutoGenDsp" SG_ 157 MO_HYB_Momverlauf_Rek 1;
BA_ "GenSigAutoGenSnd" SG_ 157 MO_HYB_KnickDZ_Rek 1;
BA_ "GenSigAutoGenDsp" SG_ 157 MO_HYB_KnickDZ_Rek 1;
BA_ "GenSigAutoGenSnd" SG_ 157 MO_HYB_Momverlauf_EM 1;
BA_ "GenSigAutoGenDsp" SG_ 157 MO_HYB_Momverlauf_EM 1;
BA_ "GenSigAutoGenSnd" SG_ 157 MO_HYB_KnickDZ_EM 1;
BA_ "GenSigAutoGenDsp" SG_ 157 MO_HYB_KnickDZ_EM 1;
BA_ "GenSigSwitchedByIgnition" SG_ 811 MO_HYB_E_Faktor 0;
BA_ "GenSigSendType" SG_ 811 MO_HYB_E_Faktor 0;
BA_ "GenSigAutoGenSnd" SG_ 811 MO_HYB_E_Faktor 1;
BA_ "GenSigAutoGenDsp" SG_ 811 MO_HYB_E_Faktor 1;
BA_ "Fehlerwert" SG_ 811 MO_HYB_Drehzahl_VM 65280;
BA_ "GenSigSwitchedByIgnition" SG_ 811 MO_HYB_Drehzahl_VM 0;
BA_ "GenSigSendType" SG_ 811 MO_HYB_Drehzahl_VM 0;
BA_ "GenSigAutoGenSnd" SG_ 811 MO_HYB_Drehzahl_VM 1;
BA_ "GenSigAutoGenDsp" SG_ 811 MO_HYB_Drehzahl_VM 1;
BA_ "GenSigSwitchedByIgnition" SG_ 811 MO_HYB_LowSpeedModus 0;
BA_ "GenSigSendType" SG_ 811 MO_HYB_LowSpeedModus 0;
BA_ "GenSigAutoGenSnd" SG_ 811 MO_HYB_LowSpeedModus 1;
BA_ "GenSigAutoGenDsp" SG_ 811 MO_HYB_LowSpeedModus 1;
BA_ "GenSigSwitchedByIgnition" SG_ 16 WFS_MSG1_RND 0;
BA_ "GenSigSendType" SG_ 16 WFS_MSG1_RND 1;
BA_ "GenSigEnvVarType" SG_ 16 WFS_MSG1_RND 0;
BA_ "GenSigAutoGenSnd" SG_ 16 WFS_MSG1_RND 1;
BA_ "GenSigAutoGenDsp" SG_ 16 WFS_MSG1_RND 1;
BA_ "GenSigSwitchedByIgnition" SG_ 16 WFS_MSG1_CRC 0;
BA_ "GenSigEnvVarType" SG_ 16 WFS_MSG1_CRC 0;
BA_ "GenSigAutoGenSnd" SG_ 16 WFS_MSG1_CRC 1;
BA_ "GenSigAutoGenDsp" SG_ 16 WFS_MSG1_CRC 1;
BA_ "GenSigSwitchedByIgnition" SG_ 20 WFS_MSG2_RND 0;
BA_ "GenSigSendType" SG_ 20 WFS_MSG2_RND 1;
BA_ "GenSigEnvVarType" SG_ 20 WFS_MSG2_RND 0;
BA_ "GenSigAutoGenSnd" SG_ 20 WFS_MSG2_RND 1;
BA_ "GenSigAutoGenDsp" SG_ 20 WFS_MSG2_RND 1;
BA_ "GenSigSwitchedByIgnition" SG_ 20 WFS_MSG2_CRC 0;
BA_ "GenSigEnvVarType" SG_ 20 WFS_MSG2_CRC 0;
BA_ "GenSigAutoGenSnd" SG_ 20 WFS_MSG2_CRC 1;
BA_ "GenSigAutoGenDsp" SG_ 20 WFS_MSG2_CRC 1;
BA_ "GenSigSwitchedByIgnition" SG_ 22 WFS_MSG3_RND 0;
BA_ "GenSigSendType" SG_ 22 WFS_MSG3_RND 1;
BA_ "GenSigEnvVarType" SG_ 22 WFS_MSG3_RND 0;
BA_ "GenSigAutoGenSnd" SG_ 22 WFS_MSG3_RND 1;
BA_ "GenSigAutoGenDsp" SG_ 22 WFS_MSG3_RND 1;
BA_ "GenSigSwitchedByIgnition" SG_ 22 WFS_MSG3_CRC 0;
BA_ "GenSigEnvVarType" SG_ 22 WFS_MSG3_CRC 0;
BA_ "GenSigAutoGenSnd" SG_ 22 WFS_MSG3_CRC 1;
BA_ "GenSigAutoGenDsp" SG_ 22 WFS_MSG3_CRC 1;
BA_ "GenSigSwitchedByIgnition" SG_ 24 WFS_MSG4_RND 0;
BA_ "GenSigSendType" SG_ 24 WFS_MSG4_RND 1;
BA_ "GenSigEnvVarType" SG_ 24 WFS_MSG4_RND 0;
BA_ "GenSigAutoGenSnd" SG_ 24 WFS_MSG4_RND 1;
BA_ "GenSigAutoGenDsp" SG_ 24 WFS_MSG4_RND 1;
BA_ "GenSigSwitchedByIgnition" SG_ 24 WFS_MSG4_CRC 0;
BA_ "GenSigEnvVarType" SG_ 24 WFS_MSG4_CRC 0;
BA_ "GenSigAutoGenSnd" SG_ 24 WFS_MSG4_CRC 1;
BA_ "GenSigAutoGenDsp" SG_ 24 WFS_MSG4_CRC 1;
BA_ "GenSigSwitchedByIgnition" SG_ 2600468501 NM_Airbag_01_SNI 0;
BA_ "GenSigStartValue" SG_ 2600468501 NM_Airbag_01_SNI 21;
BA_ "GenSigAutoGenSnd" SG_ 2600468501 NM_Airbag_01_SNI 1;
BA_ "GenSigAutoGenDsp" SG_ 2600468501 NM_Airbag_01_SNI 1;
BA_ "GenSigSwitchedByIgnition" SG_ 2600468501 NM_Airbag_01_NM_State 0;
BA_ "GenSigAutoGenSnd" SG_ 2600468501 NM_Airbag_01_NM_State 1;
BA_ "GenSigAutoGenDsp" SG_ 2600468501 NM_Airbag_01_NM_State 1;
BA_ "GenSigSwitchedByIgnition" SG_ 2600468501 NM_Airbag_01_Car_Wakeup 0;
BA_ "GenSigEnvVarType" SG_ 2600468501 NM_Airbag_01_Car_Wakeup 0;
BA_ "GenSigSwitchedByIgnition" SG_ 2600468501 NM_Airbag_01_Wakeup 0;
BA_ "NWM-WakeupAllowed" SG_ 2600468501 NM_Airbag_01_Wakeup 1;
BA_ "GenSigEnvVarType" SG_ 2600468501 NM_Airbag_01_Wakeup 0;
BA_ "GenSigSwitchedByIgnition" SG_ 2600468501 NM_Airbag_01_NM_aktiv_KL15 0;
BA_ "GenSigEnvVarType" SG_ 2600468501 NM_Airbag_01_NM_aktiv_KL15 0;
BA_ "GenSigSwitchedByIgnition" SG_ 2600468501 NM_Airbag_01_NM_aktiv_Diagnose 0;
BA_ "GenSigEnvVarType" SG_ 2600468501 NM_Airbag_01_NM_aktiv_Diagnose 0;
BA_ "GenSigSwitchedByIgnition" SG_ 2600468501 NM_Airbag_01_NM_aktiv_Tmin 0;
BA_ "GenSigEnvVarType" SG_ 2600468501 NM_Airbag_01_NM_aktiv_Tmin 0;
BA_ "GenSigSwitchedByIgnition" SG_ 2600468501 NM_Airbag_01_UDS_CC 0;
BA_ "GenSigEnvVarType" SG_ 2600468501 NM_Airbag_01_UDS_CC 0;
BA_ "GenSigSwitchedByIgnition" SG_ 2600468604 NM_EMotor_01_SNI 0;
BA_ "GenSigStartValue" SG_ 2600468604 NM_EMotor_01_SNI 124;
BA_ "GenSigAutoGenSnd" SG_ 2600468604 NM_EMotor_01_SNI 1;
BA_ "GenSigAutoGenDsp" SG_ 2600468604 NM_EMotor_01_SNI 1;
BA_ "GenSigSwitchedByIgnition" SG_ 2600468604 NM_EMotor_01_NM_State 0;
BA_ "GenSigAutoGenSnd" SG_ 2600468604 NM_EMotor_01_NM_State 1;
BA_ "GenSigAutoGenDsp" SG_ 2600468604 NM_EMotor_01_NM_State 1;
BA_ "GenSigSwitchedByIgnition" SG_ 2600468604 NM_EMotor_01_Car_Wakeup 0;
BA_ "GenSigEnvVarType" SG_ 2600468604 NM_EMotor_01_Car_Wakeup 0;
BA_ "GenSigSwitchedByIgnition" SG_ 2600468604 NM_EMotor_01_Wakeup 0;
BA_ "NWM-WakeupAllowed" SG_ 2600468604 NM_EMotor_01_Wakeup 1;
BA_ "GenSigEnvVarType" SG_ 2600468604 NM_EMotor_01_Wakeup 0;
BA_ "GenSigSwitchedByIgnition" SG_ 2600468604 NM_EMotor_01_NM_aktiv_KL15 0;
BA_ "GenSigEnvVarType" SG_ 2600468604 NM_EMotor_01_NM_aktiv_KL15 0;
BA_ "GenSigSwitchedByIgnition" SG_ 2600468604 NM_EMotor_01_NM_aktiv_Diagnose 0;
BA_ "GenSigEnvVarType" SG_ 2600468604 NM_EMotor_01_NM_aktiv_Diagnose 0;
BA_ "GenSigSwitchedByIgnition" SG_ 2600468604 NM_EMotor_01_NM_aktiv_Tmin 0;
BA_ "GenSigEnvVarType" SG_ 2600468604 NM_EMotor_01_NM_aktiv_Tmin 0;
BA_ "GenSigSwitchedByIgnition" SG_ 2600468604 NM_EMotor_01_NL_Daten_EEPROM 0;
BA_ "GenSigAutoGenSnd" SG_ 2600468604 NM_EMotor_01_NL_Daten_EEPROM 1;
BA_ "GenSigAutoGenDsp" SG_ 2600468604 NM_EMotor_01_NL_Daten_EEPROM 1;
BA_ "GenSigSwitchedByIgnition" SG_ 2600468604 NM_EMotor_01_UDS_CC 0;
BA_ "GenSigEnvVarType" SG_ 2600468604 NM_EMotor_01_UDS_CC 0;
BA_ "GenSigSwitchedByIgnition" SG_ 2600468496 NM_Gateway_SNI 0;
BA_ "GenSigStartValue" SG_ 2600468496 NM_Gateway_SNI 16;
BA_ "GenSigAutoGenSnd" SG_ 2600468496 NM_Gateway_SNI 1;
BA_ "GenSigAutoGenDsp" SG_ 2600468496 NM_Gateway_SNI 1;
BA_ "GenSigSwitchedByIgnition" SG_ 2600468496 NM_Gateway_NM_State 0;
BA_ "GenSigAutoGenSnd" SG_ 2600468496 NM_Gateway_NM_State 1;
BA_ "GenSigAutoGenDsp" SG_ 2600468496 NM_Gateway_NM_State 1;
BA_ "GenSigSwitchedByIgnition" SG_ 2600468496 NM_Gateway_Car_Wakeup 0;
BA_ "GenSigEnvVarType" SG_ 2600468496 NM_Gateway_Car_Wakeup 0;
BA_ "GenSigSwitchedByIgnition" SG_ 2600468496 NM_Gateway_Wakeup 0;
BA_ "NWM-WakeupAllowed" SG_ 2600468496 NM_Gateway_Wakeup 1;
BA_ "GenSigEnvVarType" SG_ 2600468496 NM_Gateway_Wakeup 0;
BA_ "GenSigSwitchedByIgnition" SG_ 2600468496 NM_Gateway_NM_aktiv_KL15 0;
BA_ "GenSigEnvVarType" SG_ 2600468496 NM_Gateway_NM_aktiv_KL15 0;
BA_ "GenSigSwitchedByIgnition" SG_ 2600468496 NM_Gateway_NM_aktiv_Diagnose 0;
BA_ "GenSigEnvVarType" SG_ 2600468496 NM_Gateway_NM_aktiv_Diagnose 0;
BA_ "GenSigSwitchedByIgnition" SG_ 2600468496 NM_Gateway_NM_aktiv_Tmin 0;
BA_ "GenSigEnvVarType" SG_ 2600468496 NM_Gateway_NM_aktiv_Tmin 0;
BA_ "GenSigSwitchedByIgnition" SG_ 2600468496 NM_Gateway_ACAN_Aktivitaet 0;
BA_ "GenSigEnvVarType" SG_ 2600468496 NM_Gateway_ACAN_Aktivitaet 0;
BA_ "GenSigSwitchedByIgnition" SG_ 2600468496 NM_Gateway_FCAN_Aktivitaet 0;
BA_ "GenSigEnvVarType" SG_ 2600468496 NM_Gateway_FCAN_Aktivitaet 0;
BA_ "GenSigSwitchedByIgnition" SG_ 2600468496 NM_Gateway_KCAN_Aktivitaet 0;
BA_ "GenSigEnvVarType" SG_ 2600468496 NM_Gateway_KCAN_Aktivitaet 0;
BA_ "GenSigSwitchedByIgnition" SG_ 2600468496 NM_Gateway_ICAN_Aktivitaet 0;
BA_ "GenSigEnvVarType" SG_ 2600468496 NM_Gateway_ICAN_Aktivitaet 0;
BA_ "GenSigSwitchedByIgnition" SG_ 2600468496 NM_Gateway_DiagCAN_Aktivitaet 0;
BA_ "GenSigEnvVarType" SG_ 2600468496 NM_Gateway_DiagCAN_Aktivitaet 0;
BA_ "GenSigSwitchedByIgnition" SG_ 2600468496 NM_Gateway_ECAN_Aktivitaet 0;
BA_ "GenSigEnvVarType" SG_ 2600468496 NM_Gateway_ECAN_Aktivitaet 0;
BA_ "GenSigSwitchedByIgnition" SG_ 2600468496 NM_Gateway_Energie_LIN_Aktivi000 0;
BA_ "GenSigEnvVarType" SG_ 2600468496 NM_Gateway_Energie_LIN_Aktivi000 0;
BA_ "GenSigSwitchedByIgnition" SG_ 2600468496 NM_Gateway_Bedien_LIN_Aktivitaet 0;
BA_ "GenSigEnvVarType" SG_ 2600468496 NM_Gateway_Bedien_LIN_Aktivitaet 0;
BA_ "GenSigSwitchedByIgnition" SG_ 2600468496 NM_Gateway_EM_Aktivitaet 0;
BA_ "GenSigEnvVarType" SG_ 2600468496 NM_Gateway_EM_Aktivitaet 0;
BA_ "GenSigSwitchedByIgnition" SG_ 2600468496 NM_Gateway_NL_EM 0;
BA_ "GenSigEnvVarType" SG_ 2600468496 NM_Gateway_NL_EM 0;
BA_ "GenSigSwitchedByIgnition" SG_ 2600468496 NM_Gateway_NL_Shutdown 0;
BA_ "GenSigEnvVarType" SG_ 2600468496 NM_Gateway_NL_Shutdown 0;
BA_ "GenSigSwitchedByIgnition" SG_ 2600468496 NM_Gateway_NL_Spg_Messung 0;
BA_ "GenSigEnvVarType" SG_ 2600468496 NM_Gateway_NL_Spg_Messung 0;
BA_ "GenSigSwitchedByIgnition" SG_ 2600468496 NM_Gateway_NL_Wakeup_Monitor 0;
BA_ "GenSigEnvVarType" SG_ 2600468496 NM_Gateway_NL_Wakeup_Monitor 0;
BA_ "GenSigSwitchedByIgnition" SG_ 2600468496 NM_Gateway_UDS_CC 0;
BA_ "GenSigEnvVarType" SG_ 2600468496 NM_Gateway_UDS_CC 0;
BA_ "GenSigSwitchedByIgnition" SG_ 2600468599 NM_Getriebe_01_SNI 0;
BA_ "GenSigStartValue" SG_ 2600468599 NM_Getriebe_01_SNI 119;
BA_ "GenSigAutoGenSnd" SG_ 2600468599 NM_Getriebe_01_SNI 1;
BA_ "GenSigAutoGenDsp" SG_ 2600468599 NM_Getriebe_01_SNI 1;
BA_ "GenSigSwitchedByIgnition" SG_ 2600468599 NM_Getriebe_01_NM_State 0;
BA_ "GenSigAutoGenSnd" SG_ 2600468599 NM_Getriebe_01_NM_State 1;
BA_ "GenSigAutoGenDsp" SG_ 2600468599 NM_Getriebe_01_NM_State 1;
BA_ "GenSigSwitchedByIgnition" SG_ 2600468599 NM_Getriebe_01_Car_Wakeup 0;
BA_ "GenSigEnvVarType" SG_ 2600468599 NM_Getriebe_01_Car_Wakeup 0;
BA_ "GenSigSwitchedByIgnition" SG_ 2600468599 NM_Getriebe_01_Wakeup 0;
BA_ "NWM-WakeupAllowed" SG_ 2600468599 NM_Getriebe_01_Wakeup 1;
BA_ "GenSigEnvVarType" SG_ 2600468599 NM_Getriebe_01_Wakeup 0;
BA_ "GenSigSwitchedByIgnition" SG_ 2600468599 NM_Getriebe_01_NM_aktiv_KL15 0;
BA_ "GenSigEnvVarType" SG_ 2600468599 NM_Getriebe_01_NM_aktiv_KL15 0;
BA_ "GenSigSwitchedByIgnition" SG_ 2600468599 NM_Getriebe_01_NM_aktiv_Diagnose 0;
BA_ "GenSigEnvVarType" SG_ 2600468599 NM_Getriebe_01_NM_aktiv_Diagnose 0;
BA_ "GenSigSwitchedByIgnition" SG_ 2600468599 NM_Getriebe_01_NM_aktiv_Tmin 0;
BA_ "GenSigEnvVarType" SG_ 2600468599 NM_Getriebe_01_NM_aktiv_Tmin 0;
BA_ "GenSigSwitchedByIgnition" SG_ 2600468599 NM_Getriebe_01_NM_aktiv_v_gr_0 0;
BA_ "GenSigSwitchedByIgnition" SG_ 2600468599 NM_Getriebe_01_NM_aktiv_Pos_Erk 0;
BA_ "GenSigSwitchedByIgnition" SG_ 2600468599 NM_Getriebe_01_NM_aktiv_Umg_Bed 0;
BA_ "GenSigSwitchedByIgnition" SG_ 2600468599 NM_Getriebe_01_NL_Daten_EEPROM 0;
BA_ "GenSigAutoGenSnd" SG_ 2600468599 NM_Getriebe_01_NL_Daten_EEPROM 1;
BA_ "GenSigAutoGenDsp" SG_ 2600468599 NM_Getriebe_01_NL_Daten_EEPROM 1;
BA_ "GenSigSwitchedByIgnition" SG_ 2600468599 NM_Getriebe_01_UDS_CC 0;
BA_ "GenSigEnvVarType" SG_ 2600468599 NM_Getriebe_01_UDS_CC 0;
BA_ "GenSigSwitchedByIgnition" SG_ 2600468603 NM_Hybrid_01_SNI 0;
BA_ "GenSigStartValue" SG_ 2600468603 NM_Hybrid_01_SNI 123;
BA_ "GenSigAutoGenSnd" SG_ 2600468603 NM_Hybrid_01_SNI 1;
BA_ "GenSigAutoGenDsp" SG_ 2600468603 NM_Hybrid_01_SNI 1;
BA_ "GenSigSwitchedByIgnition" SG_ 2600468603 NM_Hybrid_01_NM_State 0;
BA_ "GenSigAutoGenSnd" SG_ 2600468603 NM_Hybrid_01_NM_State 1;
BA_ "GenSigAutoGenDsp" SG_ 2600468603 NM_Hybrid_01_NM_State 1;
BA_ "GenSigSwitchedByIgnition" SG_ 2600468603 NM_Hybrid_01_Car_Wakeup 0;
BA_ "GenSigEnvVarType" SG_ 2600468603 NM_Hybrid_01_Car_Wakeup 0;
BA_ "GenSigSwitchedByIgnition" SG_ 2600468603 NM_Hybrid_01_Wakeup 0;
BA_ "NWM-WakeupAllowed" SG_ 2600468603 NM_Hybrid_01_Wakeup 1;
BA_ "GenSigEnvVarType" SG_ 2600468603 NM_Hybrid_01_Wakeup 0;
BA_ "GenSigSwitchedByIgnition" SG_ 2600468603 NM_Hybrid_01_NM_aktiv_KL15 0;
BA_ "GenSigEnvVarType" SG_ 2600468603 NM_Hybrid_01_NM_aktiv_KL15 0;
BA_ "GenSigSwitchedByIgnition" SG_ 2600468603 NM_Hybrid_01_NM_aktiv_Diagnose 0;
BA_ "GenSigEnvVarType" SG_ 2600468603 NM_Hybrid_01_NM_aktiv_Diagnose 0;
BA_ "GenSigSwitchedByIgnition" SG_ 2600468603 NM_Hybrid_01_NM_aktiv_Tmin 0;
BA_ "GenSigEnvVarType" SG_ 2600468603 NM_Hybrid_01_NM_aktiv_Tmin 0;
BA_ "GenSigSwitchedByIgnition" SG_ 2600468603 NM_Hybrid_01_NL_Daten_EEPROM 0;
BA_ "GenSigAutoGenSnd" SG_ 2600468603 NM_Hybrid_01_NL_Daten_EEPROM 1;
BA_ "GenSigAutoGenDsp" SG_ 2600468603 NM_Hybrid_01_NL_Daten_EEPROM 1;
BA_ "GenSigSwitchedByIgnition" SG_ 2600468603 NM_Hybrid_01_NL_Luefter 0;
BA_ "GenSigAutoGenSnd" SG_ 2600468603 NM_Hybrid_01_NL_Luefter 1;
BA_ "GenSigAutoGenDsp" SG_ 2600468603 NM_Hybrid_01_NL_Luefter 1;
BA_ "GenSigSwitchedByIgnition" SG_ 2600468603 NM_Hybrid_01_UDS_CC 0;
BA_ "GenSigEnvVarType" SG_ 2600468603 NM_Hybrid_01_UDS_CC 0;
BA_ "GenSigSwitchedByIgnition" SG_ 2600468598 NM_MO_01_SNI 0;
BA_ "GenSigStartValue" SG_ 2600468598 NM_MO_01_SNI 118;
BA_ "GenSigAutoGenSnd" SG_ 2600468598 NM_MO_01_SNI 1;
BA_ "GenSigAutoGenDsp" SG_ 2600468598 NM_MO_01_SNI 1;
BA_ "GenSigSwitchedByIgnition" SG_ 2600468598 NM_MO_01_NM_State 0;
BA_ "GenSigAutoGenSnd" SG_ 2600468598 NM_MO_01_NM_State 1;
BA_ "GenSigAutoGenDsp" SG_ 2600468598 NM_MO_01_NM_State 1;
BA_ "GenSigSwitchedByIgnition" SG_ 2600468598 NM_MO_01_Car_Wakeup 0;
BA_ "GenSigEnvVarType" SG_ 2600468598 NM_MO_01_Car_Wakeup 0;
BA_ "GenSigSwitchedByIgnition" SG_ 2600468598 NM_MO_01_Wakeup 0;
BA_ "NWM-WakeupAllowed" SG_ 2600468598 NM_MO_01_Wakeup 1;
BA_ "GenSigEnvVarType" SG_ 2600468598 NM_MO_01_Wakeup 0;
BA_ "GenSigSwitchedByIgnition" SG_ 2600468598 NM_MO_01_NM_aktiv_KL15 0;
BA_ "GenSigEnvVarType" SG_ 2600468598 NM_MO_01_NM_aktiv_KL15 0;
BA_ "GenSigSwitchedByIgnition" SG_ 2600468598 NM_MO_01_NM_aktiv_Diagnose 0;
BA_ "GenSigEnvVarType" SG_ 2600468598 NM_MO_01_NM_aktiv_Diagnose 0;
BA_ "GenSigSwitchedByIgnition" SG_ 2600468598 NM_MO_01_NM_aktiv_Tmin 0;
BA_ "GenSigEnvVarType" SG_ 2600468598 NM_MO_01_NM_aktiv_Tmin 0;
BA_ "GenSigSwitchedByIgnition" SG_ 2600468598 NM_MO_01_NM_aktiv_HV_Abschaltung 0;
BA_ "GenSigAutoGenSnd" SG_ 2600468598 NM_MO_01_NM_aktiv_HV_Abschaltung 1;
BA_ "GenSigAutoGenDsp" SG_ 2600468598 NM_MO_01_NM_aktiv_HV_Abschaltung 1;
BA_ "GenSigSwitchedByIgnition" SG_ 2600468598 NM_MO_01_NM_aktiv_EKP_Vorlauf 0;
BA_ "GenSigAutoGenSnd" SG_ 2600468598 NM_MO_01_NM_aktiv_EKP_Vorlauf 1;
BA_ "GenSigAutoGenDsp" SG_ 2600468598 NM_MO_01_NM_aktiv_EKP_Vorlauf 1;
BA_ "GenSigSwitchedByIgnition" SG_ 2600468598 NM_MO_01_NM_aktiv_STH_Betrieb 0;
BA_ "GenSigAutoGenSnd" SG_ 2600468598 NM_MO_01_NM_aktiv_STH_Betrieb 1;
BA_ "GenSigAutoGenDsp" SG_ 2600468598 NM_MO_01_NM_aktiv_STH_Betrieb 1;
BA_ "GenSigSwitchedByIgnition" SG_ 2600468598 NM_MO_01_NL_Kuehlerluefter 0;
BA_ "GenSigAutoGenSnd" SG_ 2600468598 NM_MO_01_NL_Kuehlerluefter 1;
BA_ "GenSigAutoGenDsp" SG_ 2600468598 NM_MO_01_NL_Kuehlerluefter 1;
BA_ "GenSigSwitchedByIgnition" SG_ 2600468598 NM_MO_01_NL_Diagnose 0;
BA_ "GenSigAutoGenSnd" SG_ 2600468598 NM_MO_01_NL_Diagnose 1;
BA_ "GenSigAutoGenDsp" SG_ 2600468598 NM_MO_01_NL_Diagnose 1;
BA_ "GenSigSwitchedByIgnition" SG_ 2600468598 NM_MO_01_NL_WFS 0;
BA_ "GenSigAutoGenSnd" SG_ 2600468598 NM_MO_01_NL_WFS 1;
BA_ "GenSigAutoGenDsp" SG_ 2600468598 NM_MO_01_NL_WFS 1;
BA_ "GenSigSwitchedByIgnition" SG_ 2600468598 NM_MO_01_NL_EEPROM 0;
BA_ "GenSigAutoGenSnd" SG_ 2600468598 NM_MO_01_NL_EEPROM 1;
BA_ "GenSigAutoGenDsp" SG_ 2600468598 NM_MO_01_NL_EEPROM 1;
BA_ "GenSigSwitchedByIgnition" SG_ 2600468598 NM_MO_01_NL_Sonstige 0;
BA_ "GenSigAutoGenSnd" SG_ 2600468598 NM_MO_01_NL_Sonstige 1;
BA_ "GenSigAutoGenDsp" SG_ 2600468598 NM_MO_01_NL_Sonstige 1;
BA_ "GenSigSwitchedByIgnition" SG_ 2600468598 NM_MO_01_UDS_CC 0;
BA_ "GenSigEnvVarType" SG_ 2600468598 NM_MO_01_UDS_CC 0;
BA_ "GenSigSwitchedByIgnition" SG_ 913 OBD_Calc_Load_Val 0;
BA_ "GenSigStartValue" SG_ 913 OBD_Calc_Load_Val 255;
BA_ "GenSigSendType" SG_ 913 OBD_Calc_Load_Val 0;
BA_ "GenSigEnvVarType" SG_ 913 OBD_Calc_Load_Val 1;
BA_ "GenSigAutoGenSnd" SG_ 913 OBD_Calc_Load_Val 1;
BA_ "GenSigAutoGenDsp" SG_ 913 OBD_Calc_Load_Val 1;
BA_ "GenSigSwitchedByIgnition" SG_ 913 OBD_Eng_Cool_Temp 0;
BA_ "GenSigStartValue" SG_ 913 OBD_Eng_Cool_Temp 255;
BA_ "GenSigSendType" SG_ 913 OBD_Eng_Cool_Temp 0;
BA_ "GenSigEnvVarType" SG_ 913 OBD_Eng_Cool_Temp 0;
BA_ "GenSigAutoGenSnd" SG_ 913 OBD_Eng_Cool_Temp 1;
BA_ "GenSigAutoGenDsp" SG_ 913 OBD_Eng_Cool_Temp 1;
BA_ "GenSigSwitchedByIgnition" SG_ 913 OBD_Abs_Throttle_Pos 0;
BA_ "GenSigStartValue" SG_ 913 OBD_Abs_Throttle_Pos 255;
BA_ "GenSigSendType" SG_ 913 OBD_Abs_Throttle_Pos 0;
BA_ "GenSigEnvVarType" SG_ 913 OBD_Abs_Throttle_Pos 1;
BA_ "GenSigAutoGenSnd" SG_ 913 OBD_Abs_Throttle_Pos 1;
BA_ "GenSigAutoGenDsp" SG_ 913 OBD_Abs_Throttle_Pos 1;
BA_ "GenSigSwitchedByIgnition" SG_ 913 OBD_Abs_Load_Val 0;
BA_ "GenSigStartValue" SG_ 913 OBD_Abs_Load_Val 65535;
BA_ "GenSigSendType" SG_ 913 OBD_Abs_Load_Val 0;
BA_ "GenSigEnvVarType" SG_ 913 OBD_Abs_Load_Val 1;
BA_ "GenSigAutoGenSnd" SG_ 913 OBD_Abs_Load_Val 1;
BA_ "GenSigAutoGenDsp" SG_ 913 OBD_Abs_Load_Val 1;
BA_ "GenSigSwitchedByIgnition" SG_ 913 OBD_Abs_Pedal_Pos 0;
BA_ "GenSigStartValue" SG_ 913 OBD_Abs_Pedal_Pos 255;
BA_ "GenSigSendType" SG_ 913 OBD_Abs_Pedal_Pos 0;
BA_ "GenSigEnvVarType" SG_ 913 OBD_Abs_Pedal_Pos 1;
BA_ "GenSigAutoGenSnd" SG_ 913 OBD_Abs_Pedal_Pos 1;
BA_ "GenSigAutoGenDsp" SG_ 913 OBD_Abs_Pedal_Pos 1;
BA_ "GenSigSwitchedByIgnition" SG_ 913 OBD_Kaltstart_Denominator 0;
BA_ "GenSigSendType" SG_ 913 OBD_Kaltstart_Denominator 0;
BA_ "GenSigSwitchedByIgnition" SG_ 913 OBD_Minimum_Trip 0;
BA_ "GenSigSendType" SG_ 913 OBD_Minimum_Trip 0;
BA_ "GenSigSwitchedByIgnition" SG_ 913 OBD_Driving_Cycle 0;
BA_ "GenSigSendType" SG_ 913 OBD_Driving_Cycle 0;
BA_ "GenSigEnvVarType" SG_ 913 OBD_Driving_Cycle 0;
BA_ "GenSigAutoGenSnd" SG_ 913 OBD_Driving_Cycle 1;
BA_ "GenSigAutoGenDsp" SG_ 913 OBD_Driving_Cycle 1;
BA_ "GenSigSwitchedByIgnition" SG_ 913 OBD_Warm_Up_Cycle 0;
BA_ "GenSigSendType" SG_ 913 OBD_Warm_Up_Cycle 0;
BA_ "GenSigEnvVarType" SG_ 913 OBD_Warm_Up_Cycle 0;
BA_ "GenSigAutoGenSnd" SG_ 913 OBD_Warm_Up_Cycle 1;
BA_ "GenSigAutoGenDsp" SG_ 913 OBD_Warm_Up_Cycle 1;
BA_ "GenSigSwitchedByIgnition" SG_ 913 OBD_Normed_Trip 0;
BA_ "GenSigSendType" SG_ 913 OBD_Normed_Trip 0;
BA_ "GenSigEnvVarType" SG_ 913 OBD_Normed_Trip 0;
BA_ "GenSigAutoGenSnd" SG_ 913 OBD_Normed_Trip 1;
BA_ "GenSigAutoGenDsp" SG_ 913 OBD_Normed_Trip 1;
BA_ "GenSigSwitchedByIgnition" SG_ 1630 OBD_TG_F_Status_1 0;
BA_ "GenSigSendType" SG_ 1630 OBD_TG_F_Status_1 0;
BA_ "GenSigEnvVarType" SG_ 1630 OBD_TG_F_Status_1 0;
BA_ "GenSigAutoGenSnd" SG_ 1630 OBD_TG_F_Status_1 1;
BA_ "GenSigAutoGenDsp" SG_ 1630 OBD_TG_F_Status_1 1;
BA_ "GenSigSwitchedByIgnition" SG_ 1630 OBD_TG_F_Status_2 0;
BA_ "GenSigSendType" SG_ 1630 OBD_TG_F_Status_2 0;
BA_ "GenSigEnvVarType" SG_ 1630 OBD_TG_F_Status_2 0;
BA_ "GenSigAutoGenSnd" SG_ 1630 OBD_TG_F_Status_2 1;
BA_ "GenSigAutoGenDsp" SG_ 1630 OBD_TG_F_Status_2 1;
BA_ "GenSigSwitchedByIgnition" SG_ 1630 OBD_TG_F_Status_3 0;
BA_ "GenSigSendType" SG_ 1630 OBD_TG_F_Status_3 0;
BA_ "GenSigEnvVarType" SG_ 1630 OBD_TG_F_Status_3 0;
BA_ "GenSigAutoGenSnd" SG_ 1630 OBD_TG_F_Status_3 1;
BA_ "GenSigAutoGenDsp" SG_ 1630 OBD_TG_F_Status_3 1;
BA_ "GenSigSwitchedByIgnition" SG_ 1630 OBD_TG_F_Status_4 0;
BA_ "GenSigSendType" SG_ 1630 OBD_TG_F_Status_4 0;
BA_ "GenSigEnvVarType" SG_ 1630 OBD_TG_F_Status_4 0;
BA_ "GenSigAutoGenSnd" SG_ 1630 OBD_TG_F_Status_4 1;
BA_ "GenSigAutoGenDsp" SG_ 1630 OBD_TG_F_Status_4 1;
BA_ "GenSigSwitchedByIgnition" SG_ 1630 OBD_TG_Sens_Rohwert_1 0;
BA_ "GenSigSendType" SG_ 1630 OBD_TG_Sens_Rohwert_1 0;
BA_ "GenSigEnvVarType" SG_ 1630 OBD_TG_Sens_Rohwert_1 1;
BA_ "GenSigAutoGenSnd" SG_ 1630 OBD_TG_Sens_Rohwert_1 1;
BA_ "GenSigAutoGenDsp" SG_ 1630 OBD_TG_Sens_Rohwert_1 1;
BA_ "GenSigSwitchedByIgnition" SG_ 1630 OBD_TG_Sens_Rohwert_2 0;
BA_ "GenSigSendType" SG_ 1630 OBD_TG_Sens_Rohwert_2 0;
BA_ "GenSigEnvVarType" SG_ 1630 OBD_TG_Sens_Rohwert_2 1;
BA_ "GenSigAutoGenSnd" SG_ 1630 OBD_TG_Sens_Rohwert_2 1;
BA_ "GenSigAutoGenDsp" SG_ 1630 OBD_TG_Sens_Rohwert_2 1;
BA_ "GenSigSwitchedByIgnition" SG_ 1630 OBD_TG_Sens_Rohwert_3 0;
BA_ "GenSigSendType" SG_ 1630 OBD_TG_Sens_Rohwert_3 0;
BA_ "GenSigEnvVarType" SG_ 1630 OBD_TG_Sens_Rohwert_3 1;
BA_ "GenSigAutoGenSnd" SG_ 1630 OBD_TG_Sens_Rohwert_3 1;
BA_ "GenSigAutoGenDsp" SG_ 1630 OBD_TG_Sens_Rohwert_3 1;
BA_ "GenSigSwitchedByIgnition" SG_ 1630 OBD_TG_Sens_Rohwert_4 0;
BA_ "GenSigSendType" SG_ 1630 OBD_TG_Sens_Rohwert_4 0;
BA_ "GenSigEnvVarType" SG_ 1630 OBD_TG_Sens_Rohwert_4 1;
BA_ "GenSigAutoGenSnd" SG_ 1630 OBD_TG_Sens_Rohwert_4 1;
BA_ "GenSigAutoGenDsp" SG_ 1630 OBD_TG_Sens_Rohwert_4 1;
BA_ "GenSigSwitchedByIgnition" SG_ 1437 RSF_Tastencode_1 0;
BA_ "GenSigSendType" SG_ 1437 RSF_Tastencode_1 6;
BA_ "GenSigSwitchedByIgnition" SG_ 1437 RSF_Tastencode_2 0;
BA_ "GenSigSendType" SG_ 1437 RSF_Tastencode_2 6;
BA_ "GenSigSwitchedByIgnition" SG_ 1437 RSF_Tastencode_Maske 0;
BA_ "GenSigSendType" SG_ 1437 RSF_Tastencode_Maske 6;
BA_ "GenSigSwitchedByIgnition" SG_ 2033 Request_Airbag_Deployment 0;
BA_ "GenSigEnvVarType" SG_ 2033 Request_Airbag_Deployment 0;
BA_ "GenSigSwitchedByIgnition" SG_ 2041 Response_Airbag_Deployment 0;
BA_ "GenSigEnvVarType" SG_ 2041 Response_Airbag_Deployment 0;
BA_ "GenSigSendType" SG_ 984 RGS_VL_Texte 0;
BA_ "GenSigAutoGenSnd" SG_ 984 RGS_VL_Texte 1;
BA_ "GenSigAutoGenDsp" SG_ 984 RGS_VL_Texte 1;
BA_ "GenSigSendType" SG_ 984 RGS_VL_Charisma_FahrPr 0;
BA_ "GenSigEnvVarType" SG_ 984 RGS_VL_Charisma_FahrPr 0;
BA_ "GenSigAutoGenSnd" SG_ 984 RGS_VL_Charisma_FahrPr 1;
BA_ "GenSigAutoGenDsp" SG_ 984 RGS_VL_Charisma_FahrPr 1;
BA_ "GenSigSendType" SG_ 984 RGS_VL_Charisma_Status 0;
BA_ "GenSigEnvVarType" SG_ 984 RGS_VL_Charisma_Status 0;
BA_ "GenSigAutoGenSnd" SG_ 984 RGS_VL_Charisma_Status 1;
BA_ "GenSigAutoGenDsp" SG_ 984 RGS_VL_Charisma_Status 1;
BA_ "GenSigSendType" SG_ 984 RGS_VL_aktiv 0;
BA_ "GenSigAutoGenSnd" SG_ 984 RGS_VL_aktiv 1;
BA_ "GenSigAutoGenDsp" SG_ 984 RGS_VL_aktiv 1;
BA_ "GenSigSendType" SG_ 984 RGS_VL_PC_Aktuator_Sitz 0;
BA_ "GenSigAutoGenSnd" SG_ 984 RGS_VL_PC_Aktuator_Sitz 1;
BA_ "GenSigAutoGenDsp" SG_ 984 RGS_VL_PC_Aktuator_Sitz 1;
BA_ "GenSigSendType" SG_ 984 RGS_VL_PC_Aktuator_Schiebedach 0;
BA_ "GenSigAutoGenSnd" SG_ 984 RGS_VL_PC_Aktuator_Schiebedach 1;
BA_ "GenSigAutoGenDsp" SG_ 984 RGS_VL_PC_Aktuator_Schiebedach 1;
BA_ "GenSigSendType" SG_ 984 RGS_VL_PC_Aktuator_Fenster 0;
BA_ "GenSigAutoGenSnd" SG_ 984 RGS_VL_PC_Aktuator_Fenster 1;
BA_ "GenSigAutoGenDsp" SG_ 984 RGS_VL_PC_Aktuator_Fenster 1;
BA_ "GenSigSendType" SG_ 984 RGS_VL_PC_Aktuator_Warnblinken 0;
BA_ "GenSigAutoGenSnd" SG_ 984 RGS_VL_PC_Aktuator_Warnblinken 1;
BA_ "GenSigAutoGenDsp" SG_ 984 RGS_VL_PC_Aktuator_Warnblinken 1;
BA_ "GenSigSendType" SG_ 984 RGS_VL_Precrash_Basis 0;
BA_ "GenSigAutoGenSnd" SG_ 984 RGS_VL_Precrash_Basis 1;
BA_ "GenSigAutoGenDsp" SG_ 984 RGS_VL_Precrash_Basis 1;
BA_ "GenSigSendType" SG_ 984 RGS_VL_Precrash_Front 0;
BA_ "GenSigAutoGenSnd" SG_ 984 RGS_VL_Precrash_Front 1;
BA_ "GenSigAutoGenDsp" SG_ 984 RGS_VL_Precrash_Front 1;
BA_ "GenSigSendType" SG_ 984 RGS_VL_Precrash_Rear 0;
BA_ "GenSigAutoGenSnd" SG_ 984 RGS_VL_Precrash_Rear 1;
BA_ "GenSigAutoGenDsp" SG_ 984 RGS_VL_Precrash_Rear 1;
BA_ "GenSigSendType" SG_ 1528 SAK_Charisma_FahrPr 0;
BA_ "GenSigAutoGenSnd" SG_ 1528 SAK_Charisma_FahrPr 1;
BA_ "GenSigAutoGenDsp" SG_ 1528 SAK_Charisma_FahrPr 1;
BA_ "GenSigSendType" SG_ 1528 SAK_Charisma_Status 0;
BA_ "GenSigAutoGenSnd" SG_ 1528 SAK_Charisma_Status 1;
BA_ "GenSigAutoGenDsp" SG_ 1528 SAK_Charisma_Status 1;
BA_ "GenSigSwitchedByIgnition" SG_ 1313 STH_Funk_ein 0;
BA_ "GenSigSendType" SG_ 1313 STH_Funk_ein 0;
BA_ "GenSigEnvVarType" SG_ 1313 STH_Funk_ein 0;
BA_ "GenSigAutoGenSnd" SG_ 1313 STH_Funk_ein 1;
BA_ "GenSigAutoGenDsp" SG_ 1313 STH_Funk_ein 1;
BA_ "GenSigSwitchedByIgnition" SG_ 1313 STH_Funk_aus 0;
BA_ "GenSigSendType" SG_ 1313 STH_Funk_aus 0;
BA_ "GenSigEnvVarType" SG_ 1313 STH_Funk_aus 0;
BA_ "GenSigAutoGenSnd" SG_ 1313 STH_Funk_aus 1;
BA_ "GenSigAutoGenDsp" SG_ 1313 STH_Funk_aus 1;
BA_ "GenSigSwitchedByIgnition" SG_ 1313 STH_Zusatzheizung 0;
BA_ "GenSigSendType" SG_ 1313 STH_Zusatzheizung 0;
BA_ "GenSigEnvVarType" SG_ 1313 STH_Zusatzheizung 0;
BA_ "GenSigAutoGenSnd" SG_ 1313 STH_Zusatzheizung 1;
BA_ "GenSigAutoGenDsp" SG_ 1313 STH_Zusatzheizung 1;
BA_ "GenSigSwitchedByIgnition" SG_ 1313 STH_LED 0;
BA_ "GenSigSendType" SG_ 1313 STH_LED 0;
BA_ "GenSigEnvVarType" SG_ 1313 STH_LED 0;
BA_ "GenSigAutoGenSnd" SG_ 1313 STH_LED 1;
BA_ "GenSigAutoGenDsp" SG_ 1313 STH_LED 1;
BA_ "GenSigSwitchedByIgnition" SG_ 1313 STH_Pumpe_ein 0;
BA_ "GenSigSendType" SG_ 1313 STH_Pumpe_ein 0;
BA_ "GenSigEnvVarType" SG_ 1313 STH_Pumpe_ein 0;
BA_ "GenSigAutoGenSnd" SG_ 1313 STH_Pumpe_ein 1;
BA_ "GenSigAutoGenDsp" SG_ 1313 STH_Pumpe_ein 1;
BA_ "GenSigSwitchedByIgnition" SG_ 1313 STH_Geblaese 0;
BA_ "GenSigSendType" SG_ 1313 STH_Geblaese 0;
BA_ "GenSigEnvVarType" SG_ 1313 STH_Geblaese 0;
BA_ "GenSigAutoGenSnd" SG_ 1313 STH_Geblaese 1;
BA_ "GenSigAutoGenDsp" SG_ 1313 STH_Geblaese 1;
BA_ "GenSigSwitchedByIgnition" SG_ 1313 STH_EKP_Anst 0;
BA_ "GenSigSendType" SG_ 1313 STH_EKP_Anst 0;
BA_ "GenSigEnvVarType" SG_ 1313 STH_EKP_Anst 0;
BA_ "GenSigAutoGenSnd" SG_ 1313 STH_EKP_Anst 1;
BA_ "GenSigAutoGenDsp" SG_ 1313 STH_EKP_Anst 1;
BA_ "GenSigSwitchedByIgnition" SG_ 1313 STH_Start_folgt 0;
BA_ "GenSigSendType" SG_ 1313 STH_Start_folgt 0;
BA_ "GenSigAutoGenSnd" SG_ 1313 STH_Start_folgt 1;
BA_ "GenSigAutoGenDsp" SG_ 1313 STH_Start_folgt 1;
BA_ "GenSigSwitchedByIgnition" SG_ 1313 STH_Ventiloeffnungszeit 0;
BA_ "GenSigSendType" SG_ 1313 STH_Ventiloeffnungszeit 0;
BA_ "GenSigEnvVarType" SG_ 1313 STH_Ventiloeffnungszeit 0;
BA_ "GenSigAutoGenSnd" SG_ 1313 STH_Ventiloeffnungszeit 1;
BA_ "GenSigAutoGenDsp" SG_ 1313 STH_Ventiloeffnungszeit 1;
BA_ "GenSigSwitchedByIgnition" SG_ 1313 STH_Ventil_Status 0;
BA_ "GenSigSendType" SG_ 1313 STH_Ventil_Status 0;
BA_ "GenSigEnvVarType" SG_ 1313 STH_Ventil_Status 0;
BA_ "GenSigAutoGenSnd" SG_ 1313 STH_Ventil_Status 1;
BA_ "GenSigAutoGenDsp" SG_ 1313 STH_Ventil_Status 1;
BA_ "GenSigSwitchedByIgnition" SG_ 1313 STH_Waermeeintrag 0;
BA_ "GenSigSendType" SG_ 1313 STH_Waermeeintrag 0;
BA_ "GenSigEnvVarType" SG_ 1313 STH_Waermeeintrag 0;
BA_ "GenSigAutoGenSnd" SG_ 1313 STH_Waermeeintrag 1;
BA_ "GenSigAutoGenDsp" SG_ 1313 STH_Waermeeintrag 1;
BA_ "GenSigSwitchedByIgnition" SG_ 1313 STH_KVS 0;
BA_ "GenSigSendType" SG_ 1313 STH_KVS 0;
BA_ "GenSigEnvVarType" SG_ 1313 STH_KVS 0;
BA_ "GenSigAutoGenSnd" SG_ 1313 STH_KVS 1;
BA_ "GenSigAutoGenDsp" SG_ 1313 STH_KVS 1;
BA_ "GenSigSwitchedByIgnition" SG_ 1313 STH_Fehlerstatus 0;
BA_ "GenSigSendType" SG_ 1313 STH_Fehlerstatus 0;
BA_ "GenSigEnvVarType" SG_ 1313 STH_Fehlerstatus 0;
BA_ "GenSigAutoGenSnd" SG_ 1313 STH_Fehlerstatus 1;
BA_ "GenSigAutoGenDsp" SG_ 1313 STH_Fehlerstatus 1;
BA_ "GenSigSwitchedByIgnition" SG_ 1313 STH_Heizleistung 0;
BA_ "GenSigSendType" SG_ 1313 STH_Heizleistung 0;
BA_ "GenSigEnvVarType" SG_ 1313 STH_Heizleistung 0;
BA_ "GenSigAutoGenSnd" SG_ 1313 STH_Heizleistung 1;
BA_ "GenSigAutoGenDsp" SG_ 1313 STH_Heizleistung 1;
BA_ "Fehlerwert" SG_ 1313 STH_Wassertemp 255;
BA_ "GenSigSwitchedByIgnition" SG_ 1313 STH_Wassertemp 0;
BA_ "GenSigStartValue" SG_ 1313 STH_Wassertemp 254;
BA_ "GenSigSendType" SG_ 1313 STH_Wassertemp 0;
BA_ "GenSigEnvVarType" SG_ 1313 STH_Wassertemp 1;
BA_ "GenSigAutoGenSnd" SG_ 1313 STH_Wassertemp 1;
BA_ "GenSigAutoGenDsp" SG_ 1313 STH_Wassertemp 1;
BA_ "GenSigSwitchedByIgnition" SG_ 1313 STH_Motorvorwaermung 0;
BA_ "GenSigSendType" SG_ 1313 STH_Motorvorwaermung 0;
BA_ "GenSigEnvVarType" SG_ 1313 STH_Motorvorwaermung 0;
BA_ "GenSigAutoGenSnd" SG_ 1313 STH_Motorvorwaermung 1;
BA_ "GenSigAutoGenDsp" SG_ 1313 STH_Motorvorwaermung 1;
BA_ "GenSigSwitchedByIgnition" SG_ 1313 STH_Servicemode 0;
BA_ "GenSigSendType" SG_ 1313 STH_Servicemode 0;
BA_ "GenSigEnvVarType" SG_ 1313 STH_Servicemode 0;
BA_ "GenSigAutoGenSnd" SG_ 1313 STH_Servicemode 1;
BA_ "GenSigAutoGenDsp" SG_ 1313 STH_Servicemode 1;
BA_ "GenSigSwitchedByIgnition" SG_ 1313 STH_war_aktiv 0;
BA_ "GenSigSendType" SG_ 1313 STH_war_aktiv 0;
BA_ "GenSigEnvVarType" SG_ 1313 STH_war_aktiv 0;
BA_ "GenSigAutoGenSnd" SG_ 1313 STH_war_aktiv 1;
BA_ "GenSigAutoGenDsp" SG_ 1313 STH_war_aktiv 1;
BA_ "GenSigSwitchedByIgnition" SG_ 1313 STH_KVS_Ueberlauf 0;
BA_ "GenSigSendType" SG_ 1313 STH_KVS_Ueberlauf 0;
BA_ "GenSigEnvVarType" SG_ 1313 STH_KVS_Ueberlauf 0;
BA_ "GenSigAutoGenSnd" SG_ 1313 STH_KVS_Ueberlauf 1;
BA_ "GenSigAutoGenDsp" SG_ 1313 STH_KVS_Ueberlauf 1;
BA_ "GenSigSwitchedByIgnition" SG_ 1313 STH_KD_Fehler 0;
BA_ "GenSigSendType" SG_ 1313 STH_KD_Fehler 0;
BA_ "GenSigEnvVarType" SG_ 1313 STH_KD_Fehler 0;
BA_ "GenSigAutoGenSnd" SG_ 1313 STH_KD_Fehler 1;
BA_ "GenSigAutoGenDsp" SG_ 1313 STH_KD_Fehler 1;
BA_ "GenSigSwitchedByIgnition" SG_ 1172 STS_01_CRC 0;
BA_ "GenSigFuncType" SG_ 1172 STS_01_CRC 2;
BA_ "GenSigSendType" SG_ 1172 STS_01_CRC 0;
BA_ "GenSigEnvVarType" SG_ 1172 STS_01_CRC 0;
BA_ "GenSigAutoGenSnd" SG_ 1172 STS_01_CRC 1;
BA_ "GenSigAutoGenDsp" SG_ 1172 STS_01_CRC 1;
BA_ "GenSigSwitchedByIgnition" SG_ 1172 STS_01_BZ 0;
BA_ "GenSigFuncType" SG_ 1172 STS_01_BZ 1;
BA_ "GenSigSendType" SG_ 1172 STS_01_BZ 0;
BA_ "GenSigEnvVarType" SG_ 1172 STS_01_BZ 0;
BA_ "GenSigAutoGenSnd" SG_ 1172 STS_01_BZ 1;
BA_ "GenSigAutoGenDsp" SG_ 1172 STS_01_BZ 1;
BA_ "GenSigSwitchedByIgnition" SG_ 1172 STS_Car_not_under_theft 0;
BA_ "GenSigStartValue" SG_ 1172 STS_Car_not_under_theft 1;
BA_ "GenSigSendType" SG_ 1172 STS_Car_not_under_theft 0;
BA_ "GenSigAutoGenSnd" SG_ 1172 STS_Car_not_under_theft 1;
BA_ "GenSigAutoGenDsp" SG_ 1172 STS_Car_not_under_theft 1;
BA_ "GenSigSwitchedByIgnition" SG_ 1172 STS_Car_under_theft 0;
BA_ "GenSigSendType" SG_ 1172 STS_Car_under_theft 0;
BA_ "GenSigAutoGenSnd" SG_ 1172 STS_Car_under_theft 1;
BA_ "GenSigAutoGenDsp" SG_ 1172 STS_Car_under_theft 1;
BA_ "GenSigSwitchedByIgnition" SG_ 1172 STS_Anlassersperre 0;
BA_ "GenSigSendType" SG_ 1172 STS_Anlassersperre 0;
BA_ "GenSigEnvVarType" SG_ 1172 STS_Anlassersperre 0;
BA_ "GenSigAutoGenSnd" SG_ 1172 STS_Anlassersperre 1;
BA_ "GenSigAutoGenDsp" SG_ 1172 STS_Anlassersperre 1;
BA_ "GenSigSwitchedByIgnition" SG_ 1172 STS_Typencodierung 0;
BA_ "GenSigSendType" SG_ 1172 STS_Typencodierung 0;
BA_ "GenSigEnvVarType" SG_ 1172 STS_Typencodierung 0;
BA_ "GenSigAutoGenSnd" SG_ 1172 STS_Typencodierung 1;
BA_ "GenSigAutoGenDsp" SG_ 1172 STS_Typencodierung 1;
BA_ "GenSigSwitchedByIgnition" SG_ 1172 STS_LIN_aktiv 0;
BA_ "GenSigSendType" SG_ 1172 STS_LIN_aktiv 0;
BA_ "GenSigAutoGenSnd" SG_ 1172 STS_LIN_aktiv 1;
BA_ "GenSigAutoGenDsp" SG_ 1172 STS_LIN_aktiv 1;
BA_ "GenSigSwitchedByIgnition" SG_ 1172 STS_Standlicht 0;
BA_ "GenSigSendType" SG_ 1172 STS_Standlicht 3;
BA_ "GenSigEnvVarType" SG_ 1172 STS_Standlicht 0;
BA_ "GenSigAutoGenSnd" SG_ 1172 STS_Standlicht 1;
BA_ "GenSigAutoGenDsp" SG_ 1172 STS_Standlicht 1;
BA_ "GenSigSwitchedByIgnition" SG_ 1172 STS_Fahrlicht 0;
BA_ "GenSigSendType" SG_ 1172 STS_Fahrlicht 3;
BA_ "GenSigEnvVarType" SG_ 1172 STS_Fahrlicht 0;
BA_ "GenSigAutoGenSnd" SG_ 1172 STS_Fahrlicht 1;
BA_ "GenSigAutoGenDsp" SG_ 1172 STS_Fahrlicht 1;
BA_ "GenSigSwitchedByIgnition" SG_ 1172 STS_Alarm_still 0;
BA_ "GenSigSendType" SG_ 1172 STS_Alarm_still 0;
BA_ "GenSigAutoGenSnd" SG_ 1172 STS_Alarm_still 1;
BA_ "GenSigAutoGenDsp" SG_ 1172 STS_Alarm_still 1;
BA_ "Fehlerwert" SG_ 1172 STS_Texte 15;
BA_ "GenSigSwitchedByIgnition" SG_ 1172 STS_Texte 0;
BA_ "GenSigStartValue" SG_ 1172 STS_Texte 14;
BA_ "GenSigSendType" SG_ 1172 STS_Texte 0;
BA_ "GenSigSwitchedByIgnition" SG_ 1172 STS_Laderelais 0;
BA_ "GenSigSendType" SG_ 1172 STS_Laderelais 3;
BA_ "GenSigAutoGenSnd" SG_ 1172 STS_Laderelais 1;
BA_ "GenSigAutoGenDsp" SG_ 1172 STS_Laderelais 1;
BA_ "GenSigSwitchedByIgnition" SG_ 1172 STS_Summer 0;
BA_ "GenSigSendType" SG_ 1172 STS_Summer 3;
BA_ "GenSigEnvVarType" SG_ 1172 STS_Summer 0;
BA_ "GenSigAutoGenSnd" SG_ 1172 STS_Summer 1;
BA_ "GenSigAutoGenDsp" SG_ 1172 STS_Summer 1;
BA_ "GenSigSwitchedByIgnition" SG_ 1172 STS_Alarm_Blinker 0;
BA_ "GenSigSendType" SG_ 1172 STS_Alarm_Blinker 3;
BA_ "GenSigEnvVarType" SG_ 1172 STS_Alarm_Blinker 0;
BA_ "GenSigAutoGenSnd" SG_ 1172 STS_Alarm_Blinker 1;
BA_ "GenSigAutoGenDsp" SG_ 1172 STS_Alarm_Blinker 1;
BA_ "GenSigSwitchedByIgnition" SG_ 1172 STS_Notstart 0;
BA_ "GenSigSendType" SG_ 1172 STS_Notstart 3;
BA_ "GenSigAutoGenSnd" SG_ 1172 STS_Notstart 1;
BA_ "GenSigAutoGenDsp" SG_ 1172 STS_Notstart 1;
BA_ "GenSigSwitchedByIgnition" SG_ 1172 STS_Signalhorn 0;
BA_ "GenSigSendType" SG_ 1172 STS_Signalhorn 3;
BA_ "GenSigEnvVarType" SG_ 1172 STS_Signalhorn 0;
BA_ "GenSigAutoGenSnd" SG_ 1172 STS_Signalhorn 1;
BA_ "GenSigAutoGenDsp" SG_ 1172 STS_Signalhorn 1;
BA_ "GenSigSwitchedByIgnition" SG_ 1172 STS_Leerlaufschaltung 0;
BA_ "GenSigSendType" SG_ 1172 STS_Leerlaufschaltung 0;
BA_ "GenSigAutoGenSnd" SG_ 1172 STS_Leerlaufschaltung 1;
BA_ "GenSigAutoGenDsp" SG_ 1172 STS_Leerlaufschaltung 1;
BA_ "GenSigSwitchedByIgnition" SG_ 1413 SI_Sammel_SG_Fehler 0;
BA_ "GenSigStartValue" SG_ 1413 SI_Sammel_SG_Fehler 63;
BA_ "GenSigSendType" SG_ 1413 SI_Sammel_SG_Fehler 0;
BA_ "GenSigEnvVarType" SG_ 1413 SI_Sammel_SG_Fehler 0;
BA_ "GenSigAutoGenSnd" SG_ 1413 SI_Sammel_SG_Fehler 1;
BA_ "GenSigAutoGenDsp" SG_ 1413 SI_Sammel_SG_Fehler 1;
BA_ "Fehlerwert" SG_ 1413 SI_Rollenmode 3;
BA_ "GenSigSwitchedByIgnition" SG_ 1413 SI_Rollenmode 0;
BA_ "GenSigSendType" SG_ 1413 SI_Rollenmode 3;
BA_ "GenSigAutoGenSnd" SG_ 1413 SI_Rollenmode 1;
BA_ "GenSigAutoGenDsp" SG_ 1413 SI_Rollenmode 1;
BA_ "GenSigSwitchedByIgnition" SG_ 1413 SI_QRS_Mode 0;
BA_ "GenSigSendType" SG_ 1413 SI_QRS_Mode 3;
BA_ "GenSigEnvVarType" SG_ 1413 SI_QRS_Mode 0;
BA_ "GenSigAutoGenSnd" SG_ 1413 SI_QRS_Mode 1;
BA_ "GenSigAutoGenDsp" SG_ 1413 SI_QRS_Mode 1;
BA_ "GenSigSwitchedByIgnition" SG_ 1413 SI_T_Mode 0;
BA_ "GenSigSendType" SG_ 1413 SI_T_Mode 3;
BA_ "GenSigAutoGenSnd" SG_ 1413 SI_T_Mode 1;
BA_ "GenSigAutoGenDsp" SG_ 1413 SI_T_Mode 1;
BA_ "GenSigSwitchedByIgnition" SG_ 1413 SI_NWDF 0;
BA_ "GenSigSendType" SG_ 1413 SI_NWDF 3;
BA_ "GenSigAutoGenSnd" SG_ 1413 SI_NWDF 1;
BA_ "GenSigAutoGenDsp" SG_ 1413 SI_NWDF 1;
BA_ "GenSigSwitchedByIgnition" SG_ 1413 SI_NWDF_gueltig 0;
BA_ "GenSigSendType" SG_ 1413 SI_NWDF_gueltig 3;
BA_ "GenSigAutoGenSnd" SG_ 1413 SI_NWDF_gueltig 1;
BA_ "GenSigAutoGenDsp" SG_ 1413 SI_NWDF_gueltig 1;
BA_ "GenSigSwitchedByIgnition" SG_ 1413 SI_Sammelfehler 0;
BA_ "GenSigSendType" SG_ 1413 SI_Sammelfehler 3;
BA_ "GenSigAutoGenSnd" SG_ 1413 SI_Sammelfehler 1;
BA_ "GenSigAutoGenDsp" SG_ 1413 SI_Sammelfehler 1;
BA_ "GenSigSendType" SG_ 1413 GW_KD_Fehler 3;
BA_ "GenSigEnvVarType" SG_ 1413 GW_KD_Fehler 0;
BA_ "GenSigAutoGenSnd" SG_ 1413 GW_KD_Fehler 1;
BA_ "GenSigAutoGenDsp" SG_ 1413 GW_KD_Fehler 1;
BA_ "GenSigSwitchedByIgnition" SG_ 1413 SI_BUS_01 0;
BA_ "GenSigStartValue" SG_ 1413 SI_BUS_01 1;
BA_ "GenSigSendType" SG_ 1413 SI_BUS_01 3;
BA_ "GenSigSwitchedByIgnition" SG_ 1413 SI_BUS_02 0;
BA_ "GenSigStartValue" SG_ 1413 SI_BUS_02 1;
BA_ "GenSigSendType" SG_ 1413 SI_BUS_02 3;
BA_ "GenSigSwitchedByIgnition" SG_ 1413 SI_BUS_03 0;
BA_ "GenSigStartValue" SG_ 1413 SI_BUS_03 1;
BA_ "GenSigSendType" SG_ 1413 SI_BUS_03 3;
BA_ "GenSigSwitchedByIgnition" SG_ 1413 SI_BUS_04 0;
BA_ "GenSigStartValue" SG_ 1413 SI_BUS_04 1;
BA_ "GenSigSendType" SG_ 1413 SI_BUS_04 3;
BA_ "GenSigSwitchedByIgnition" SG_ 1413 SI_BUS_05 0;
BA_ "GenSigStartValue" SG_ 1413 SI_BUS_05 1;
BA_ "GenSigSendType" SG_ 1413 SI_BUS_05 3;
BA_ "GenSigSwitchedByIgnition" SG_ 1413 SI_BUS_06 0;
BA_ "GenSigStartValue" SG_ 1413 SI_BUS_06 1;
BA_ "GenSigSendType" SG_ 1413 SI_BUS_06 3;
BA_ "GenSigSwitchedByIgnition" SG_ 1413 SI_BUS_07 0;
BA_ "GenSigStartValue" SG_ 1413 SI_BUS_07 1;
BA_ "GenSigSendType" SG_ 1413 SI_BUS_07 3;
BA_ "GenSigSwitchedByIgnition" SG_ 1413 SI_BUS_08 0;
BA_ "GenSigStartValue" SG_ 1413 SI_BUS_08 1;
BA_ "GenSigSendType" SG_ 1413 SI_BUS_08 3;
BA_ "GenSigSwitchedByIgnition" SG_ 1413 SI_BUS_09 0;
BA_ "GenSigStartValue" SG_ 1413 SI_BUS_09 1;
BA_ "GenSigSendType" SG_ 1413 SI_BUS_09 3;
BA_ "GenSigSwitchedByIgnition" SG_ 1413 SI_BUS_10 0;
BA_ "GenSigStartValue" SG_ 1413 SI_BUS_10 1;
BA_ "GenSigSendType" SG_ 1413 SI_BUS_10 3;
BA_ "GenSigSwitchedByIgnition" SG_ 1413 SI_BUS_11 0;
BA_ "GenSigStartValue" SG_ 1413 SI_BUS_11 1;
BA_ "GenSigSendType" SG_ 1413 SI_BUS_11 3;
BA_ "GenSigSwitchedByIgnition" SG_ 1413 SI_BUS_12 0;
BA_ "GenSigStartValue" SG_ 1413 SI_BUS_12 1;
BA_ "GenSigSendType" SG_ 1413 SI_BUS_12 3;
BA_ "GenSigSwitchedByIgnition" SG_ 1413 SI_BUS_13 0;
BA_ "GenSigStartValue" SG_ 1413 SI_BUS_13 1;
BA_ "GenSigSendType" SG_ 1413 SI_BUS_13 3;
BA_ "GenSigSwitchedByIgnition" SG_ 1413 SI_BUS_14 0;
BA_ "GenSigStartValue" SG_ 1413 SI_BUS_14 1;
BA_ "GenSigSendType" SG_ 1413 SI_BUS_14 3;
BA_ "GenSigSwitchedByIgnition" SG_ 1413 SI_BUS_15 0;
BA_ "GenSigStartValue" SG_ 1413 SI_BUS_15 1;
BA_ "GenSigSendType" SG_ 1413 SI_BUS_15 3;
BA_ "GenSigSwitchedByIgnition" SG_ 288 TSK_06_CRC 0;
BA_ "GenSigFuncType" SG_ 288 TSK_06_CRC 2;
BA_ "GenSigSendType" SG_ 288 TSK_06_CRC 0;
BA_ "GenSigEnvVarType" SG_ 288 TSK_06_CRC 0;
BA_ "GenSigAutoGenSnd" SG_ 288 TSK_06_CRC 1;
BA_ "GenSigAutoGenDsp" SG_ 288 TSK_06_CRC 1;
BA_ "GenSigSwitchedByIgnition" SG_ 288 TSK_06_BZ 0;
BA_ "GenSigFuncType" SG_ 288 TSK_06_BZ 1;
BA_ "GenSigSendType" SG_ 288 TSK_06_BZ 0;
BA_ "GenSigEnvVarType" SG_ 288 TSK_06_BZ 0;
BA_ "GenSigAutoGenSnd" SG_ 288 TSK_06_BZ 1;
BA_ "GenSigAutoGenDsp" SG_ 288 TSK_06_BZ 1;
BA_ "GenSigSwitchedByIgnition" SG_ 288 TSK_Radbremsmom 0;
BA_ "GenSigSendType" SG_ 288 TSK_Radbremsmom 0;
BA_ "GenSigEnvVarType" SG_ 288 TSK_Radbremsmom 0;
BA_ "GenSigAutoGenSnd" SG_ 288 TSK_Radbremsmom 1;
BA_ "GenSigAutoGenDsp" SG_ 288 TSK_Radbremsmom 1;
BA_ "GenSigSwitchedByIgnition" SG_ 288 TSK_Status 0;
BA_ "GenSigStartValue" SG_ 288 TSK_Status 1;
BA_ "GenSigSendType" SG_ 288 TSK_Status 0;
BA_ "GenSigEnvVarType" SG_ 288 TSK_Status 0;
BA_ "GenSigAutoGenSnd" SG_ 288 TSK_Status 1;
BA_ "GenSigAutoGenDsp" SG_ 288 TSK_Status 1;
BA_ "GenSigSwitchedByIgnition" SG_ 288 TSK_v_Begrenzung_aktiv 0;
BA_ "GenSigSendType" SG_ 288 TSK_v_Begrenzung_aktiv 0;
BA_ "GenSigEnvVarType" SG_ 288 TSK_v_Begrenzung_aktiv 0;
BA_ "GenSigAutoGenSnd" SG_ 288 TSK_v_Begrenzung_aktiv 1;
BA_ "GenSigAutoGenDsp" SG_ 288 TSK_v_Begrenzung_aktiv 1;
BA_ "GenSigSwitchedByIgnition" SG_ 288 TSK_Standby_Anf_ESP 0;
BA_ "GenSigSendType" SG_ 288 TSK_Standby_Anf_ESP 0;
BA_ "GenSigEnvVarType" SG_ 288 TSK_Standby_Anf_ESP 0;
BA_ "GenSigAutoGenSnd" SG_ 288 TSK_Standby_Anf_ESP 1;
BA_ "GenSigAutoGenDsp" SG_ 288 TSK_Standby_Anf_ESP 1;
BA_ "GenSigSwitchedByIgnition" SG_ 288 TSK_Freig_Verzoeg_Anf 0;
BA_ "GenSigSendType" SG_ 288 TSK_Freig_Verzoeg_Anf 0;
BA_ "GenSigEnvVarType" SG_ 288 TSK_Freig_Verzoeg_Anf 0;
BA_ "GenSigAutoGenSnd" SG_ 288 TSK_Freig_Verzoeg_Anf 1;
BA_ "GenSigAutoGenDsp" SG_ 288 TSK_Freig_Verzoeg_Anf 1;
BA_ "GenSigSwitchedByIgnition" SG_ 288 TSK_Limiter_ausgewaehlt 0;
BA_ "GenSigSendType" SG_ 288 TSK_Limiter_ausgewaehlt 0;
BA_ "GenSigEnvVarType" SG_ 288 TSK_Limiter_ausgewaehlt 0;
BA_ "GenSigAutoGenSnd" SG_ 288 TSK_Limiter_ausgewaehlt 1;
BA_ "GenSigAutoGenDsp" SG_ 288 TSK_Limiter_ausgewaehlt 1;
BA_ "GenSigSwitchedByIgnition" SG_ 288 TSK_ax_Getriebe_02 0;
BA_ "GenSigStartValue" SG_ 288 TSK_ax_Getriebe_02 511;
BA_ "GenSigSendType" SG_ 288 TSK_ax_Getriebe_02 0;
BA_ "GenSigEnvVarType" SG_ 288 TSK_ax_Getriebe_02 1;
BA_ "GenSigAutoGenSnd" SG_ 288 TSK_ax_Getriebe_02 1;
BA_ "GenSigAutoGenDsp" SG_ 288 TSK_ax_Getriebe_02 1;
BA_ "GenSigSwitchedByIgnition" SG_ 288 TSK_Zwangszusch_ESP 0;
BA_ "GenSigSendType" SG_ 288 TSK_Zwangszusch_ESP 0;
BA_ "GenSigEnvVarType" SG_ 288 TSK_Zwangszusch_ESP 0;
BA_ "GenSigAutoGenSnd" SG_ 288 TSK_Zwangszusch_ESP 1;
BA_ "GenSigAutoGenDsp" SG_ 288 TSK_Zwangszusch_ESP 1;
BA_ "GenSigSwitchedByIgnition" SG_ 288 TSK_zul_Regelabw 0;
BA_ "GenSigSendType" SG_ 288 TSK_zul_Regelabw 0;
BA_ "GenSigEnvVarType" SG_ 288 TSK_zul_Regelabw 1;
BA_ "GenSigAutoGenSnd" SG_ 288 TSK_zul_Regelabw 1;
BA_ "GenSigAutoGenDsp" SG_ 288 TSK_zul_Regelabw 1;
BA_ "GenSigSwitchedByIgnition" SG_ 798 TSK_07_CRC 0;
BA_ "GenSigFuncType" SG_ 798 TSK_07_CRC 2;
BA_ "GenSigSendType" SG_ 798 TSK_07_CRC 0;
BA_ "GenSigEnvVarType" SG_ 798 TSK_07_CRC 0;
BA_ "GenSigAutoGenSnd" SG_ 798 TSK_07_CRC 1;
BA_ "GenSigAutoGenDsp" SG_ 798 TSK_07_CRC 1;
BA_ "GenSigSwitchedByIgnition" SG_ 798 TSK_07_BZ 0;
BA_ "GenSigFuncType" SG_ 798 TSK_07_BZ 1;
BA_ "GenSigSendType" SG_ 798 TSK_07_BZ 0;
BA_ "GenSigEnvVarType" SG_ 798 TSK_07_BZ 0;
BA_ "GenSigAutoGenSnd" SG_ 798 TSK_07_BZ 1;
BA_ "GenSigAutoGenDsp" SG_ 798 TSK_07_BZ 1;
BA_ "GenSigSwitchedByIgnition" SG_ 798 TSK_Wunschgeschw 0;
BA_ "GenSigSendType" SG_ 798 TSK_Wunschgeschw 0;
BA_ "GenSigEnvVarType" SG_ 798 TSK_Wunschgeschw 1;
BA_ "GenSigAutoGenSnd" SG_ 798 TSK_Wunschgeschw 1;
BA_ "GenSigAutoGenDsp" SG_ 798 TSK_Wunschgeschw 1;
BA_ "GenSigSwitchedByIgnition" SG_ 798 TSK_Texte_Primaeranz 0;
BA_ "GenSigSendType" SG_ 798 TSK_Texte_Primaeranz 0;
BA_ "GenSigEnvVarType" SG_ 798 TSK_Texte_Primaeranz 0;
BA_ "GenSigAutoGenSnd" SG_ 798 TSK_Texte_Primaeranz 1;
BA_ "GenSigAutoGenDsp" SG_ 798 TSK_Texte_Primaeranz 1;
BA_ "GenSigSwitchedByIgnition" SG_ 798 TSK_Limiter_Anzeige 0;
BA_ "GenSigSendType" SG_ 798 TSK_Limiter_Anzeige 0;
BA_ "GenSigEnvVarType" SG_ 798 TSK_Limiter_Anzeige 0;
BA_ "GenSigAutoGenSnd" SG_ 798 TSK_Limiter_Anzeige 1;
BA_ "GenSigAutoGenDsp" SG_ 798 TSK_Limiter_Anzeige 1;
BA_ "GenSigSwitchedByIgnition" SG_ 798 TSK_Status_Anzeige 0;
BA_ "GenSigStartValue" SG_ 798 TSK_Status_Anzeige 1;
BA_ "GenSigSendType" SG_ 798 TSK_Status_Anzeige 0;
BA_ "GenSigEnvVarType" SG_ 798 TSK_Status_Anzeige 0;
BA_ "GenSigAutoGenSnd" SG_ 798 TSK_Status_Anzeige 1;
BA_ "GenSigAutoGenDsp" SG_ 798 TSK_Status_Anzeige 1;
BA_ "GenSigSwitchedByIgnition" SG_ 1716 VIN_01_MUX 0;
BA_ "GenSigSendType" SG_ 1716 VIN_01_MUX 0;
BA_ "GenSigEnvVarType" SG_ 1716 VIN_01_MUX 0;
BA_ "GenSigAutoGenSnd" SG_ 1716 VIN_01_MUX 1;
BA_ "GenSigAutoGenDsp" SG_ 1716 VIN_01_MUX 1;
BA_ "GenSigSwitchedByIgnition" SG_ 1716 KS_Geheimnis_1 0;
BA_ "GenSigEnvVarType" SG_ 1716 KS_Geheimnis_1 0;
BA_ "GenSigAutoGenSnd" SG_ 1716 KS_Geheimnis_1 1;
BA_ "GenSigAutoGenDsp" SG_ 1716 KS_Geheimnis_1 1;
BA_ "GenSigSwitchedByIgnition" SG_ 1716 VIN_4 0;
BA_ "GenSigEnvVarType" SG_ 1716 VIN_4 0;
BA_ "GenSigAutoGenSnd" SG_ 1716 VIN_4 1;
BA_ "GenSigAutoGenDsp" SG_ 1716 VIN_4 1;
BA_ "GenSigSwitchedByIgnition" SG_ 1716 VIN_11 0;
BA_ "GenSigEnvVarType" SG_ 1716 VIN_11 0;
BA_ "GenSigAutoGenSnd" SG_ 1716 VIN_11 1;
BA_ "GenSigAutoGenDsp" SG_ 1716 VIN_11 1;
BA_ "GenSigSwitchedByIgnition" SG_ 1716 KS_Geheimnis_2 0;
BA_ "GenSigEnvVarType" SG_ 1716 KS_Geheimnis_2 0;
BA_ "GenSigAutoGenSnd" SG_ 1716 KS_Geheimnis_2 1;
BA_ "GenSigAutoGenDsp" SG_ 1716 KS_Geheimnis_2 1;
BA_ "GenSigSwitchedByIgnition" SG_ 1716 VIN_5 0;
BA_ "GenSigEnvVarType" SG_ 1716 VIN_5 0;
BA_ "GenSigAutoGenSnd" SG_ 1716 VIN_5 1;
BA_ "GenSigAutoGenDsp" SG_ 1716 VIN_5 1;
BA_ "GenSigSwitchedByIgnition" SG_ 1716 VIN_12 0;
BA_ "GenSigEnvVarType" SG_ 1716 VIN_12 0;
BA_ "GenSigAutoGenSnd" SG_ 1716 VIN_12 1;
BA_ "GenSigAutoGenDsp" SG_ 1716 VIN_12 1;
BA_ "GenSigSwitchedByIgnition" SG_ 1716 KS_Geheimnis_3 0;
BA_ "GenSigEnvVarType" SG_ 1716 KS_Geheimnis_3 0;
BA_ "GenSigAutoGenSnd" SG_ 1716 KS_Geheimnis_3 1;
BA_ "GenSigAutoGenDsp" SG_ 1716 KS_Geheimnis_3 1;
BA_ "GenSigSwitchedByIgnition" SG_ 1716 VIN_6 0;
BA_ "GenSigEnvVarType" SG_ 1716 VIN_6 0;
BA_ "GenSigAutoGenSnd" SG_ 1716 VIN_6 1;
BA_ "GenSigAutoGenDsp" SG_ 1716 VIN_6 1;
BA_ "GenSigSwitchedByIgnition" SG_ 1716 VIN_13 0;
BA_ "GenSigEnvVarType" SG_ 1716 VIN_13 0;
BA_ "GenSigAutoGenSnd" SG_ 1716 VIN_13 1;
BA_ "GenSigAutoGenDsp" SG_ 1716 VIN_13 1;
BA_ "GenSigSwitchedByIgnition" SG_ 1716 KS_Geheimnis_4 0;
BA_ "GenSigEnvVarType" SG_ 1716 KS_Geheimnis_4 0;
BA_ "GenSigAutoGenSnd" SG_ 1716 KS_Geheimnis_4 1;
BA_ "GenSigAutoGenDsp" SG_ 1716 KS_Geheimnis_4 1;
BA_ "GenSigSwitchedByIgnition" SG_ 1716 VIN_7 0;
BA_ "GenSigEnvVarType" SG_ 1716 VIN_7 0;
BA_ "GenSigAutoGenSnd" SG_ 1716 VIN_7 1;
BA_ "GenSigAutoGenDsp" SG_ 1716 VIN_7 1;
BA_ "GenSigSwitchedByIgnition" SG_ 1716 VIN_14 0;
BA_ "GenSigEnvVarType" SG_ 1716 VIN_14 0;
BA_ "GenSigAutoGenSnd" SG_ 1716 VIN_14 1;
BA_ "GenSigAutoGenDsp" SG_ 1716 VIN_14 1;
BA_ "GenSigSwitchedByIgnition" SG_ 1716 VIN_1 0;
BA_ "GenSigEnvVarType" SG_ 1716 VIN_1 0;
BA_ "GenSigAutoGenSnd" SG_ 1716 VIN_1 1;
BA_ "GenSigAutoGenDsp" SG_ 1716 VIN_1 1;
BA_ "GenSigSwitchedByIgnition" SG_ 1716 VIN_8 0;
BA_ "GenSigEnvVarType" SG_ 1716 VIN_8 0;
BA_ "GenSigAutoGenSnd" SG_ 1716 VIN_8 1;
BA_ "GenSigAutoGenDsp" SG_ 1716 VIN_8 1;
BA_ "GenSigSwitchedByIgnition" SG_ 1716 VIN_15 0;
BA_ "GenSigEnvVarType" SG_ 1716 VIN_15 0;
BA_ "GenSigAutoGenSnd" SG_ 1716 VIN_15 1;
BA_ "GenSigAutoGenDsp" SG_ 1716 VIN_15 1;
BA_ "GenSigSwitchedByIgnition" SG_ 1716 VIN_2 0;
BA_ "GenSigEnvVarType" SG_ 1716 VIN_2 0;
BA_ "GenSigAutoGenSnd" SG_ 1716 VIN_2 1;
BA_ "GenSigAutoGenDsp" SG_ 1716 VIN_2 1;
BA_ "GenSigSwitchedByIgnition" SG_ 1716 VIN_9 0;
BA_ "GenSigEnvVarType" SG_ 1716 VIN_9 0;
BA_ "GenSigAutoGenSnd" SG_ 1716 VIN_9 1;
BA_ "GenSigAutoGenDsp" SG_ 1716 VIN_9 1;
BA_ "GenSigSwitchedByIgnition" SG_ 1716 VIN_16 0;
BA_ "GenSigEnvVarType" SG_ 1716 VIN_16 0;
BA_ "GenSigAutoGenSnd" SG_ 1716 VIN_16 1;
BA_ "GenSigAutoGenDsp" SG_ 1716 VIN_16 1;
BA_ "GenSigSwitchedByIgnition" SG_ 1716 VIN_3 0;
BA_ "GenSigEnvVarType" SG_ 1716 VIN_3 0;
BA_ "GenSigAutoGenSnd" SG_ 1716 VIN_3 1;
BA_ "GenSigAutoGenDsp" SG_ 1716 VIN_3 1;
BA_ "GenSigSwitchedByIgnition" SG_ 1716 VIN_10 0;
BA_ "GenSigEnvVarType" SG_ 1716 VIN_10 0;
BA_ "GenSigAutoGenSnd" SG_ 1716 VIN_10 1;
BA_ "GenSigAutoGenDsp" SG_ 1716 VIN_10 1;
BA_ "GenSigSwitchedByIgnition" SG_ 1716 VIN_17 0;
BA_ "GenSigEnvVarType" SG_ 1716 VIN_17 0;
BA_ "GenSigAutoGenSnd" SG_ 1716 VIN_17 1;
BA_ "GenSigAutoGenDsp" SG_ 1716 VIN_17 1;
BA_ "Fehlerwert" SG_ 175 WH_Status_Sperre 7;
BA_ "GenSigSwitchedByIgnition" SG_ 175 WH_Status_Sperre 0;
BA_ "GenSigSendType" SG_ 175 WH_Status_Sperre 0;
BA_ "GenSigEnvVarType" SG_ 175 WH_Status_Sperre 0;
BA_ "GenSigAutoGenSnd" SG_ 175 WH_Status_Sperre 1;
BA_ "GenSigAutoGenDsp" SG_ 175 WH_Status_Sperre 1;
BA_ "GenSigSwitchedByIgnition" SG_ 175 WH_Initialisierung 0;
BA_ "GenSigStartValue" SG_ 175 WH_Initialisierung 1;
BA_ "GenSigSendType" SG_ 175 WH_Initialisierung 0;
BA_ "GenSigEnvVarType" SG_ 175 WH_Initialisierung 0;
BA_ "GenSigAutoGenSnd" SG_ 175 WH_Initialisierung 1;
BA_ "GenSigAutoGenDsp" SG_ 175 WH_Initialisierung 1;
BA_ "Fehlerwert" SG_ 175 WH_SensorPos_roh 15;
BA_ "GenSigSwitchedByIgnition" SG_ 175 WH_SensorPos_roh 0;
BA_ "GenSigSendType" SG_ 175 WH_SensorPos_roh 0;
BA_ "GenSigAutoGenSnd" SG_ 175 WH_SensorPos_roh 1;
BA_ "GenSigAutoGenDsp" SG_ 175 WH_SensorPos_roh 1;
BA_ "GenSigSwitchedByIgnition" SG_ 175 WH_03_BZ 0;
BA_ "GenSigFuncType" SG_ 175 WH_03_BZ 1;
BA_ "GenSigSendType" SG_ 175 WH_03_BZ 0;
BA_ "GenSigEnvVarType" SG_ 175 WH_03_BZ 0;
BA_ "GenSigAutoGenSnd" SG_ 175 WH_03_BZ 1;
BA_ "GenSigAutoGenDsp" SG_ 175 WH_03_BZ 1;
BA_ "GenSigSwitchedByIgnition" SG_ 175 WH_SensorPos_roh_inv 0;
BA_ "GenSigStartValue" SG_ 175 WH_SensorPos_roh_inv 15;
BA_ "GenSigSendType" SG_ 175 WH_SensorPos_roh_inv 0;
BA_ "GenSigAutoGenSnd" SG_ 175 WH_SensorPos_roh_inv 1;
BA_ "GenSigAutoGenDsp" SG_ 175 WH_SensorPos_roh_inv 1;
BA_ "GenSigSwitchedByIgnition" SG_ 175 WH_Testergebnis 0;
BA_ "GenSigSendType" SG_ 175 WH_Testergebnis 0;
BA_ "GenSigEnvVarType" SG_ 175 WH_Testergebnis 0;
BA_ "GenSigAutoGenSnd" SG_ 175 WH_Testergebnis 1;
BA_ "GenSigAutoGenDsp" SG_ 175 WH_Testergebnis 1;
BA_ "GenSigSwitchedByIgnition" SG_ 175 WH_Test_Aktiv 0;
BA_ "GenSigSendType" SG_ 175 WH_Test_Aktiv 0;
BA_ "GenSigEnvVarType" SG_ 175 WH_Test_Aktiv 0;
BA_ "GenSigAutoGenSnd" SG_ 175 WH_Test_Aktiv 1;
BA_ "GenSigAutoGenDsp" SG_ 175 WH_Test_Aktiv 1;
BA_ "GenSigSwitchedByIgnition" SG_ 175 WH_Status 0;
BA_ "GenSigSendType" SG_ 175 WH_Status 0;
BA_ "GenSigEnvVarType" SG_ 175 WH_Status 0;
BA_ "GenSigAutoGenSnd" SG_ 175 WH_Status 1;
BA_ "GenSigAutoGenDsp" SG_ 175 WH_Status 1;
BA_ "GenSigSwitchedByIgnition" SG_ 916 WBA_03_CRC 0;
BA_ "GenSigFuncType" SG_ 916 WBA_03_CRC 2;
BA_ "GenSigSendType" SG_ 916 WBA_03_CRC 0;
BA_ "GenSigEnvVarType" SG_ 916 WBA_03_CRC 0;
BA_ "GenSigAutoGenSnd" SG_ 916 WBA_03_CRC 1;
BA_ "GenSigAutoGenDsp" SG_ 916 WBA_03_CRC 1;
BA_ "GenSigSwitchedByIgnition" SG_ 916 WBA_03_BZ 0;
BA_ "GenSigFuncType" SG_ 916 WBA_03_BZ 1;
BA_ "GenSigSendType" SG_ 916 WBA_03_BZ 0;
BA_ "GenSigEnvVarType" SG_ 916 WBA_03_BZ 0;
BA_ "GenSigAutoGenSnd" SG_ 916 WBA_03_BZ 1;
BA_ "GenSigAutoGenDsp" SG_ 916 WBA_03_BZ 1;
BA_ "GenSigSwitchedByIgnition" SG_ 916 WBA_Fahrstufe_02 0;
BA_ "GenSigSendType" SG_ 916 WBA_Fahrstufe_02 3;
BA_ "GenSigEnvVarType" SG_ 916 WBA_Fahrstufe_02 0;
BA_ "GenSigAutoGenSnd" SG_ 916 WBA_Fahrstufe_02 1;
BA_ "GenSigAutoGenDsp" SG_ 916 WBA_Fahrstufe_02 1;
BA_ "GenSigSwitchedByIgnition" SG_ 916 WBA_ZielFahrstufe 0;
BA_ "GenSigSendType" SG_ 916 WBA_ZielFahrstufe 3;
BA_ "GenSigEnvVarType" SG_ 916 WBA_ZielFahrstufe 0;
BA_ "GenSigAutoGenSnd" SG_ 916 WBA_ZielFahrstufe 1;
BA_ "GenSigAutoGenDsp" SG_ 916 WBA_ZielFahrstufe 1;
BA_ "GenSigSwitchedByIgnition" SG_ 916 WBA_GE_Warnung_02 0;
BA_ "GenSigSendType" SG_ 916 WBA_GE_Warnung_02 3;
BA_ "GenSigAutoGenSnd" SG_ 916 WBA_GE_Warnung_02 1;
BA_ "GenSigAutoGenDsp" SG_ 916 WBA_GE_Warnung_02 1;
BA_ "GenSigSwitchedByIgnition" SG_ 916 WBA_eing_Gang_02 0;
BA_ "GenSigSendType" SG_ 916 WBA_eing_Gang_02 3;
BA_ "GenSigEnvVarType" SG_ 916 WBA_eing_Gang_02 0;
BA_ "GenSigAutoGenSnd" SG_ 916 WBA_eing_Gang_02 1;
BA_ "GenSigAutoGenDsp" SG_ 916 WBA_eing_Gang_02 1;
BA_ "GenSigSwitchedByIgnition" SG_ 916 WBA_GE_Texte 0;
BA_ "GenSigAutoGenSnd" SG_ 916 WBA_GE_Texte 1;
BA_ "GenSigAutoGenDsp" SG_ 916 WBA_GE_Texte 1;
BA_ "GenSigSwitchedByIgnition" SG_ 916 WBA_Segeln_aktiv 0;
BA_ "GenSigSendType" SG_ 916 WBA_Segeln_aktiv 3;
BA_ "GenSigAutoGenSnd" SG_ 916 WBA_Segeln_aktiv 1;
BA_ "GenSigAutoGenDsp" SG_ 916 WBA_Segeln_aktiv 1;
BA_ "GenSigSwitchedByIgnition" SG_ 916 WBA_Schaltschema 0;
BA_ "GenSigSendType" SG_ 916 WBA_Schaltschema 3;
BA_ "GenSigAutoGenSnd" SG_ 916 WBA_Schaltschema 1;
BA_ "GenSigAutoGenDsp" SG_ 916 WBA_Schaltschema 1;
BA_ "Fehlerwert" SG_ 1602 WIV_Verschleissindex 65535;
BA_ "GenSigSwitchedByIgnition" SG_ 1602 WIV_Verschleissindex 0;
BA_ "GenSigSendType" SG_ 1602 WIV_Verschleissindex 3;
BA_ "GenSigEnvVarType" SG_ 1602 WIV_Verschleissindex 1;
BA_ "GenSigAutoGenSnd" SG_ 1602 WIV_Verschleissindex 1;
BA_ "GenSigAutoGenDsp" SG_ 1602 WIV_Verschleissindex 1;
BA_ "Fehlerwert" SG_ 1602 WIV_Russindex 65535;
BA_ "GenSigSwitchedByIgnition" SG_ 1602 WIV_Russindex 0;
BA_ "GenSigSendType" SG_ 1602 WIV_Russindex 3;
BA_ "GenSigEnvVarType" SG_ 1602 WIV_Russindex 1;
BA_ "GenSigAutoGenSnd" SG_ 1602 WIV_Russindex 1;
BA_ "GenSigAutoGenDsp" SG_ 1602 WIV_Russindex 1;
BA_ "GenSigSwitchedByIgnition" SG_ 1602 WIV_t_min 0;
BA_ "GenSigStartValue" SG_ 1602 WIV_t_min 12;
BA_ "GenSigSendType" SG_ 1602 WIV_t_min 3;
BA_ "GenSigEnvVarType" SG_ 1602 WIV_t_min 0;
BA_ "GenSigAutoGenSnd" SG_ 1602 WIV_t_min 1;
BA_ "GenSigAutoGenDsp" SG_ 1602 WIV_t_min 1;
BA_ "GenSigSwitchedByIgnition" SG_ 1602 WIV_t_max 0;
BA_ "GenSigStartValue" SG_ 1602 WIV_t_max 24;
BA_ "GenSigSendType" SG_ 1602 WIV_t_max 3;
BA_ "GenSigEnvVarType" SG_ 1602 WIV_t_max 0;
BA_ "GenSigAutoGenSnd" SG_ 1602 WIV_t_max 1;
BA_ "GenSigAutoGenDsp" SG_ 1602 WIV_t_max 1;
BA_ "GenSigSwitchedByIgnition" SG_ 1602 WIV_W_min 0;
BA_ "GenSigStartValue" SG_ 1602 WIV_W_min 17;
BA_ "GenSigSendType" SG_ 1602 WIV_W_min 3;
BA_ "GenSigEnvVarType" SG_ 1602 WIV_W_min 0;
BA_ "GenSigAutoGenSnd" SG_ 1602 WIV_W_min 1;
BA_ "GenSigAutoGenDsp" SG_ 1602 WIV_W_min 1;
BA_ "GenSigSwitchedByIgnition" SG_ 1602 WIV_W_max 0;
BA_ "GenSigStartValue" SG_ 1602 WIV_W_max 31;
BA_ "GenSigSendType" SG_ 1602 WIV_W_max 3;
BA_ "GenSigEnvVarType" SG_ 1602 WIV_W_max 0;
BA_ "GenSigAutoGenSnd" SG_ 1602 WIV_W_max 1;
BA_ "GenSigAutoGenDsp" SG_ 1602 WIV_W_max 1;
BA_REL_ "GenSigTimeoutTime" BU_SG_REL_ Getriebe_DQ_Hybrid_MQB SG_ 812 MO_Prio_MAX_Wunschdrehzahl 500;
BA_REL_ "GenSigTimeoutTime" BU_SG_REL_ Getriebe_DQ_MQB SG_ 812 MO_Prio_MAX_Wunschdrehzahl 500;
BA_REL_ "GenSigTimeoutTime" BU_SG_REL_ Getriebe_DQ_Hybrid_MQB SG_ 812 MO_Prio_MIN_Wunschdrehzahl 500;
BA_REL_ "GenSigTimeoutTime" BU_SG_REL_ Getriebe_DQ_MQB SG_ 812 MO_Prio_MIN_Wunschdrehzahl 500;
BA_REL_ "GenSigTimeoutTime" BU_SG_REL_ Getriebe_DQ_Hybrid_MQB SG_ 812 MO_Drehzahlbeeinflussung 500;
BA_REL_ "GenSigTimeoutTime" BU_SG_REL_ Getriebe_DQ_MQB SG_ 812 MO_Drehzahlbeeinflussung 500;
BA_REL_ "GenSigTimeoutTime" BU_SG_REL_ Getriebe_DQ_Hybrid_MQB SG_ 812 MO_MIN_Wunschdrehzahl 500;
BA_REL_ "GenSigTimeoutTime" BU_SG_REL_ Getriebe_DQ_MQB SG_ 812 MO_MIN_Wunschdrehzahl 500;
BA_REL_ "GenSigTimeoutTime" BU_SG_REL_ Getriebe_DQ_Hybrid_MQB SG_ 812 MO_MAX_Wunschdrehzahl 500;
BA_REL_ "GenSigTimeoutTime" BU_SG_REL_ Getriebe_DQ_MQB SG_ 812 MO_MAX_Wunschdrehzahl 500;
BA_REL_ "GenSigTimeoutTime" BU_SG_REL_ Gateway_MQB SG_ 812 MO_Charisma_FahrPr 500;
BA_REL_ "GenSigTimeoutTime" BU_SG_REL_ Gateway_MQB SG_ 812 MO_Charisma_Status 500;
BA_REL_ "GenSigTimeoutTime" BU_SG_REL_ Getriebe_DQ_Hybrid_MQB SG_ 1648 MO_obere_Drehzahlgrenze 5000;
BA_REL_ "GenSigTimeoutTime" BU_SG_REL_ Getriebe_DQ_MQB SG_ 1648 MO_obere_Drehzahlgrenze 5000;
BA_REL_ "GenSigTimeoutTime" BU_SG_REL_ Airbag_MQB SG_ 289 MO_Fahrpedalrohwert_01 500;
BA_REL_ "GenSigTimeoutTime" BU_SG_REL_ Gateway_MQB SG_ 289 MO_Fahrpedalrohwert_01 500;
BA_REL_ "GenSigTimeoutTime" BU_SG_REL_ Gateway_MQB SG_ 289 MO_Fahrpedalrohwert_01 500;
BA_REL_ "GenSigTimeoutTime" BU_SG_REL_ Gateway_MQB SG_ 289 MO_Fahrpedalrohwert_01 500;
BA_REL_ "GenSigTimeoutTime" BU_SG_REL_ Getriebe_DQ_Hybrid_MQB SG_ 289 MO_Fahrpedalrohwert_01 500;
BA_REL_ "GenSigTimeoutTime" BU_SG_REL_ Getriebe_DQ_MQB SG_ 289 MO_Fahrpedalrohwert_01 500;
BA_REL_ "GenSigTimeoutTime" BU_SG_REL_ Airbag_MQB SG_ 289 MO_QBit_Fahrpedalwerte_01 500;
BA_REL_ "GenSigTimeoutTime" BU_SG_REL_ Gateway_MQB SG_ 289 MO_QBit_Fahrpedalwerte_01 500;
BA_REL_ "GenSigTimeoutTime" BU_SG_REL_ Gateway_MQB SG_ 289 MO_QBit_Fahrpedalwerte_01 500;
BA_REL_ "GenSigTimeoutTime" BU_SG_REL_ Getriebe_DQ_Hybrid_MQB SG_ 289 MO_QBit_Fahrpedalwerte_01 500;
BA_REL_ "GenSigTimeoutTime" BU_SG_REL_ Getriebe_DQ_MQB SG_ 289 MO_QBit_Fahrpedalwerte_01 500;
BA_REL_ "GenSigTimeoutTime" BU_SG_REL_ Airbag_MQB SG_ 289 MO_Fahrpedalgradient 500;
BA_REL_ "GenSigTimeoutTime" BU_SG_REL_ Getriebe_DQ_Hybrid_MQB SG_ 289 MO_Fahrpedalgradient 500;
BA_REL_ "GenSigTimeoutTime" BU_SG_REL_ Getriebe_DQ_MQB SG_ 289 MO_Fahrpedalgradient 500;
BA_REL_ "GenSigTimeoutTime" BU_SG_REL_ Airbag_MQB SG_ 289 MO_Sig_Fahrpedalgradient 500;
BA_REL_ "GenSigTimeoutTime" BU_SG_REL_ Getriebe_DQ_Hybrid_MQB SG_ 289 MO_Sig_Fahrpedalgradient 500;
BA_REL_ "GenSigTimeoutTime" BU_SG_REL_ Getriebe_DQ_MQB SG_ 289 MO_Sig_Fahrpedalgradient 500;
BA_REL_ "GenSigTimeoutTime" BU_SG_REL_ Getriebe_DQ_Hybrid_MQB SG_ 289 MO_Moment_im_Leerlauf 500;
BA_REL_ "GenSigTimeoutTime" BU_SG_REL_ Getriebe_DQ_MQB SG_ 289 MO_Moment_im_Leerlauf 500;
BA_REL_ "GenSigTimeoutTime" BU_SG_REL_ Gateway_MQB SG_ 289 MO_Solldrehz_Leerlauf 500;
BA_REL_ "GenSigTimeoutTime" BU_SG_REL_ Getriebe_DQ_Hybrid_MQB SG_ 289 MO_Solldrehz_Leerlauf 500;
BA_REL_ "GenSigTimeoutTime" BU_SG_REL_ Getriebe_DQ_MQB SG_ 289 MO_Solldrehz_Leerlauf 500;
BA_REL_ "GenSigTimeoutTime" BU_SG_REL_ Getriebe_DQ_Hybrid_MQB SG_ 967 MO_Kuehlerluefter_MUX 1000;
BA_REL_ "GenSigTimeoutTime" BU_SG_REL_ Getriebe_DQ_MQB SG_ 967 MO_Kuehlerluefter_MUX 1000;
BA_REL_ "GenSigTimeoutTime" BU_SG_REL_ Getriebe_DQ_Hybrid_MQB SG_ 967 MO_Kuehlerluefter_1 1000;
BA_REL_ "GenSigTimeoutTime" BU_SG_REL_ Getriebe_DQ_MQB SG_ 967 MO_Kuehlerluefter_1 1000;
BA_REL_ "GenSigTimeoutTime" BU_SG_REL_ Getriebe_DQ_Hybrid_MQB SG_ 967 MO_Kuehlerluefter_2 1000;
BA_REL_ "GenSigTimeoutTime" BU_SG_REL_ Getriebe_DQ_MQB SG_ 967 MO_Kuehlerluefter_2 1000;
BA_REL_ "GenSigTimeoutTime" BU_SG_REL_ Getriebe_DQ_Hybrid_MQB SG_ 967 MO_Winterfahrprog 1000;
BA_REL_ "GenSigTimeoutTime" BU_SG_REL_ Getriebe_DQ_MQB SG_ 967 MO_Winterfahrprog 1000;
BA_REL_ "GenSigTimeoutTime" BU_SG_REL_ Getriebe_DQ_Hybrid_MQB SG_ 1601 MO_Faktor_Momente_02 5000;
BA_REL_ "GenSigTimeoutTime" BU_SG_REL_ Getriebe_DQ_MQB SG_ 1601 MO_Faktor_Momente_02 5000;
BA_REL_ "GenSigTimeoutTime" BU_SG_REL_ SAK_MQB SG_ 1601 MO_Code 5000;
BA_REL_ "GenSigTimeoutTime" BU_SG_REL_ Gateway_MQB SG_ 1601 MO_Getriebe_Code 5000;
BA_REL_ "GenSigTimeoutTime" BU_SG_REL_ Gateway_MQB SG_ 1601 MO_Anzahl_Zyl 5000;
BA_REL_ "GenSigTimeoutTime" BU_SG_REL_ Gateway_MQB SG_ 1601 MO_Kraftstoffart 5000;
BA_REL_ "GenSigTimeoutTime" BU_SG_REL_ Gateway_MQB SG_ 1601 MO_Kraftstoffart 5000;
BA_REL_ "GenSigTimeoutTime" BU_SG_REL_ Getriebe_DQ_Hybrid_MQB SG_ 1601 MO_Kraftstoffart 5000;
BA_REL_ "GenSigTimeoutTime" BU_SG_REL_ Getriebe_DQ_MQB SG_ 1601 MO_Kraftstoffart 5000;
BA_REL_ "GenSigTimeoutTime" BU_SG_REL_ Gateway_MQB SG_ 1601 MO_Hubraum 5000;
BA_REL_ "GenSigTimeoutTime" BU_SG_REL_ BMS_MQB SG_ 1601 MO_Abgastyp_EOBD 5000;
BA_REL_ "GenSigTimeoutTime" BU_SG_REL_ LEH_MQB SG_ 1601 MO_Abgastyp_EOBD 5000;
BA_REL_ "GenSigTimeoutTime" BU_SG_REL_ BMS_MQB SG_ 1601 MO_Abgastyp_OBD 5000;
BA_REL_ "GenSigTimeoutTime" BU_SG_REL_ LEH_MQB SG_ 1601 MO_Abgastyp_OBD 5000;
BA_REL_ "GenSigTimeoutTime" BU_SG_REL_ Gateway_MQB SG_ 1601 TSK_Codierung 5000;
BA_REL_ "GenSigTimeoutTime" BU_SG_REL_ Getriebe_DQ_Hybrid_MQB SG_ 1601 TSK_Codierung 5000;
BA_REL_ "GenSigTimeoutTime" BU_SG_REL_ Getriebe_DQ_MQB SG_ 1601 TSK_Codierung 5000;
BA_REL_ "GenSigTimeoutTime" BU_SG_REL_ Getriebe_DQ_Hybrid_MQB SG_ 157 Motor_Hybrid_01_CRC 500;
BA_REL_ "GenSigTimeoutTime" BU_SG_REL_ BMS_MQB SG_ 157 Motor_Hybrid_01_BZ 500;
BA_REL_ "GenSigTimeoutTime" BU_SG_REL_ Getriebe_DQ_Hybrid_MQB SG_ 157 Motor_Hybrid_01_BZ 500;
BA_REL_ "GenSigTimeoutTime" BU_SG_REL_ Getriebe_DQ_Hybrid_MQB SG_ 157 MO_HYB_IstStatusK0 500;
BA_REL_ "GenSigTimeoutTime" BU_SG_REL_ Getriebe_DQ_Hybrid_MQB SG_ 157 MO_HYB_max_ind_VM_Mom 500;
BA_REL_ "GenSigTimeoutTime" BU_SG_REL_ BMS_MQB SG_ 157 MO_HYB_Zielzustand 500;
BA_REL_ "GenSigTimeoutTime" BU_SG_REL_ Getriebe_DQ_Hybrid_MQB SG_ 157 MO_HYB_Zielzustand 500;
BA_REL_ "GenSigTimeoutTime" BU_SG_REL_ Getriebe_DQ_Hybrid_MQB SG_ 157 MO_HYB_Startmodus_PQ3x 500;
BA_REL_ "GenSigTimeoutTime" BU_SG_REL_ Getriebe_DQ_Hybrid_MQB SG_ 157 MO_HYB_Stoppmodus 500;
BA_REL_ "GenSigTimeoutTime" BU_SG_REL_ Getriebe_DQ_Hybrid_MQB SG_ 157 MO_HYB_VM_Mom_oE 500;
BA_REL_ "GenSigTimeoutTime" BU_SG_REL_ Getriebe_DQ_Hybrid_MQB SG_ 157 MO_HYB_VM_aktiv 500;
BA_REL_ "GenSigTimeoutTime" BU_SG_REL_ Getriebe_DQ_Hybrid_MQB SG_ 157 MO_HYB_Schaltverhinderung 500;
BA_REL_ "GenSigTimeoutTime" BU_SG_REL_ Getriebe_DQ_Hybrid_MQB SG_ 157 MO_HYB_Selektor_Momverlauf_EM 500;
BA_REL_ "GenSigTimeoutTime" BU_SG_REL_ Getriebe_DQ_Hybrid_MQB SG_ 157 MO_HYB_Momverlauf_Rek 500;
BA_REL_ "GenSigTimeoutTime" BU_SG_REL_ Getriebe_DQ_Hybrid_MQB SG_ 157 MO_HYB_KnickDZ_Rek 500;
BA_REL_ "GenSigTimeoutTime" BU_SG_REL_ Getriebe_DQ_Hybrid_MQB SG_ 157 MO_HYB_Momverlauf_EM 500;
BA_REL_ "GenSigTimeoutTime" BU_SG_REL_ Getriebe_DQ_Hybrid_MQB SG_ 157 MO_HYB_KnickDZ_EM 500;
BA_REL_ "GenSigTimeoutTime" BU_SG_REL_ Getriebe_DQ_Hybrid_MQB SG_ 811 MO_HYB_E_Faktor 500;
BA_REL_ "GenSigTimeoutTime" BU_SG_REL_ Getriebe_DQ_Hybrid_MQB SG_ 811 MO_HYB_Drehzahl_VM 500;
BA_REL_ "GenSigTimeoutTime" BU_SG_REL_ Getriebe_DQ_Hybrid_MQB SG_ 811 MO_HYB_LowSpeedModus 500;
BA_REL_ "GenSigTimeoutTime" BU_SG_REL_ BMS_MQB SG_ 913 OBD_Calc_Load_Val 1000;
BA_REL_ "GenSigTimeoutTime" BU_SG_REL_ Getriebe_DQ_Hybrid_MQB SG_ 913 OBD_Calc_Load_Val 1000;
BA_REL_ "GenSigTimeoutTime" BU_SG_REL_ Getriebe_DQ_MQB SG_ 913 OBD_Calc_Load_Val 1000;
BA_REL_ "GenSigTimeoutTime" BU_SG_REL_ LEH_MQB SG_ 913 OBD_Calc_Load_Val 1000;
BA_REL_ "GenSigTimeoutTime" BU_SG_REL_ BMS_MQB SG_ 913 OBD_Eng_Cool_Temp 1000;
BA_REL_ "GenSigTimeoutTime" BU_SG_REL_ Getriebe_DQ_Hybrid_MQB SG_ 913 OBD_Eng_Cool_Temp 1000;
BA_REL_ "GenSigTimeoutTime" BU_SG_REL_ Getriebe_DQ_MQB SG_ 913 OBD_Eng_Cool_Temp 1000;
BA_REL_ "GenSigTimeoutTime" BU_SG_REL_ LEH_MQB SG_ 913 OBD_Eng_Cool_Temp 1000;
BA_REL_ "GenSigTimeoutTime" BU_SG_REL_ BMS_MQB SG_ 913 OBD_Abs_Throttle_Pos 1000;
BA_REL_ "GenSigTimeoutTime" BU_SG_REL_ Getriebe_DQ_Hybrid_MQB SG_ 913 OBD_Abs_Throttle_Pos 1000;
BA_REL_ "GenSigTimeoutTime" BU_SG_REL_ Getriebe_DQ_MQB SG_ 913 OBD_Abs_Throttle_Pos 1000;
BA_REL_ "GenSigTimeoutTime" BU_SG_REL_ LEH_MQB SG_ 913 OBD_Abs_Throttle_Pos 1000;
BA_REL_ "GenSigTimeoutTime" BU_SG_REL_ BMS_MQB SG_ 913 OBD_Abs_Load_Val 1000;
BA_REL_ "GenSigTimeoutTime" BU_SG_REL_ Getriebe_DQ_Hybrid_MQB SG_ 913 OBD_Abs_Load_Val 1000;
BA_REL_ "GenSigTimeoutTime" BU_SG_REL_ Getriebe_DQ_MQB SG_ 913 OBD_Abs_Load_Val 1000;
BA_REL_ "GenSigTimeoutTime" BU_SG_REL_ LEH_MQB SG_ 913 OBD_Abs_Load_Val 1000;
BA_REL_ "GenSigTimeoutTime" BU_SG_REL_ BMS_MQB SG_ 913 OBD_Abs_Pedal_Pos 1000;
BA_REL_ "GenSigTimeoutTime" BU_SG_REL_ Getriebe_DQ_Hybrid_MQB SG_ 913 OBD_Abs_Pedal_Pos 1000;
BA_REL_ "GenSigTimeoutTime" BU_SG_REL_ Getriebe_DQ_MQB SG_ 913 OBD_Abs_Pedal_Pos 1000;
BA_REL_ "GenSigTimeoutTime" BU_SG_REL_ LEH_MQB SG_ 913 OBD_Abs_Pedal_Pos 1000;
BA_REL_ "GenSigTimeoutTime" BU_SG_REL_ BMS_MQB SG_ 913 OBD_Kaltstart_Denominator 1000;
BA_REL_ "GenSigTimeoutTime" BU_SG_REL_ LEH_MQB SG_ 913 OBD_Kaltstart_Denominator 1000;
BA_REL_ "GenSigTimeoutTime" BU_SG_REL_ BMS_MQB SG_ 913 OBD_Minimum_Trip 1000;
BA_REL_ "GenSigTimeoutTime" BU_SG_REL_ Getriebe_DQ_Hybrid_MQB SG_ 913 OBD_Minimum_Trip 1000;
BA_REL_ "GenSigTimeoutTime" BU_SG_REL_ Getriebe_DQ_MQB SG_ 913 OBD_Minimum_Trip 1000;
BA_REL_ "GenSigTimeoutTime" BU_SG_REL_ LEH_MQB SG_ 913 OBD_Minimum_Trip 1000;
BA_REL_ "GenSigTimeoutTime" BU_SG_REL_ BMS_MQB SG_ 913 OBD_Driving_Cycle 1000;
BA_REL_ "GenSigTimeoutTime" BU_SG_REL_ Getriebe_DQ_Hybrid_MQB SG_ 913 OBD_Driving_Cycle 1000;
BA_REL_ "GenSigTimeoutTime" BU_SG_REL_ Getriebe_DQ_MQB SG_ 913 OBD_Driving_Cycle 1000;
BA_REL_ "GenSigTimeoutTime" BU_SG_REL_ LEH_MQB SG_ 913 OBD_Driving_Cycle 1000;
BA_REL_ "GenSigTimeoutTime" BU_SG_REL_ BMS_MQB SG_ 913 OBD_Warm_Up_Cycle 1000;
BA_REL_ "GenSigTimeoutTime" BU_SG_REL_ Gateway_MQB SG_ 913 OBD_Warm_Up_Cycle 1000;
BA_REL_ "GenSigTimeoutTime" BU_SG_REL_ Getriebe_DQ_Hybrid_MQB SG_ 913 OBD_Warm_Up_Cycle 1000;
BA_REL_ "GenSigTimeoutTime" BU_SG_REL_ Getriebe_DQ_MQB SG_ 913 OBD_Warm_Up_Cycle 1000;
BA_REL_ "GenSigTimeoutTime" BU_SG_REL_ LEH_MQB SG_ 913 OBD_Warm_Up_Cycle 1000;
BA_REL_ "GenSigTimeoutTime" BU_SG_REL_ BMS_MQB SG_ 913 OBD_Normed_Trip 1000;
BA_REL_ "GenSigTimeoutTime" BU_SG_REL_ Getriebe_DQ_Hybrid_MQB SG_ 913 OBD_Normed_Trip 1000;
BA_REL_ "GenSigTimeoutTime" BU_SG_REL_ Getriebe_DQ_MQB SG_ 913 OBD_Normed_Trip 1000;
BA_REL_ "GenSigTimeoutTime" BU_SG_REL_ LEH_MQB SG_ 913 OBD_Normed_Trip 1000;
BA_REL_ "GenSigTimeoutTime" BU_SG_REL_ Motor_Hybrid_MQB SG_ 1630 OBD_TG_F_Status_1 5000;
BA_REL_ "GenSigTimeoutTime" BU_SG_REL_ Motor_Otto_MQB SG_ 1630 OBD_TG_F_Status_1 5000;
BA_REL_ "GenSigTimeoutTime" BU_SG_REL_ Motor_Hybrid_MQB SG_ 1630 OBD_TG_F_Status_2 5000;
BA_REL_ "GenSigTimeoutTime" BU_SG_REL_ Motor_Otto_MQB SG_ 1630 OBD_TG_F_Status_2 5000;
BA_REL_ "GenSigTimeoutTime" BU_SG_REL_ Motor_Hybrid_MQB SG_ 1630 OBD_TG_F_Status_3 5000;
BA_REL_ "GenSigTimeoutTime" BU_SG_REL_ Motor_Otto_MQB SG_ 1630 OBD_TG_F_Status_3 5000;
BA_REL_ "GenSigTimeoutTime" BU_SG_REL_ Motor_Hybrid_MQB SG_ 1630 OBD_TG_F_Status_4 5000;
BA_REL_ "GenSigTimeoutTime" BU_SG_REL_ Motor_Otto_MQB SG_ 1630 OBD_TG_F_Status_4 5000;
BA_REL_ "GenSigTimeoutTime" BU_SG_REL_ Motor_Hybrid_MQB SG_ 1630 OBD_TG_Sens_Rohwert_1 5000;
BA_REL_ "GenSigTimeoutTime" BU_SG_REL_ Motor_Otto_MQB SG_ 1630 OBD_TG_Sens_Rohwert_1 5000;
BA_REL_ "GenSigTimeoutTime" BU_SG_REL_ Motor_Hybrid_MQB SG_ 1630 OBD_TG_Sens_Rohwert_2 5000;
BA_REL_ "GenSigTimeoutTime" BU_SG_REL_ Motor_Otto_MQB SG_ 1630 OBD_TG_Sens_Rohwert_2 5000;
BA_REL_ "GenSigTimeoutTime" BU_SG_REL_ Motor_Hybrid_MQB SG_ 1630 OBD_TG_Sens_Rohwert_3 5000;
BA_REL_ "GenSigTimeoutTime" BU_SG_REL_ Motor_Otto_MQB SG_ 1630 OBD_TG_Sens_Rohwert_3 5000;
BA_REL_ "GenSigTimeoutTime" BU_SG_REL_ Motor_Hybrid_MQB SG_ 1630 OBD_TG_Sens_Rohwert_4 5000;
BA_REL_ "GenSigTimeoutTime" BU_SG_REL_ Motor_Otto_MQB SG_ 1630 OBD_TG_Sens_Rohwert_4 5000;
BA_REL_ "GenSigTimeoutTime" BU_SG_REL_ Gateway_MQB SG_ 984 RGS_VL_Charisma_FahrPr 1000;
BA_REL_ "GenSigTimeoutTime" BU_SG_REL_ Gateway_MQB SG_ 984 RGS_VL_Charisma_Status 1000;
BA_REL_ "GenSigTimeoutTime" BU_SG_REL_ Gateway_MQB SG_ 1528 SAK_Charisma_FahrPr 5000;
BA_REL_ "GenSigTimeoutTime" BU_SG_REL_ Gateway_MQB SG_ 1528 SAK_Charisma_Status 5000;
BA_REL_ "GenSigTimeoutTime" BU_SG_REL_ Motor_Diesel_MQB SG_ 1313 STH_LED 2000;
BA_REL_ "GenSigTimeoutTime" BU_SG_REL_ Motor_Hybrid_MQB SG_ 1313 STH_LED 2000;
BA_REL_ "GenSigTimeoutTime" BU_SG_REL_ Motor_Otto_MQB SG_ 1313 STH_LED 2000;
BA_REL_ "GenSigTimeoutTime" BU_SG_REL_ Motor_Diesel_MQB SG_ 1313 STH_EKP_Anst 2000;
BA_REL_ "GenSigTimeoutTime" BU_SG_REL_ Motor_Hybrid_MQB SG_ 1313 STH_EKP_Anst 2000;
BA_REL_ "GenSigTimeoutTime" BU_SG_REL_ Motor_Otto_MQB SG_ 1313 STH_EKP_Anst 2000;
BA_REL_ "GenSigTimeoutTime" BU_SG_REL_ Motor_Diesel_MQB SG_ 1313 STH_Motorvorwaermung 2000;
BA_REL_ "GenSigTimeoutTime" BU_SG_REL_ Motor_Hybrid_MQB SG_ 1313 STH_Motorvorwaermung 2000;
BA_REL_ "GenSigTimeoutTime" BU_SG_REL_ Motor_Otto_MQB SG_ 1313 STH_Motorvorwaermung 2000;
BA_REL_ "GenSigTimeoutTime" BU_SG_REL_ Motor_Diesel_MQB SG_ 1313 STH_war_aktiv 2000;
BA_REL_ "GenSigTimeoutTime" BU_SG_REL_ Motor_Hybrid_MQB SG_ 1313 STH_war_aktiv 2000;
BA_REL_ "GenSigTimeoutTime" BU_SG_REL_ Motor_Otto_MQB SG_ 1313 STH_war_aktiv 2000;
BA_REL_ "GenSigTimeoutTime" BU_SG_REL_ Motor_Diesel_MQB SG_ 1172 STS_01_CRC 2000;
BA_REL_ "GenSigTimeoutTime" BU_SG_REL_ Motor_Hybrid_MQB SG_ 1172 STS_01_CRC 2000;
BA_REL_ "GenSigTimeoutTime" BU_SG_REL_ Motor_Otto_MQB SG_ 1172 STS_01_CRC 2000;
BA_REL_ "GenSigTimeoutTime" BU_SG_REL_ Motor_Diesel_MQB SG_ 1172 STS_01_BZ 2000;
BA_REL_ "GenSigTimeoutTime" BU_SG_REL_ Motor_Hybrid_MQB SG_ 1172 STS_01_BZ 2000;
BA_REL_ "GenSigTimeoutTime" BU_SG_REL_ Motor_Otto_MQB SG_ 1172 STS_01_BZ 2000;
BA_REL_ "GenSigTimeoutTime" BU_SG_REL_ Motor_Diesel_MQB SG_ 1172 STS_Leerlaufschaltung 2000;
BA_REL_ "GenSigTimeoutTime" BU_SG_REL_ Motor_Hybrid_MQB SG_ 1172 STS_Leerlaufschaltung 2000;
BA_REL_ "GenSigTimeoutTime" BU_SG_REL_ Motor_Otto_MQB SG_ 1172 STS_Leerlaufschaltung 2000;
BA_REL_ "GenSigTimeoutTime" BU_SG_REL_ Motor_Diesel_MQB SG_ 1413 SI_QRS_Mode 5000;
BA_REL_ "GenSigTimeoutTime" BU_SG_REL_ Motor_Hybrid_MQB SG_ 1413 SI_QRS_Mode 5000;
BA_REL_ "GenSigTimeoutTime" BU_SG_REL_ Motor_Otto_MQB SG_ 1413 SI_QRS_Mode 5000;
BA_REL_ "GenSigTimeoutTime" BU_SG_REL_ SAK_MQB SG_ 1413 SI_NWDF 5000;
BA_REL_ "GenSigTimeoutTime" BU_SG_REL_ SAK_MQB SG_ 1413 SI_NWDF_gueltig 5000;
BA_REL_ "GenSigTimeoutTime" BU_SG_REL_ Getriebe_DQ_Hybrid_MQB SG_ 288 TSK_06_CRC 500;
BA_REL_ "GenSigTimeoutTime" BU_SG_REL_ Getriebe_DQ_MQB SG_ 288 TSK_06_CRC 500;
BA_REL_ "GenSigTimeoutTime" BU_SG_REL_ Getriebe_DQ_Hybrid_MQB SG_ 288 TSK_06_BZ 500;
BA_REL_ "GenSigTimeoutTime" BU_SG_REL_ Getriebe_DQ_MQB SG_ 288 TSK_06_BZ 500;
BA_REL_ "GenSigTimeoutTime" BU_SG_REL_ Getriebe_DQ_Hybrid_MQB SG_ 288 TSK_Radbremsmom 500;
BA_REL_ "GenSigTimeoutTime" BU_SG_REL_ Getriebe_DQ_MQB SG_ 288 TSK_Radbremsmom 500;
BA_REL_ "GenSigTimeoutTime" BU_SG_REL_ Getriebe_DQ_Hybrid_MQB SG_ 288 TSK_Status 500;
BA_REL_ "GenSigTimeoutTime" BU_SG_REL_ Getriebe_DQ_MQB SG_ 288 TSK_Status 500;
BA_REL_ "GenSigTimeoutTime" BU_SG_REL_ Getriebe_DQ_Hybrid_MQB SG_ 288 TSK_v_Begrenzung_aktiv 500;
BA_REL_ "GenSigTimeoutTime" BU_SG_REL_ Getriebe_DQ_MQB SG_ 288 TSK_v_Begrenzung_aktiv 500;
BA_REL_ "GenSigTimeoutTime" BU_SG_REL_ Gateway_MQB SG_ 288 TSK_Freig_Verzoeg_Anf 500;
BA_REL_ "GenSigTimeoutTime" BU_SG_REL_ Getriebe_DQ_Hybrid_MQB SG_ 288 TSK_Freig_Verzoeg_Anf 500;
BA_REL_ "GenSigTimeoutTime" BU_SG_REL_ Getriebe_DQ_MQB SG_ 288 TSK_Freig_Verzoeg_Anf 500;
BA_REL_ "GenSigTimeoutTime" BU_SG_REL_ Getriebe_DQ_Hybrid_MQB SG_ 288 TSK_Limiter_ausgewaehlt 500;
BA_REL_ "GenSigTimeoutTime" BU_SG_REL_ Getriebe_DQ_MQB SG_ 288 TSK_Limiter_ausgewaehlt 500;
BA_REL_ "GenSigTimeoutTime" BU_SG_REL_ Getriebe_DQ_Hybrid_MQB SG_ 288 TSK_ax_Getriebe_02 500;
BA_REL_ "GenSigTimeoutTime" BU_SG_REL_ Getriebe_DQ_MQB SG_ 288 TSK_ax_Getriebe_02 500;
BA_REL_ "GenSigTimeoutTime" BU_SG_REL_ Getriebe_DQ_Hybrid_MQB SG_ 288 TSK_zul_Regelabw 500;
BA_REL_ "GenSigTimeoutTime" BU_SG_REL_ Getriebe_DQ_MQB SG_ 288 TSK_zul_Regelabw 500;
BA_REL_ "GenSigTimeoutTime" BU_SG_REL_ Gateway_MQB SG_ 798 TSK_Wunschgeschw 500;
BA_REL_ "GenSigTimeoutTime" BU_SG_REL_ Gateway_MQB SG_ 798 TSK_Status_Anzeige 500;
BA_REL_ "GenSigTimeoutTime" BU_SG_REL_ Airbag_MQB SG_ 1716 VIN_01_MUX 2000;
BA_REL_ "GenSigTimeoutTime" BU_SG_REL_ Airbag_MQB SG_ 1716 VIN_4 2000;
BA_REL_ "GenSigTimeoutTime" BU_SG_REL_ Airbag_MQB SG_ 1716 VIN_11 2000;
BA_REL_ "GenSigTimeoutTime" BU_SG_REL_ Airbag_MQB SG_ 1716 VIN_5 2000;
BA_REL_ "GenSigTimeoutTime" BU_SG_REL_ Airbag_MQB SG_ 1716 VIN_12 2000;
BA_REL_ "GenSigTimeoutTime" BU_SG_REL_ Airbag_MQB SG_ 1716 VIN_6 2000;
BA_REL_ "GenSigTimeoutTime" BU_SG_REL_ Airbag_MQB SG_ 1716 VIN_13 2000;
BA_REL_ "GenSigTimeoutTime" BU_SG_REL_ Airbag_MQB SG_ 1716 VIN_7 2000;
BA_REL_ "GenSigTimeoutTime" BU_SG_REL_ Airbag_MQB SG_ 1716 VIN_14 2000;
BA_REL_ "GenSigTimeoutTime" BU_SG_REL_ Airbag_MQB SG_ 1716 VIN_1 2000;
BA_REL_ "GenSigTimeoutTime" BU_SG_REL_ Airbag_MQB SG_ 1716 VIN_8 2000;
BA_REL_ "GenSigTimeoutTime" BU_SG_REL_ Airbag_MQB SG_ 1716 VIN_15 2000;
BA_REL_ "GenSigTimeoutTime" BU_SG_REL_ Airbag_MQB SG_ 1716 VIN_2 2000;
BA_REL_ "GenSigTimeoutTime" BU_SG_REL_ Airbag_MQB SG_ 1716 VIN_9 2000;
BA_REL_ "GenSigTimeoutTime" BU_SG_REL_ Airbag_MQB SG_ 1716 VIN_16 2000;
BA_REL_ "GenSigTimeoutTime" BU_SG_REL_ Airbag_MQB SG_ 1716 VIN_3 2000;
BA_REL_ "GenSigTimeoutTime" BU_SG_REL_ Airbag_MQB SG_ 1716 VIN_10 2000;
BA_REL_ "GenSigTimeoutTime" BU_SG_REL_ Airbag_MQB SG_ 1716 VIN_17 2000;
BA_REL_ "GenSigTimeoutTime" BU_SG_REL_ Getriebe_DQ_Hybrid_MQB SG_ 175 WH_Status_Sperre 500;
BA_REL_ "GenSigTimeoutTime" BU_SG_REL_ Getriebe_DQ_MQB SG_ 175 WH_Status_Sperre 500;
BA_REL_ "GenSigTimeoutTime" BU_SG_REL_ Getriebe_DQ_Hybrid_MQB SG_ 175 WH_Initialisierung 500;
BA_REL_ "GenSigTimeoutTime" BU_SG_REL_ Getriebe_DQ_MQB SG_ 175 WH_Initialisierung 500;
BA_REL_ "GenSigTimeoutTime" BU_SG_REL_ Getriebe_DQ_Hybrid_MQB SG_ 175 WH_SensorPos_roh 500;
BA_REL_ "GenSigTimeoutTime" BU_SG_REL_ Getriebe_DQ_MQB SG_ 175 WH_SensorPos_roh 500;
BA_REL_ "GenSigTimeoutTime" BU_SG_REL_ Getriebe_DQ_Hybrid_MQB SG_ 175 WH_03_BZ 500;
BA_REL_ "GenSigTimeoutTime" BU_SG_REL_ Getriebe_DQ_MQB SG_ 175 WH_03_BZ 500;
BA_REL_ "GenSigTimeoutTime" BU_SG_REL_ Getriebe_DQ_Hybrid_MQB SG_ 175 WH_SensorPos_roh_inv 500;
BA_REL_ "GenSigTimeoutTime" BU_SG_REL_ Getriebe_DQ_MQB SG_ 175 WH_SensorPos_roh_inv 500;
BA_REL_ "GenSigTimeoutTime" BU_SG_REL_ Getriebe_DQ_Hybrid_MQB SG_ 175 WH_Testergebnis 500;
BA_REL_ "GenSigTimeoutTime" BU_SG_REL_ Getriebe_DQ_MQB SG_ 175 WH_Testergebnis 500;
BA_REL_ "GenSigTimeoutTime" BU_SG_REL_ Getriebe_DQ_Hybrid_MQB SG_ 175 WH_Test_Aktiv 500;
BA_REL_ "GenSigTimeoutTime" BU_SG_REL_ Getriebe_DQ_MQB SG_ 175 WH_Test_Aktiv 500;
BA_REL_ "GenSigTimeoutTime" BU_SG_REL_ Getriebe_DQ_Hybrid_MQB SG_ 175 WH_Status 500;
BA_REL_ "GenSigTimeoutTime" BU_SG_REL_ Getriebe_DQ_MQB SG_ 175 WH_Status 500;
BA_REL_ "GenSigTimeoutTime" BU_SG_REL_ Motor_Diesel_MQB SG_ 916 WBA_eing_Gang_02 1600;
BA_REL_ "GenSigTimeoutTime" BU_SG_REL_ Motor_Otto_MQB SG_ 916 WBA_eing_Gang_02 1600;
VAL_ 812 MO_Prio_MAX_Wunschdrehzahl 0 "Wunsch" 1 "Zwang" ;
VAL_ 812 MO_Prio_MIN_Wunschdrehzahl 0 "Wunsch" 1 "Zwang" ;
VAL_ 812 MO_Luftpfad_aktiv 0 "kein Eingriff oder nur Eingriff über Zündpfad" 1 "Eingriff über Luftpfad" ;
VAL_ 812 MO_v_Begrenz_Aktivierbar 0 "V-Begrenzung nicht möglich" 1 "V-Begrenzung möglich" ;
VAL_ 812 MO_MIN_Wunschdrehzahl 255 "Fehler" ;
VAL_ 812 MO_MAX_Wunschdrehzahl 511 "Fehler" ;
VAL_ 812 MO_Charisma_FahrPr 0 "nicht_belegt" 1 "Programm_1" 2 "Programm_2" 3 "Programm_3" 4 "Programm_4" 5 "Programm_5" 6 "Programm_6" 7 "Programm_7" 8 "Programm_8" 9 "Programm_9" 10 "Programm_10" 11 "Programm_11" 12 "Programm_12" 13 "Programm_13" 14 "Programm_14" 15 "Programm_15" ;
VAL_ 812 MO_Charisma_Status 0 "Init" 1 "verfuegbar" 2 "nicht_verfuegbar" 3 "asynchron_durch_Fahrerwunsch" ;
VAL_ 1648 MO_Hybrid_StartStopp_LED 0 "LED_aus_und_Blinken_aus" 1 "LED_ein_und_Blinken_aus" 2 "LED_ein_und_Blinken_ein_50_percent" 3 "reserviert" ;
VAL_ 1648 MO_Eis_Offroad_LED 0 "LED_aus_und_Blinken_aus" 1 "LED_ein_und_Blinken_aus" 2 "LED_ein_und_Blinken_ein_50_percent" 3 "reserviert" ;
VAL_ 1648 MO_Anzahl_Abgesch_Zyl 0 "Vollmotorbetrieb" 1 "1_Zylinder_abgeschaltet" 2 "2_Zylinder_abgeschaltet" 3 "3_Zylinder_abgeschaltet" 4 "4_Zylinder_abgeschaltet" 5 "5_Zylinder_abgeschaltet" 6 "6_Zylinder_abgeschaltet" 7 "8_Zylinder_abgeschaltet" ;
VAL_ 1648 MO_Zylabsch_Texte 0 "keine_Texte" 1 "Zylinderabschaltung_deaktivieren" 2 "Zylinderabschaltung_aktivieren" 3 "Zylinderabschaltung_unruhig" ;
VAL_ 1648 MO_E85_BS_Texte 0 "kein Text" 1 "FlexFuel Warm_Up_ Lampe" 2 "FlexFuel Warnung 3.Stufe " 3 "FlexFuel Warnung 1.Stufe " 4 "FlexFuel Warnung 2.Stufe " 5 "FlexFuel Warnung 4.Stufe " ;
VAL_ 1648 MO_Drehzahl_Warnung 0 "keinen_Warnhinweis_anzeigen" 1 "Warnhinweis_anzeigen" ;
VAL_ 289 MO_Fahrpedalrohwert_01 255 "Fehler" ;
VAL_ 289 MO_QBit_Fahrpedalwerte_01 0 "gueltiger_Wert" 1 "Ersatz_Init_oder_Fehlerwert" ;
VAL_ 289 MO_Fahrpedalgradient 255 "Fehler" ;
VAL_ 289 MO_Sig_Fahrpedalgradient 0 "Fahrpedalgradient positiv" 1 "Fahrpedalgradient negativ" ;
VAL_ 289 MO_rel_Saugrohrdruck 0 "Init_Ueberdruck" 63 "Fehler" ;
VAL_ 289 MO_rel_Saugrohrdruck_gem_err 0 "errechnet" 1 "gemessen" ;
VAL_ 289 MO_Moment_im_Leerlauf 0 "kein_Leergas" 1 "Leergas" ;
VAL_ 289 MO_Schubabschaltung 0 "keine_Schubabschaltung" 1 "Schubabschaltung_aktiv" ;
VAL_ 289 MO_Solldrehz_Leerlauf 255 "Fehler" ;
VAL_ 967 MO_Kuehlerluefter_MUX 0 "Kuehlerluefter_1" 1 "Kuehlerluefter_2" ;
VAL_ 967 MO_Kuehlerluefter_1 126 "Init" 127 "Fehler" ;
VAL_ 967 MO_Kuehlerluefter_2 126 "Init" 127 "Fehler" ;
VAL_ 967 MO_HYB_Status_HV_Ladung 0 "HV-Ladung_nicht_notwendig" 1 "HV-Ladung_notwendig_Freigaben_erforderlich" 2 "HV-Ladung laeuf" 3 "HV-Ladung_erfolgreich_Motorstart_moeglich" 4 "HV_Ladung_abgebrochen" ;
VAL_ 967 WIV_Anzeige_aktiv 0 "Anzeige aus" 1 "WIV Anzeige aktiv" ;
VAL_ 967 WIV_Oelmin_Warn 0 "in_Ordnung" 1 "Warnung" ;
VAL_ 967 WIV_Sensorfehler 0 "in_Ordnung" 1 "Sensor_defekt" ;
VAL_ 967 WIV_Schieflage 0 "Fahrzeug_gerade" 1 "Fahrzeug_in_Schieflage" ;
VAL_ 967 MO_Zustand_HWP 0 "HWP_nicht_schaltbar" 1 "HWP_foerdert_nicht" 2 "HWP_foerdert" 3 "reserviert" ;
VAL_ 967 WIV_Oelsystem_aktiv 0 "Anzeige_aus" 1 "Anzeige_aktiv" ;
VAL_ 967 WIV_nicht_betriebswarm 0 "Motor_warm" 1 "Motor_nicht_betriebswarm" ;
VAL_ 967 WIV_Ueberfuell_Warn 0 "in_Ordnung" 1 "Ueberfuellwarnung" ;
VAL_ 967 WIV_laufender_Motor 0 "Messung_moeglich" 1 "Messung_nicht_moeglich" ;
VAL_ 967 MO_HYB_Text_1 0 "kein_Text" 1 "Text_anzeigen" ;
VAL_ 967 MO_HYB_Text_2 0 "kein_Text" 1 "Text_anzeigen" ;
VAL_ 967 MO_HYB_Text_3 0 "kein_Text" 1 "Text_anzeigen" ;
VAL_ 967 MO_HYB_Text_4 0 "kein_Text" 1 "Text_anzeigen" ;
VAL_ 967 MO_Text_Motorstart 0 "keine_Anzeige" 1 "Motor_im_Stoppbetrieb" 2 "StartStopp_sicherheitsbedingt_deaktiviert" 3 "System_fordert_Wiederstart" 5 "Motorlauf_noetig" 9 "Unerwuenschter_Motorstillstand" 12 "Motor_startet" 13 "Kupplung_betaetigen" 14 "Waehlhebel_in_PN_Position" 15 "Bremse_treten" ;
VAL_ 967 MO_HYB_Text_5 0 "kein_Text" 1 "Text_anzeigen" ;
VAL_ 967 MO_HYB_Text_6 0 "kein_Text" 1 "Text_anzeigen" ;
VAL_ 967 MO_HYB_Text_7 0 "kein_Text" 1 "Text_anzeigen" ;
VAL_ 967 MO_Systemlampe 0 "Lampe aus" 1 "Lampe ein" ;
VAL_ 967 MO_OBD2_Lampe 0 "Lampe aus" 1 "Lampe ein" ;
VAL_ 967 MO_Heissleuchte 0 "Lampe aus" 1 "Lampe ein" ;
VAL_ 967 MO_Partikel_Lampe 0 "Lampe aus" 1 "Lampe ein" ;
VAL_ 967 WIV_Oelstand_nicht_vorhanden 0 "Ölstand vorhanden" 1 "Ölstand nicht vorhanden" ;
VAL_ 967 WIV_nachfuellanzeige_ein 0 "keine_Nachfuellanzeige" 1 "Nachfuellanzeige" ;
VAL_ 967 WIV_Ueberfuell_deaktiv 0 "Ueberfuellwarnung_am_Kombi_aktiv" 1 "Ueberfuellwarnung_am_Kombi_deaktiv" ;
VAL_ 967 WIV_Unterfuell_Warn 0 "in_Ordnung" 1 "Unterfuellwarnung" ;
VAL_ 967 MO_Tankdeckel_Lampe 0 "Lampe aus" 1 "Lampe ein" ;
VAL_ 967 MO_Text_Tankdeckelwarn 0 "kein Text" 1 "Anzeige Text Tankdeckelwarnung im Kombi" ;
VAL_ 967 WIV_Oeldr_Warn_Motor 0 "keine_Warnung" 1 "niedrige_Oeldruckstufe_nicht_erreicht " ;
VAL_ 1601 MO_Faktor_Momente_02 0 "nicht_belegt" 1 "Faktor_mal_1" 2 "Faktor_mal_2" 3 "Faktor_mal_3" ;
VAL_ 1601 MO_Hybridfahrzeug 0 "kein_Hybridfahrzeug" 1 "Mild_Hybrid" 2 "Full_Hybrid" ;
VAL_ 1601 MO_Getriebe_Code 2 "DL501" 4 "VL381" 10 "AL651" 11 "AL551, AL951, AL1000-8A" 12 "PDK_PAG" 13 "AL551_Hybrid" 15 "Handschalter (konventionell)" 16 "AQ250" 17 "AQ450" 18 "DQ200" 19 "DQ250" 20 "DQ500" 21 "SQ100" 22 "SQ200" ;
VAL_ 1601 MO_StartStopp_Codiert 0 "Start_Stopp_nicht_verbaut" 1 "Start_Stopp_verbaut" ;
VAL_ 1601 MO_Kraftstoffart 0 "Diesel" 1 "Benzin" 2 "CNG" 3 "Erdgas" 4 "Wasserstoff" ;
VAL_ 1601 MO_Ansaugsystem 0 "Turbo" 1 "Sauger" ;
VAL_ 1601 MO_Abgastyp_EOBD 0 "kein_EOBD" 1 "EOBD" ;
VAL_ 1601 MO_Abgastyp_OBD 0 "kein_OBD" 1 "OBD" ;
VAL_ 1601 MO_DPF_verbaut 0 "kein_DPF_verbaut" 1 "DPF_verbaut" ;
VAL_ 1601 TSK_Codierung 0 "kein_Fahrgeschwindigkeitsregler" 1 "GRA" 2 "GRA_Plus" 3 "Basis_ACC" 4 "ACC_Follow_to_Stop" 5 "ACC_Stop_and_Go" 7 "Codierung_in_Plausibilisierungsphase" ;
VAL_ 1601 MO_Einspritzart 0 "MPI" 1 " FSI / TDI" ;
VAL_ 157 MO_HYB_IstStatusK0 0 "auf" 1 "Uebergang" 2 "zu" 3 "Fehler" ;
VAL_ 157 MO_HYB_max_ind_VM_Mom 1022 "Init" 1023 "Fehler" ;
VAL_ 157 MO_HYB_Zielzustand 0 "Init" 1 "Leerlauf_VM" 2 "hybridisch_Fahren" 3 "Fahren_EM" 4 "Fahrbereitschaft_EM" 5 "Fahrbereitschaft_VM" 7 "Fehler" ;
VAL_ 157 MO_HYB_Startmodus 0 "Drag_Start" 1 "slip_start_comf" 2 "slip_start_trq" 3 "slip_start_pwr" 4 "anger_comf" 5 "anger_trq" 6 "anger_pwr" 7 "Impulsstart" ;
VAL_ 157 MO_HYB_Startmodus_PQ3x 0 "Impulsstart" 1 "Direktstart" ;
VAL_ 157 MO_HYB_Stoppmodus 0 "Softstopp" 1 "Dynamikstopp" ;
VAL_ 157 MO_HYB_VM_Mom_oE 1023 "Fehler" ;
VAL_ 157 MO_HYB_VM_aktiv 0 "VM_nicht_aktiv" 1 "VM_aktiv" ;
VAL_ 157 MO_HYB_Schaltverhinderung 0 "keine_Schaltverhinderung" 1 "Schaltverhinderung" ;
VAL_ 157 MO_HYB_Selektor_Momverlauf_EM 0 "keine_Werte" 1 "max_Rekup_Moment" 2 "KnickDZ_Rekup_Kurve" 3 "max_pos_EM_Moment" 4 "KnickDZ_EM_Kurve" ;
VAL_ 811 MO_HYB_E_Faktor 0 "null" 1 "plus_1" 2 "plus_2" 3 "plus_3" 4 "plus_4" 5 "plus_5" 6 "plus_6" 7 "plus_7" 8 "minus_8" 9 "minus_7" 10 "minus_6" 11 "minus_5" 12 "minus_4" 13 "minus_3" 14 "minus_2" 15 "minus_1" ;
VAL_ 811 MO_HYB_Drehzahl_VM 65280 "Fehler" ;
VAL_ 811 MO_HYB_LowSpeedModus 0 "LowSpeed_mit_LLDZ" 1 "LowSpeed_ohne_LLDZ" ;
VAL_ 2600468501 NM_Airbag_01_NM_State 1 "NM_RM_aus_BSM" 2 "NM_RM_aus_PBSM" 4 "NM_NO_aus_RM" 8 "NM_NO_aus_RS" ;
VAL_ 2600468501 NM_Airbag_01_Car_Wakeup 1 "Car_Wakeup" ;
VAL_ 2600468501 NM_Airbag_01_Wakeup 0 "Peripherie_Wakeup__Ursache_nicht_bekannt" 1 "Bus_Wakeup" 2 "KL15_HW" ;
VAL_ 2600468501 NM_Airbag_01_NM_aktiv_KL15 1 "KL15_EIN" ;
VAL_ 2600468501 NM_Airbag_01_NM_aktiv_Diagnose 1 "Diagnose_aktiv" ;
VAL_ 2600468501 NM_Airbag_01_NM_aktiv_Tmin 1 "Mindestaktivzeit" ;
VAL_ 2600468501 NM_Airbag_01_UDS_CC 1 "CC_aktiv" ;
VAL_ 2600468604 NM_EMotor_01_NM_State 1 "NM_RM_aus_BSM" 2 "NM_RM_aus_PBSM" 4 "NM_NO_aus_RM" 8 "NM_NO_aus_RS" ;
VAL_ 2600468604 NM_EMotor_01_Car_Wakeup 1 "Car_Wakeup" ;
VAL_ 2600468604 NM_EMotor_01_Wakeup 0 "Peripherie_Wakeup__Ursache_nicht_bekannt" 1 "Bus_Wakeup" 2 "KL15_HW" ;
VAL_ 2600468604 NM_EMotor_01_NM_aktiv_KL15 1 "KL15_EIN" ;
VAL_ 2600468604 NM_EMotor_01_NM_aktiv_Diagnose 1 "Diagnose_aktiv" ;
VAL_ 2600468604 NM_EMotor_01_NM_aktiv_Tmin 1 "Mindestaktivzeit" ;
VAL_ 2600468604 NM_EMotor_01_NL_Daten_EEPROM 0 "kein_Nachlauf" 1 "EEPROM_Schreibzugriff" ;
VAL_ 2600468604 NM_EMotor_01_UDS_CC 1 "CC_aktiv" ;
VAL_ 2600468496 NM_Gateway_NM_State 1 "NM_RM_aus_BSM" 2 "NM_RM_aus_PBSM" 4 "NM_NO_aus_RM" 8 "NM_NO_aus_RS" ;
VAL_ 2600468496 NM_Gateway_Car_Wakeup 1 "Car_Wakeup" ;
VAL_ 2600468496 NM_Gateway_Wakeup 0 "Peripherie_Wakeup__Ursache_nicht_bekannt" 1 "Bus_Wakeup" 2 "KL15_HW" 3 "ACAN_Wakeup" 4 "FCAN_Wakeup" 5 "KCAN_Wakeup" 6 "ICAN_Wakeup" 7 "DiagCAN_Wakeup" 8 "ECAN_Wakeup" 9 "Energie_LIN_Wakeup" 10 "Bedien_LIN_Wakeup" 128 "Energiemanagement" ;
VAL_ 2600468496 NM_Gateway_NM_aktiv_KL15 1 "KL15_EIN" ;
VAL_ 2600468496 NM_Gateway_NM_aktiv_Diagnose 1 "Diagnose_aktiv" ;
VAL_ 2600468496 NM_Gateway_NM_aktiv_Tmin 1 "Mindestaktivzeit" ;
VAL_ 2600468496 NM_Gateway_ACAN_Aktivitaet 1 "ACAN_Aktivitaet" ;
VAL_ 2600468496 NM_Gateway_FCAN_Aktivitaet 1 "FCAN_Aktivitaet" ;
VAL_ 2600468496 NM_Gateway_KCAN_Aktivitaet 1 "KCAN_Aktivitaet" ;
VAL_ 2600468496 NM_Gateway_ICAN_Aktivitaet 1 "ICAN_Aktivitaet" ;
VAL_ 2600468496 NM_Gateway_DiagCAN_Aktivitaet 1 "DiagCAN_Aktivitaet" ;
VAL_ 2600468496 NM_Gateway_ECAN_Aktivitaet 1 "ECAN_Aktivitaet" ;
VAL_ 2600468496 NM_Gateway_Energie_LIN_Aktivi000 1 "Energie_LIN_Aktivitaet" ;
VAL_ 2600468496 NM_Gateway_Bedien_LIN_Aktivitaet 1 "Bedien_LIN_Aktivitaet" ;
VAL_ 2600468496 NM_Gateway_EM_Aktivitaet 1 "EM_Aktivitaet" ;
VAL_ 2600468496 NM_Gateway_NL_EM 1 "Energiemanagement" ;
VAL_ 2600468496 NM_Gateway_NL_Shutdown 1 "Shutdown" ;
VAL_ 2600468496 NM_Gateway_NL_Spg_Messung 1 "Spannungsmessung" ;
VAL_ 2600468496 NM_Gateway_NL_Wakeup_Monitor 1 "Wakeup_Monitor" ;
VAL_ 2600468496 NM_Gateway_UDS_CC 1 "CC_aktiv" ;
VAL_ 2600468599 NM_Getriebe_01_NM_State 1 "NM_RM_aus_BSM" 2 "NM_RM_aus_PBSM" 4 "NM_NO_aus_RM" 8 "NM_NO_aus_RS" ;
VAL_ 2600468599 NM_Getriebe_01_Car_Wakeup 1 "Car_Wakeup" ;
VAL_ 2600468599 NM_Getriebe_01_Wakeup 0 "Peripherie_Wakeup__Ursache_nicht_bekannt" 1 "Bus_Wakeup" 2 "KL15_HW" ;
VAL_ 2600468599 NM_Getriebe_01_NM_aktiv_KL15 1 "KL15_EIN" ;
VAL_ 2600468599 NM_Getriebe_01_NM_aktiv_Diagnose 1 "Diagnose_aktiv" ;
VAL_ 2600468599 NM_Getriebe_01_NM_aktiv_Tmin 1 "Mindestaktivzeit" ;
VAL_ 2600468599 NM_Getriebe_01_NM_aktiv_v_gr_0 1 "v_groesser_0" ;
VAL_ 2600468599 NM_Getriebe_01_NM_aktiv_Pos_Erk 1 "Positionserkennung_Waehlhebel" ;
VAL_ 2600468599 NM_Getriebe_01_NM_aktiv_Umg_Bed 1 "Lesen_Umgebungsbedingungen" ;
VAL_ 2600468599 NM_Getriebe_01_NL_Daten_EEPROM 0 "kein_Nachlauf" 1 "EEPROM_Schreibzugriff" ;
VAL_ 2600468599 NM_Getriebe_01_UDS_CC 1 "CC_aktiv" ;
VAL_ 2600468603 NM_Hybrid_01_NM_State 1 "NM_RM_aus_BSM" 2 "NM_RM_aus_PBSM" 4 "NM_NO_aus_RM" 8 "NM_NO_aus_RS" ;
VAL_ 2600468603 NM_Hybrid_01_Car_Wakeup 1 "Car_Wakeup" ;
VAL_ 2600468603 NM_Hybrid_01_Wakeup 0 "Peripherie_Wakeup__Ursache_nicht_bekannt" 1 "Bus_Wakeup" 2 "KL15_HW" ;
VAL_ 2600468603 NM_Hybrid_01_NM_aktiv_KL15 1 "KL15_EIN" ;
VAL_ 2600468603 NM_Hybrid_01_NM_aktiv_Diagnose 1 "Diagnose_aktiv" ;
VAL_ 2600468603 NM_Hybrid_01_NM_aktiv_Tmin 1 "Mindestaktivzeit" ;
VAL_ 2600468603 NM_Hybrid_01_NL_Daten_EEPROM 0 "kein_Nachlauf" 1 "EEPROM_Schreibzugriff" ;
VAL_ 2600468603 NM_Hybrid_01_NL_Luefter 0 "kein_Nachlauf" 1 "Luefter_aktiv" ;
VAL_ 2600468603 NM_Hybrid_01_UDS_CC 1 "CC_aktiv" ;
VAL_ 2600468598 NM_MO_01_NM_State 1 "NM_RM_aus_BSM" 2 "NM_RM_aus_PBSM" 4 "NM_NO_aus_RM" 8 "NM_NO_aus_RS" ;
VAL_ 2600468598 NM_MO_01_Car_Wakeup 1 "Car_Wakeup" ;
VAL_ 2600468598 NM_MO_01_Wakeup 0 "Peripherie_Wakeup__Ursache_nicht_bekannt" 1 "Bus_Wakeup" 2 "KL15_HW" ;
VAL_ 2600468598 NM_MO_01_NM_aktiv_KL15 1 "KL15_EIN" ;
VAL_ 2600468598 NM_MO_01_NM_aktiv_Diagnose 1 "Diagnose_aktiv" ;
VAL_ 2600468598 NM_MO_01_NM_aktiv_Tmin 1 "Mindestaktivzeit" ;
VAL_ 2600468598 NM_MO_01_NM_aktiv_HV_Abschaltung 0 "kein_Nachlauf" 1 "Abschaltung_aktiv" ;
VAL_ 2600468598 NM_MO_01_NM_aktiv_EKP_Vorlauf 0 "kein_Nachlauf" 1 "EKP_Vorlauf" ;
VAL_ 2600468598 NM_MO_01_NM_aktiv_STH_Betrieb 0 "kein_Nachlauf" 1 "Standheizungsbetrieb" ;
VAL_ 2600468598 NM_MO_01_NL_Kuehlerluefter 0 "kein_Nachlauf" 1 "Kuehlerluefter_Strg_ZWP_aktiv" ;
VAL_ 2600468598 NM_MO_01_NL_Diagnose 0 "kein_Nachlauf" 1 "Diagnosefunktionen_aktiv" ;
VAL_ 2600468598 NM_MO_01_NL_WFS 0 "kein_Nachlauf" 1 "WFS_aktiv" ;
VAL_ 2600468598 NM_MO_01_NL_EEPROM 0 "kein_Nachlauf" 1 "EEPROM_Zugriffe_RAM_ROM_Tests" ;
VAL_ 2600468598 NM_MO_01_NL_Sonstige 0 "kein_Nachlauf" 1 "Sonstige_Nachlaeufe_aktiv" ;
VAL_ 2600468598 NM_MO_01_UDS_CC 1 "CC_aktiv" ;
VAL_ 913 OBD_Kaltstart_Denominator 0 "Denominator_nicht_hochzaehlen" 1 "Bedingungen_zum_Inkr_des_Kaltstart_Denom_erf" ;
VAL_ 913 OBD_Minimum_Trip 0 "kein_Min_Normed_Trip" 1 "Min_Normed_Trip" ;
VAL_ 913 OBD_Driving_Cycle 0 "kein Driving Cycle erkannt" 1 "DC erkannt" ;
VAL_ 913 OBD_Warm_Up_Cycle 0 "kein Warm Up Cycle erkannt" 1 "Warm Up Cycle erkannt" ;
VAL_ 913 OBD_Normed_Trip 0 "kein Normed Trip" 1 "Normed Trip erfüllt" ;
VAL_ 1630 OBD_TG_F_Status_1 0 "kein Fehler / Init / nicht verbaut" 1 "KS-" 2 "KS+ (B8: nicht bedient)" 3 "OC (Leitungsunterbrechung) (B8: nicht bedient)" 4 "OOR+ (out of range high) (B8: nicht bedient)" 5 "OOR- (out of range low) (B8: nicht bedient)" 6 "RC+ (Signal unplausibel hoch) (B8: nicht bedient)" 7 "RC- (Signal unplausibel niedrig) (B8: nicht bedient)" 8 "KS+/OC" 9 "KS-/OC (B8: nicht bedient)" 10 "KS-/KS+ (B8: nicht bedient)" 11 "KS-/KS+/OC (allgemeiner Fehler)" 12 "frei" 13 "frei" 14 "frei" 15 "frei" ;
VAL_ 1630 OBD_TG_F_Status_2 0 "kein Fehler / Init / nicht verbaut" 1 "KS-" 2 "KS+ (B8: nicht bedient)" 3 "OC (Leitungsunterbrechung) (B8: nicht bedient)" 4 "OOR+ (out of range high) (B8: nicht bedient)" 5 "OOR- (out of range low) (B8: nicht bedient)" 6 "RC+ (Signal unplausibel hoch) (B8: nicht bedient)" 7 "RC- (Signal unplausibel niedrig) (B8: nicht bedient)" 8 "KS+/OC" 9 "KS-/OC (B8: nicht bedient)" 10 "KS-/KS+ (B8: nicht bedient)" 11 "KS-/KS+/OC (allgemeiner Fehler)" 12 "frei" 13 "frei" 14 "frei" 15 "frei" ;
VAL_ 1630 OBD_TG_F_Status_3 0 "kein Fehler / Init / nicht verbaut" 1 "KS-" 2 "KS+ (B8: nicht bedient)" 3 "OC (Leitungsunterbrechung) (B8: nicht bedient)" 4 "OOR+ (out of range high) (B8: nicht bedient)" 5 "OOR- (out of range low) (B8: nicht bedient)" 6 "RC+ (Signal unplausibel hoch) (B8: nicht bedient)" 7 "RC- (Signal unplausibel niedrig) (B8: nicht bedient)" 8 "KS+/OC" 9 "KS-/OC (B8: nicht bedient)" 10 "KS-/KS+ (B8: nicht bedient)" 11 "KS-/KS+/OC (allgemeiner Fehler)" 12 "frei" 13 "frei" 14 "frei" 15 "frei" ;
VAL_ 1630 OBD_TG_F_Status_4 0 "kein Fehler / Init / nicht verbaut" 1 "KS-" 2 "KS+ (B8: nicht bedient)" 3 "OC (Leitungsunterbrechung) (B8: nicht bedient)" 4 "OOR+ (out of range high) (B8: nicht bedient)" 5 "OOR- (out of range low) (B8: nicht bedient)" 6 "RC+ (Signal unplausibel hoch) (B8: nicht bedient)" 7 "RC- (Signal unplausibel niedrig) (B8: nicht bedient)" 8 "KS+/OC" 9 "KS-/OC (B8: nicht bedient)" 10 "KS-/KS+ (B8: nicht bedient)" 11 "KS-/KS+/OC (allgemeiner Fehler)" 12 "frei" 13 "frei" 14 "frei" 15 "frei" ;
VAL_ 984 RGS_VL_Texte 0 "kein_Fehler" 1 "PreCrashSystem_nicht_verfuegbar" 2 "PreCrashFunktion_eingeschraenkt" ;
VAL_ 984 RGS_VL_Charisma_FahrPr 0 "nicht_belegt" 1 "Programm_1" 2 "Programm_2" 3 "Programm_3" 4 "Programm_4" 5 "Programm_5" 6 "Programm_6" 7 "Programm_7" 8 "Programm_8" 9 "Programm_9" 10 "Programm_10" 11 "Programm_11" 12 "Programm_12" 13 "Programm_13" 14 "Programm_14" 15 "Programm_15" ;
VAL_ 984 RGS_VL_Charisma_Status 0 "Init" 1 "verfuegbar" 2 "nicht_verfuegbar" 3 "asynchron_durch_Fahrerwunsch" ;
VAL_ 984 RGS_VL_aktiv 0 "Aktuator_nicht_aktiv" 1 "Aktuator_aktiv" ;
VAL_ 984 RGS_VL_PC_Aktuator_Sitz 0 "Sitz_nicht_ansteuern" 1 "Sitz_ansteuern" ;
VAL_ 984 RGS_VL_PC_Aktuator_Schiebedach 0 "Schiebedach_nicht_ansteuern" 1 "Schiebedach_ansteuern" ;
VAL_ 984 RGS_VL_PC_Aktuator_Fenster 0 "Fenster_nicht_ansteuern" 1 "Fenster_ansteuern" ;
VAL_ 984 RGS_VL_PC_Aktuator_Warnblinken 0 "Warnblinken_nicht_ansteuern" 1 "Warnblinken_ansteuern" ;
VAL_ 984 RGS_VL_Precrash_Basis 0 "Init" 1 "Schwelle_1" 2 "Schwelle_2" 4 "Schwelle_3" ;
VAL_ 984 RGS_VL_Precrash_Front 0 "Init" 1 "Schwelle_1" 2 "Schwelle_2" ;
VAL_ 984 RGS_VL_Precrash_Rear 0 "Init" 1 "Schwelle_1" 2 "Schwelle_2" ;
VAL_ 1528 SAK_Charisma_FahrPr 0 "nicht_belegt" 1 "Programm_1" 2 "Programm_2" 3 "Programm_3" 4 "Programm_4" 5 "Programm_5" 6 "Programm_6" 7 "Programm_7" 8 "Programm_8" 9 "Programm_9" 10 "Programm_10" 11 "Programm_11" 12 "Programm_12" 13 "Programm_13" 14 "Programm_14" 15 "Programm_15" ;
VAL_ 1528 SAK_Charisma_Status 0 "Init" 1 "verfuegbar" 2 "nicht_verfuegbar" 3 "asynchron_durch_Fahrerwunsch" ;
VAL_ 1313 STH_Funk_ein 0 "kein Funkbefehl zum Einschalten" 1 "Funkbefehl zum Einschalten erhalten" ;
VAL_ 1313 STH_Funk_aus 0 "kein Funkbefehl" 1 "Funkbefehl zum Ausschalten erhalten" ;
VAL_ 1313 STH_Zusatzheizung 0 "Zuheizer aus" 1 "Zuheizer ein" ;
VAL_ 1313 STH_LED 0 "keine Rückmeldung" 1 "Rueckmeldung Standheizung in Betrieb" ;
VAL_ 1313 STH_Geblaese 0 "kein Einschaltbefehl an die Klimaanlage, Gebläse" 1 "Einschaltbefehl an die Klimaanlage, Gebläse" ;
VAL_ 1313 STH_EKP_Anst 0 "EKP nicht ansteuern" 1 "EKP ansteuern" ;
VAL_ 1313 STH_Start_folgt 0 "kein_Start_folgt" 1 "Start_folgt" ;
VAL_ 1313 STH_Ventil_Status 0 "Ventil_offen__grosser_Kreislauf" 1 "Ventil_geschlossen__kleiner_Kreislauf" ;
VAL_ 1313 STH_Fehlerstatus 0 "kein Fehler" 1 "Batterie Low" 2 "Fuel Low" 3 "Hardware defekt" 4 "Heizgeraet verriegelt" ;
VAL_ 1313 STH_Wassertemp 254 "Init" 255 "Fehler" ;
VAL_ 1313 STH_Motorvorwaermung 0 "keine Motorvorwärmung erfolgt" 1 "Aufheizung mit Motorvorwärmung erfolgt" ;
VAL_ 1313 STH_war_aktiv 0 "war inaktiv" 1 "Standheizung war letzte halbe Stunde aktiv" ;
VAL_ 1313 STH_KVS_Ueberlauf 0 "kein Überlauf" 1 "Kraftstoffverbrauchssignal, mindestens ein Überlauf hat stattgefunden" ;
VAL_ 1313 STH_KD_Fehler 0 "kein_KD_Fehler" 1 "KD_Fehler" ;
VAL_ 1172 STS_Car_not_under_theft 0 "false" 1 "true" ;
VAL_ 1172 STS_Car_under_theft 0 "false" 1 "true" ;
VAL_ 1172 STS_Anlassersperre 0 "inaktiv" 1 "aktiv" ;
VAL_ 1172 STS_Typencodierung 0 "Basis" 1 "E-Gas" 4 "Sonderschutz" ;
VAL_ 1172 STS_Standlicht 0 "inaktiv" 1 "aktiv" ;
VAL_ 1172 STS_Fahrlicht 0 "inaktiv" 1 "aktiv" ;
VAL_ 1172 STS_Alarm_still 0 "inaktiv" 1 "aktiv" ;
VAL_ 1172 STS_Texte 0 "kein_Text" 1 "Text_01" 2 "Text_02" 3 "Text_03" 4 "Text_04" 5 "Text_05" 6 "Text_06" 7 "Text_07" 8 "Text_08" 9 "Text_09" 10 "Text_10" 11 "Text_11" 12 "Text_12" 13 "Text_13" 14 "Init" 15 "Fehler" ;
VAL_ 1172 STS_Laderelais 0 "Relais_offen" 1 "Relais_geschlossen" ;
VAL_ 1172 STS_Summer 0 "inaktiv" 1 "aktiv" ;
VAL_ 1172 STS_Notstart 0 "kein_Notstart" 1 "Notstart" ;
VAL_ 1172 STS_Signalhorn 0 "inaktiv" 1 "aktiv" ;
VAL_ 1172 STS_Leerlaufschaltung 0 "Leerlaufschaltung_Aus" 1 "Leerlaufschaltung_Ein" ;
VAL_ 1413 SI_Sammel_SG_Fehler 61 "Reserviert" 62 "Overflow" ;
VAL_ 1413 SI_Rollenmode 0 "aus" 1 "Start" 2 "aktiv" 3 "Fehler" ;
VAL_ 1413 SI_QRS_Mode 0 "QRS_Messmodus_nicht_aktiv" 1 "QRS_Messmodus_aktiv" ;
VAL_ 1413 SI_T_Mode 0 "Transportmodus_nicht_aktiv" 1 "Transportmodus_aktiv" ;
VAL_ 1413 SI_NWDF 0 "Ueberwachung_nicht_freigegeben" 1 "Ueberwachung_freigegeben" ;
VAL_ 1413 SI_NWDF_gueltig 0 "NWDF_wird_nicht_unterstuetzt" 1 "NWDF_wird_unterstuetzt" ;
VAL_ 1413 SI_Sammelfehler 0 "kein_Sammelfehler" 1 "Sammelfehler" ;
VAL_ 1413 GW_KD_Fehler 0 "kein_KD_Fehler" 1 "KD_Fehler" ;
VAL_ 1413 SI_BUS_01 0 "keine_Busruhe" 1 "Busruhe" ;
VAL_ 1413 SI_BUS_02 0 "keine_Busruhe" 1 "Busruhe" ;
VAL_ 1413 SI_BUS_03 0 "keine_Busruhe" 1 "Busruhe" ;
VAL_ 1413 SI_BUS_04 0 "keine_Busruhe" 1 "Busruhe" ;
VAL_ 1413 SI_BUS_05 0 "keine_Busruhe" 1 "Busruhe" ;
VAL_ 1413 SI_BUS_06 0 "keine_Busruhe" 1 "Busruhe" ;
VAL_ 1413 SI_BUS_07 0 "keine_Busruhe" 1 "Busruhe" ;
VAL_ 1413 SI_BUS_08 0 "keine_Busruhe" 1 "Busruhe" ;
VAL_ 1413 SI_BUS_09 0 "keine_Busruhe" 1 "Busruhe" ;
VAL_ 1413 SI_BUS_10 0 "keine_Busruhe" 1 "Busruhe" ;
VAL_ 1413 SI_BUS_11 0 "keine_Busruhe" 1 "Busruhe" ;
VAL_ 1413 SI_BUS_12 0 "keine_Busruhe" 1 "Busruhe" ;
VAL_ 1413 SI_BUS_13 0 "keine_Busruhe" 1 "Busruhe" ;
VAL_ 1413 SI_BUS_14 0 "keine_Busruhe" 1 "Busruhe" ;
VAL_ 1413 SI_BUS_15 0 "keine_Busruhe" 1 "Busruhe" ;
VAL_ 288 TSK_Status 0 "Hauptschalter_aus" 1 "Init" 2 "passiv" 3 "aktiv" 4 "Uebertreten" 5 "brake_only_Mode" 6 "reversibel_aus" 7 "irreversibel_aus" ;
VAL_ 288 TSK_v_Begrenzung_aktiv 0 "inaktiv" 1 "aktiv" ;
VAL_ 288 TSK_Standby_Anf_ESP 0 "keine Standby-Anforderung" 1 "Standby-Anforderung" ;
VAL_ 288 TSK_Freig_Verzoeg_Anf 0 "Verzoegerungsanforderung_nicht_freigegeben" 1 "Verzoegerungsanforderung_freigegeben" ;
VAL_ 288 TSK_Limiter_ausgewaehlt 0 "kein_Limiter_ausgewaehlt" 1 "Limiter_ausgewaehlt" ;
VAL_ 288 TSK_ax_Getriebe_02 511 "Neutralwert" ;
VAL_ 288 TSK_Zwangszusch_ESP 0 "keine_ESP_ASR_Beeinflussung" 1 "ESP_ASR_Beeinflussung" ;
VAL_ 798 TSK_Wunschgeschw 1022 "keine_Anzeige" 1023 "kein_Wert_im_Speicher" ;
VAL_ 798 TSK_Texte_Primaeranz 0 "keine_Anzeige" 1 "GRA_Symbol_passiv_xxx_kmh_mph" 2 "GRA_Symbol_aktiv_xxx_kmh_mph" 3 "Bremse_ueberhitzt" 4 "Limiter_Modus_aktiviert" 5 "GRA_Modus_aktiviert" 6 "ACC_Modus_aktiviert" 7 "Opt_Geschwindigkeitswarnung" 8 "Opt_und_akustische_GeschwWarnung" 9 "Opt_GeschwWarnung_dauerhaft_mit_einmal_Akustik" 10 "Limiter_passiv_mit_Akustik" 11 "Limiter_Fehler_mit_Akustik" 12 "Limiter_Symbol_passiv_xxx_kmh_mph" 13 "Limiter_Symbol_aktiv_xxx_kmh_mph" ;
VAL_ 798 TSK_Limiter_Anzeige 0 "Display_Anzeige_GRA_ACC" 1 "Display_Anzeige_Limiter" ;
VAL_ 798 TSK_Status_Anzeige 0 "Hauptschalter_aus" 1 "Init" 2 "passiv" 3 "aktiv" 4 "Uebertreten" 5 "reserviert" 6 "reversibel_aus" 7 "irreversibel_aus" ;
VAL_ 175 WH_Status_Sperre 0 "Init" 1 "WH_gesperrt" 2 "WH_offen" 3 "WH_gesperrt" 6 "SL_nicht_verbaut" 7 "Fehler" ;
VAL_ 175 WH_Initialisierung 0 "keine Initphase" 1 "Initphase" ;
VAL_ 175 WH_SensorPos_roh 0 "Init" 1 "Position_1" 2 "Position_2" 3 "Position_3" 4 "Position_4" 5 "Position_D" 6 "Position_N" 7 "Position_R" 8 "Position_P" 9 "Position_N_ohne_Spotausleuchtung" 10 "Position_Tipp_+" 11 "Position_Tipp_-" 12 "Position_S" 13 "Position_L" 14 "Position_Tipp_Gasse" 15 "Fehler" ;
VAL_ 175 WH_SensorPos_roh_inv 0 "Fehler" 1 "Position_Tipp_Gasse" 2 "Position_L" 3 "Position_S" 4 "Position_Tipp_-" 5 "Position_Tipp_+" 6 "Position_N_ohne_Spotausleuchtung" 7 "Position_P" 8 "Position_R" 9 "Position_N" 10 "Position_D" 11 "Position_4" 12 "Position_3" 13 "Position_2" 14 "Position_1" 15 "Init" ;
VAL_ 175 WH_Test_Aktiv 0 "kein Testergebnis" 1 "Testergebnis" ;
VAL_ 175 WH_Status 0 "fehlerfrei" 1 "sonstiger Fehler" 2 "Rueckfahrlicht Unterbrechung / KS nach Masse" 4 "Rueckfahrlicht KS nach Plus" 32 "Betrieb auf Redundanzbasis" 64 "Fahrerwunsch nicht interpretierbar" ;
VAL_ 916 WBA_Fahrstufe_02 0 "Zwischenstellung_keine_Position" 1 "Position_P" 2 "Position_R" 3 "Position_N" 4 "Position_D" 5 "Position_S" 6 "Position_M_Tippfunktion" 7 "Kurzzeit_M" 8 "Position_E" ;
VAL_ 916 WBA_ZielFahrstufe 0 "keine_Gangempfehlung_kein_Gang_eingelegt" 1 "Pfeil_nach_S" 2 "Pfeil_nach_D" 3 "Pfeil_nach_M" 4 "Pfeil_nach_E" ;
VAL_ 916 WBA_GE_Warnung_02 0 "keine_Anzeige" 1 "Fehlereskalationsstufe_I" 2 "Fehlereskalationsstufe_II" 3 "Weiterfahrt nur eingeschränkt möglich. Kein R-Gang" 4 "Getriebefehler, Weiterfahrt nur in D moeglich, P bei Motor aus" 5 "Wegrollgefahr! P nicht möglich" 6 "Getriebeüberhitzung_Warnstufe_I" 7 "Getriebeüberhitzung_Warnstufe_II" ;
VAL_ 916 WBA_eing_Gang_02 0 "keine_Ganganzeige" 1 "Gang_1" 2 "Gang_2" 3 "Gang_3" 4 "Gang_4" 5 "Gang_5" 6 "Gang_6" 7 "Gang_7" 8 "Gang_8" 9 "Gang_9" 10 "Funktion_Ganganzeigeunterdrueckung" ;
VAL_ 916 WBA_GE_Texte 0 "keine_Anzeige" 1 "zum_Einlegen_einer_Fahrstufe_Fussbremse_betaetigen__ShiftLock_Information" 2 "zum_Einlegen_von_R,N,D_Fussbremse_betaetigen_und_Motor_starten" 3 "Wegrollgefahr_bitte_P_einlegen" 4 "Achtung_Zeitueberschreitung_P_wird_eingelegt" 5 "Bremse_betaetigen" 6 "P_nur_im_Stillstand_moeglich" ;
VAL_ 916 WBA_Segeln_aktiv 0 "inaktiv" 1 "aktiv" ;
VAL_ 916 WBA_Schaltschema 0 "kein_Schaltschema" 1 "xxxD(S)" 2 "xxxD_S" 3 "xxxS(D)" 4 "xxxS_D" 5 "xxxM(D)" 6 "xxxM_D" 7 "xxxM(S)" 8 "xxxM_S" 9 "xxxE(D)" 10 "xxxE_D" 11 "xxxE(S)" 12 "xxxE_S" 13 "xxxE(M)" 14 "xxxE_M" ;
VAL_ 1602 WIV_Verschleissindex 65535 "Fehler" ;
VAL_ 1602 WIV_Russindex 65535 "Fehler" ;
